VERSION ""

NS_ :

BS_:

BU_: DMC

BO_ 3221225472 VECTOR__INDEPENDENT_SIG_MSG: 0 Vector__XXX
 SG_ ICM_Cyc100_Fuel_State : 0|2@0+ (1,0) [0|3] "" Vector__XXX

BO_ 1944 Diag_DMC_RES: 8 DMC
 SG_ Diag_DMC_RES : 7|64@0+ (1,0) [0|0] "" Vector__XXX

BO_ 1928 Diag_DMC_REQ: 8 Vector__XXX
 SG_ Diag_DMC_REQ : 7|64@0+ (1,0) [0|0] ""  DMC

BO_ 2015 DIAG_OBD_REQ_Broadcast: 8 Vector__XXX
 SG_ DIAG_OBD_REQ_Broadcast : 7|64@0+ (1,0) [0|0] ""  DMC

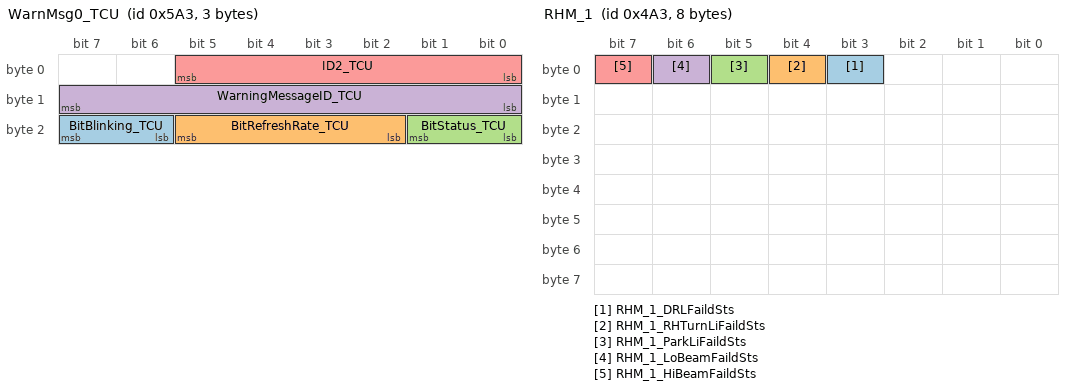
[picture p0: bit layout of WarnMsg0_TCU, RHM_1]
BO_ 1443 WarnMsg0_TCU: 3 Vector__XXX
 SG_ BitBlinking_TCU : 23|2@0+ (1,0) [0|3] ""  DMC
 SG_ BitRefreshRate_TCU : 21|4@0+ (1,0) [0|14] "second"  DMC
 SG_ BitStatus_TCU : 17|2@0+ (1,0) [0|3] ""  DMC
 SG_ WarningMessageID_TCU : 15|8@0+ (1,0) [0|255] ""  DMC
 SG_ ID2_TCU : 5|6@0+ (1,0) [0|63] ""  DMC

BO_ 798 TMR_2: 8 Vector__XXX
 SG_ TMR_TMRSysFault : 8|1@0+ (1,0) [0|1] ""  DMC

BO_ 1230 TMF_9: 8 Vector__XXX
 SG_ TMF_MILSts : 19|2@0+ (1,0) [0|3] ""  DMC

BO_ 789 TMF_2: 8 Vector__XXX
 SG_ TMF_SpdAct : 39|16@0+ (1,-32767) [-32767|32767] "rpm"  DMC
 SG_ TMF_TMFSysFault : 8|1@0+ (1,0) [0|1] ""  DMC

BO_ 1187 RHM_1: 8 Vector__XXX
 SG_ RHM_1_DRLFaildSts : 3|1@0+ (1,0) [0|1] ""  DMC
 SG_ RHM_1_RHTurnLiFaildSts : 4|1@0+ (1,0) [0|1] ""  DMC
 SG_ RHM_1_ParkLiFaildSts : 5|1@0+ (1,0) [0|1] ""  DMC
 SG_ RHM_1_LoBeamFaildSts : 6|1@0+ (1,0) [0|1] ""  DMC
 SG_ RHM_1_HiBeamFaildSts : 7|1@0+ (1,0) [0|1] ""  DMC

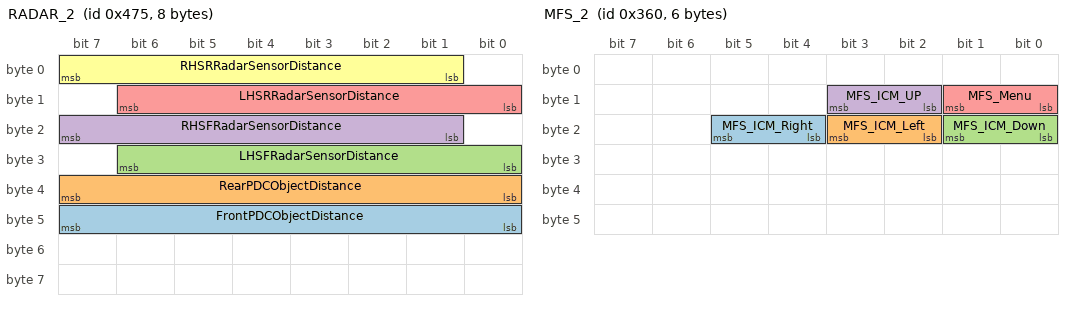
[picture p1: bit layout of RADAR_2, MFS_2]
BO_ 1141 RADAR_2: 8 Vector__XXX
 SG_ FrontPDCObjectDistance : 47|8@0+ (1,0) [0|120] "cm"  DMC
 SG_ RearPDCObjectDistance : 39|8@0+ (1,0) [0|150] "cm"  DMC
 SG_ LHSFRadarSensorDistance : 30|7@0+ (5,30) [30|500] "cm"  DMC
 SG_ RHSFRadarSensorDistance : 23|7@0+ (5,30) [30|500] "cm"  DMC
 SG_ LHSRRadarSensorDistance : 14|7@0+ (5,30) [30|500] "cm"  DMC
 SG_ RHSRRadarSensorDistance : 7|7@0+ (5,30) [30|500] "cm"  DMC

BO_ 864 MFS_2: 6 Vector__XXX
 SG_ MFS_ICM_Right : 21|2@0+ (1,0) [0|3] ""  DMC
 SG_ MFS_ICM_Left : 19|2@0+ (1,0) [0|3] ""  DMC
 SG_ MFS_ICM_Down : 17|2@0+ (1,0) [0|3] ""  DMC
 SG_ MFS_ICM_UP : 11|2@0+ (1,0) [0|3] ""  DMC
 SG_ MFS_Menu : 9|2@0+ (1,0) [0|3] ""  DMC

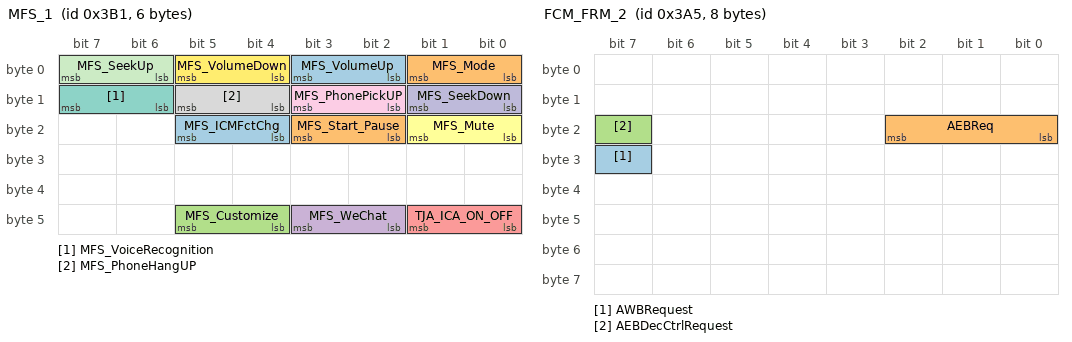
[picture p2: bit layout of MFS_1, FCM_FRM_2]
BO_ 945 MFS_1: 6 Vector__XXX
 SG_ MFS_ICMFctChg : 21|2@0+ (1,0) [0|3] ""  DMC
 SG_ MFS_Start_Pause : 19|2@0+ (1,0) [0|3] ""  DMC
 SG_ MFS_Customize : 45|2@0+ (1,0) [0|3] ""  DMC
 SG_ MFS_WeChat : 43|2@0+ (1,0) [0|3] ""  DMC
 SG_ TJA_ICA_ON_OFF : 41|2@0+ (1,0) [0|3] ""  DMC
 SG_ MFS_Mute : 17|2@0+ (1,0) [0|3] ""  DMC
 SG_ MFS_VoiceRecognition : 15|2@0+ (1,0) [0|3] ""  DMC
 SG_ MFS_PhoneHangUP : 13|2@0+ (1,0) [0|3] ""  DMC
 SG_ MFS_PhonePickUP : 11|2@0+ (1,0) [0|3] ""  DMC
 SG_ MFS_SeekDown : 9|2@0+ (1,0) [0|3] ""  DMC
 SG_ MFS_SeekUp : 7|2@0+ (1,0) [0|3] ""  DMC
 SG_ MFS_VolumeDown : 5|2@0+ (1,0) [0|3] ""  DMC
 SG_ MFS_VolumeUp : 3|2@0+ (1,0) [0|3] ""  DMC
 SG_ MFS_Mode : 1|2@0+ (1,0) [0|3] ""  DMC

BO_ 777 ISGF_2: 8 Vector__XXX
 SG_ ISGF_ISGFSysFault : 8|1@0+ (1,0) [0|1] ""  DMC

BO_ 933 FCM_FRM_2: 8 Vector__XXX
 SG_ AWBRequest : 31|1@0+ (1,0) [0|1] ""  DMC
 SG_ AEBReq : 18|3@0+ (1,0) [0|7] ""  DMC
 SG_ AEBDecCtrlRequest : 23|1@0+ (1,0) [0|1] ""  DMC

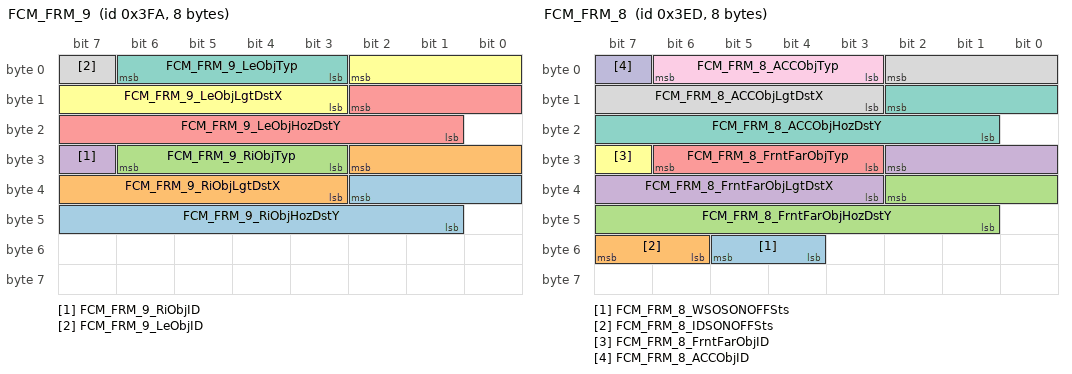
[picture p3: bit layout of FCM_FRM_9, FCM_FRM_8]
BO_ 1018 FCM_FRM_9: 8 Vector__XXX
 SG_ FCM_FRM_9_RiObjHozDstY : 34|10@0+ (0.1,-50) [-50|50] "m"  DMC
 SG_ FCM_FRM_9_RiObjLgtDstX : 26|8@0+ (0.5,0) [0|127] "m"  DMC
 SG_ FCM_FRM_9_RiObjTyp : 30|4@0+ (1,0) [0|15] ""  DMC
 SG_ FCM_FRM_9_RiObjID : 31|1@0+ (1,0) [0|1] ""  DMC
 SG_ FCM_FRM_9_LeObjHozDstY : 10|10@0+ (0.1,-50) [-50|50] "m"  DMC
 SG_ FCM_FRM_9_LeObjLgtDstX : 2|8@0+ (0.5,0) [0|127] "m"  DMC
 SG_ FCM_FRM_9_LeObjTyp : 6|4@0+ (1,0) [0|15] ""  DMC
 SG_ FCM_FRM_9_LeObjID : 7|1@0+ (1,0) [0|1] ""  DMC

BO_ 1005 FCM_FRM_8: 8 Vector__XXX
 SG_ FCM_FRM_8_WSOSONOFFSts : 53|2@0+ (1,0) [0|2] ""  DMC
 SG_ FCM_FRM_8_IDSONOFFSts : 55|2@0+ (1,0) [0|3] ""  DMC
 SG_ FCM_FRM_8_FrntFarObjHozDstY : 34|10@0+ (0.1,-50) [-50|50] "m"  DMC
 SG_ FCM_FRM_8_FrntFarObjLgtDstX : 26|8@0+ (0.5,0) [0|127] "m"  DMC
 SG_ FCM_FRM_8_FrntFarObjTyp : 30|4@0+ (1,0) [0|15] ""  DMC
 SG_ FCM_FRM_8_FrntFarObjID : 31|1@0+ (1,0) [0|1] ""  DMC
 SG_ FCM_FRM_8_ACCObjHozDstY : 10|10@0+ (0.1,-50) [-50|50] "m"  DMC
 SG_ FCM_FRM_8_ACCObjLgtDstX : 2|8@0+ (0.5,0) [0|127] "m"  DMC
 SG_ FCM_FRM_8_ACCObjTyp : 6|4@0+ (1,0) [0|15] ""  DMC
 SG_ FCM_FRM_8_ACCObjID : 7|1@0+ (1,0) [0|1] ""  DMC

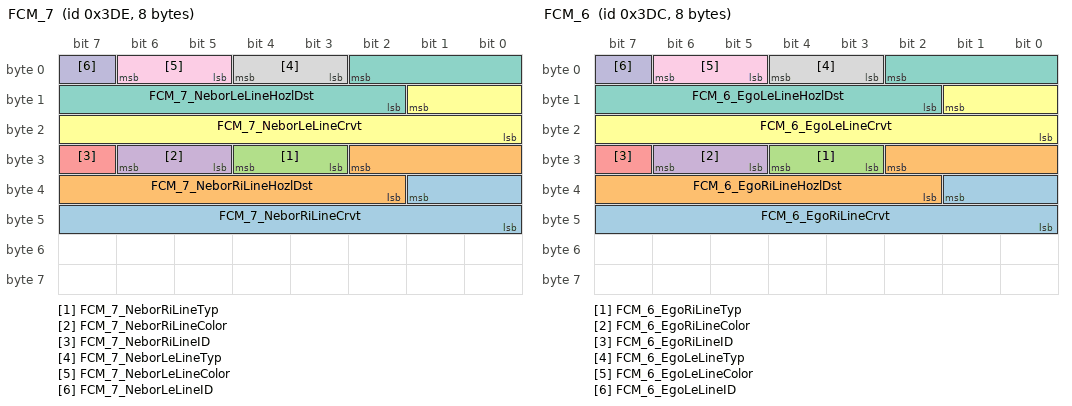
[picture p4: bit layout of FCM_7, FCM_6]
BO_ 990 FCM_7: 8 Vector__XXX
 SG_ FCM_7_NeborRiLineCrvt : 33|10@0+ (6E-005,-0.0156) [-0.0156|0.0156] "1/m"  DMC
 SG_ FCM_7_NeborRiLineHozlDst : 26|9@0+ (0.1,-25) [-25|25] "m"  DMC
 SG_ FCM_7_NeborRiLineTyp : 28|2@0+ (1,0) [0|3] ""  DMC
 SG_ FCM_7_NeborRiLineColor : 30|2@0+ (1,0) [0|3] ""  DMC
 SG_ FCM_7_NeborRiLineID : 31|1@0+ (1,0) [0|1] ""  DMC
 SG_ FCM_7_NeborLeLineCrvt : 9|10@0+ (6E-005,-0.0156) [-0.0156|0.0156] "1/m"  DMC
 SG_ FCM_7_NeborLeLineHozlDst : 2|9@0+ (0.1,-25) [-25|25] "m"  DMC
 SG_ FCM_7_NeborLeLineTyp : 4|2@0+ (1,0) [0|3] ""  DMC
 SG_ FCM_7_NeborLeLineColor : 6|2@0+ (1,0) [0|3] ""  DMC
 SG_ FCM_7_NeborLeLineID : 7|1@0+ (1,0) [0|1] ""  DMC

BO_ 988 FCM_6: 8 Vector__XXX
 SG_ FCM_6_EgoRiLineCrvt : 33|10@0+ (6E-005,-0.0156) [-0.0156|0.0156] "1/m"  DMC
 SG_ FCM_6_EgoRiLineHozlDst : 26|9@0+ (0.1,-25) [-25|25] "m"  DMC
 SG_ FCM_6_EgoRiLineTyp : 28|2@0+ (1,0) [0|3] ""  DMC
 SG_ FCM_6_EgoRiLineColor : 30|2@0+ (1,0) [0|3] ""  DMC
 SG_ FCM_6_EgoRiLineID : 31|1@0+ (1,0) [0|1] ""  DMC
 SG_ FCM_6_EgoLeLineCrvt : 9|10@0+ (6E-005,-0.0156) [-0.0156|0.0156] "1/m"  DMC
 SG_ FCM_6_EgoLeLineHozlDst : 2|9@0+ (0.1,-25) [-25|25] "m"  DMC
 SG_ FCM_6_EgoLeLineTyp : 4|2@0+ (1,0) [0|3] ""  DMC
 SG_ FCM_6_EgoLeLineColor : 6|2@0+ (1,0) [0|3] ""  DMC
 SG_ FCM_6_EgoLeLineID : 7|1@0+ (1,0) [0|1] ""  DMC

BO_ 1241 EMS_4_G: 8 Vector__XXX
 SG_ FuelTankLidSystemFailureSts : 18|1@0+ (1,0) [0|1] ""  DMC
 SG_ FuelTankPressureConditionReached : 20|2@0+ (1,0) [0|3] ""  DMC

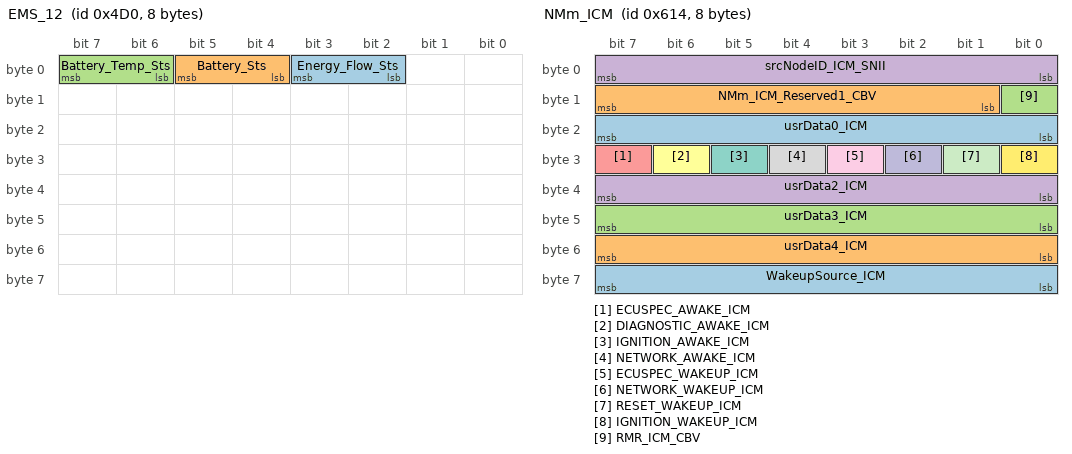
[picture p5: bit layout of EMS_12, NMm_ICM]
BO_ 1232 EMS_12: 8 Vector__XXX
 SG_ Energy_Flow_Sts : 3|2@0+ (1,0) [0|3] ""  DMC
 SG_ Battery_Sts : 5|2@0+ (1,0) [0|3] ""  DMC
 SG_ Battery_Temp_Sts : 7|2@0+ (1,0) [0|3] ""  DMC

BO_ 1146 EGS_2: 4 Vector__XXX
 SG_ AllWarningInfo : 5|3@0+ (1,0) [0|7] ""  DMC

BO_ 1054 DCDC_2: 8 Vector__XXX
 SG_ DCDC_DCDCSysFault : 52|1@0+ (1,0) [0|1] ""  DMC

BO_ 1048 DCDC_1: 8 Vector__XXX
 SG_ DCDC_EnableSts : 38|1@0+ (1,0) [0|1] ""  DMC
 SG_ DCDC_1_ActDisOutPower : 22|7@0+ (0.1,0) [0|10] "kW"  DMC

BO_ 1258 BMS_30: 8 Vector__XXX
 SG_ BMSH_BattFaultLampSts : 27|1@0+ (1,0) [0|1] ""  DMC
 SG_ BMSH_PackThermalRunawayLight : 26|1@0+ (1,0) [0|1] ""  DMC

BO_ 1450 BMS_12: 8 Vector__XXX
 SG_ BMSH_BatteryTempLightSts : 57|2@0+ (1,0) [0|3] ""  DMC
 SG_ BMSH_LowSOC : 47|2@0+ (1,0) [0|3] ""  DMC

BO_ 1158 AWD_2: 8 Vector__XXX
 SG_ AWDoutserviceDispRq : 7|2@0+ (1,0) [0|3] ""  DMC

BO_ 1095 AFS_1: 8 Vector__XXX
 SG_ AFS_FaultSts : 6|1@0+ (1,0) [0|1] ""  DMC

BO_ 745 ABS_ESP_1: 8 Vector__XXX
 SG_ AEBdecAvailable : 50|1@0+ (1,0) [0|1] ""  DMC
 SG_ AEBdecActive : 31|1@0+ (1,0) [0|1] ""  DMC

BO_ 1556 NMm_ICM: 8 DMC
 SG_ WakeupSource_ICM : 63|8@0+ (1,0) [0|255] "" Vector__XXX
 SG_ usrData4_ICM : 55|8@0+ (1,0) [0|255] "" Vector__XXX
 SG_ usrData3_ICM : 47|8@0+ (1,0) [0|255] "" Vector__XXX
 SG_ usrData2_ICM : 39|8@0+ (1,0) [0|255] "" Vector__XXX
 SG_ ECUSPEC_AWAKE_ICM : 31|1@0+ (1,0) [0|1] "" Vector__XXX
 SG_ DIAGNOSTIC_AWAKE_ICM : 30|1@0+ (1,0) [0|1] "" Vector__XXX
 SG_ IGNITION_AWAKE_ICM : 29|1@0+ (1,0) [0|1] "" Vector__XXX
 SG_ NETWORK_AWAKE_ICM : 28|1@0+ (1,0) [0|1] "" Vector__XXX
 SG_ ECUSPEC_WAKEUP_ICM : 27|1@0+ (1,0) [0|1] "" Vector__XXX
 SG_ NETWORK_WAKEUP_ICM : 26|1@0+ (1,0) [0|1] "" Vector__XXX
 SG_ RESET_WAKEUP_ICM : 25|1@0+ (1,0) [0|1] "" Vector__XXX
 SG_ IGNITION_WAKEUP_ICM : 24|1@0+ (1,0) [0|1] "" Vector__XXX
 SG_ usrData0_ICM : 23|8@0+ (1,0) [0|255] "" Vector__XXX
 SG_ NMm_ICM_Reserved1_CBV : 15|7@0+ (1,0) [0|127] "" Vector__XXX
 SG_ RMR_ICM_CBV : 8|1@0+ (1,0) [0|1] "" Vector__XXX
 SG_ srcNodeID_ICM_SNII : 7|8@0+ (1,0) [0|255] "" Vector__XXX

BO_ 1090 SCU_1: 8 Vector__XXX
 SG_ SCU_1_LuggageModFlagSts : 47|2@0+ (1,0) [0|3] ""  DMC
 SG_ SCU_1_JourneyModFlagSts : 33|2@0+ (1,0) [0|3] ""  DMC
 SG_ SCU_1_SmartSpaceWarn : 34|1@0+ (1,0) [0|1] ""  DMC
 SG_ SCU_1_ModCheckFb : 37|2@0+ (1,0) [0|3] ""  DMC
 SG_ SCU_1_BedModFlagSts : 39|2@0+ (1,0) [0|3] ""  DMC
 SG_ SCU_1_FRSeatVentilationFbSts : 29|2@0+ (1,0) [0|3] ""  DMC
 SG_ SCU_1_FLSeatVentilationFbSts : 31|2@0+ (1,0) [0|3] ""  DMC
 SG_ Seat_ExtMirror_PositionInfo : 23|5@0+ (1,0) [0|31] ""  DMC
 SG_ SCURelateKeyOrFaceIDFeedbackSts : 8|1@0+ (1,0) [0|1] ""  DMC
 SG_ Seat_ExtMirror_MemorySts : 10|2@0+ (1,0) [0|3] ""  DMC
 SG_ SCU_1_FRSeatHeatFbSts : 13|2@0+ (1,0) [0|3] ""  DMC
 SG_ SCU_1_FLSeatHeatFbSts : 15|2@0+ (1,0) [0|3] ""  DMC
 SG_ ReverseExtMirrorFeedbackSts : 2|2@0+ (1,0) [0|3] ""  DMC
 SG_ EasyEntryFeedbackSts : 3|1@0+ (1,0) [0|1] ""  DMC
 SG_ Seat_ExtMirror_MemoryReq : 4|1@0+ (1,0) [0|1] ""  DMC
 SG_ Seat_ExtMirror_MemoryEnable : 5|1@0+ (1,0) [0|1] ""  DMC
 SG_ MemoryKeySts : 0|1@0+ (1,0) [0|1] ""  DMC

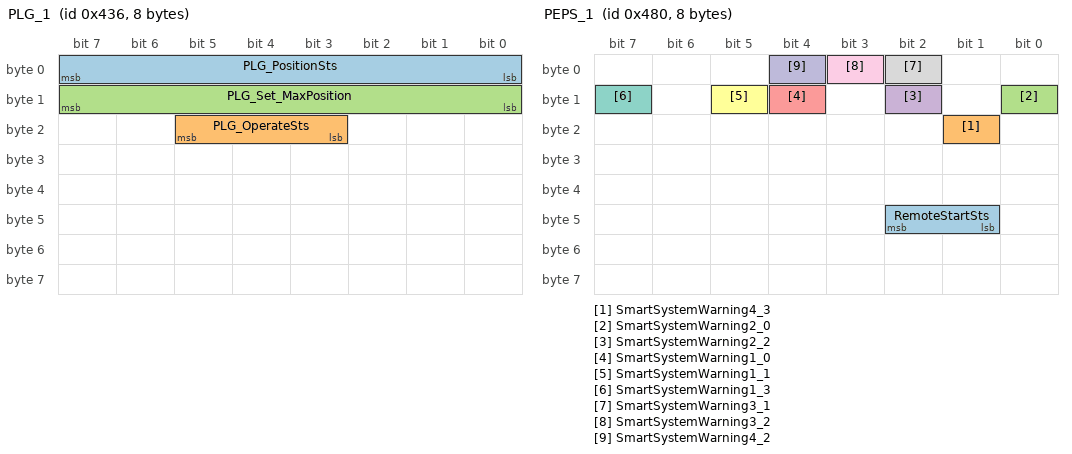
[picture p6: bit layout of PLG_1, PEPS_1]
BO_ 1078 PLG_1: 8 Vector__XXX
 SG_ PLG_PositionSts : 7|8@0+ (1,0) [0|100] "%"  DMC
 SG_ PLG_OperateSts : 21|3@0+ (1,0) [0|7] ""  DMC
 SG_ PLG_Set_MaxPosition : 15|8@0+ (1,0) [0|100] "%"  DMC

BO_ 1152 PEPS_1: 8 Vector__XXX
 SG_ RemoteStartSts : 42|2@0+ (1,0) [0|3] ""  DMC
 SG_ SmartSystemWarning4_3 : 17|1@0+ (1,0) [0|1] ""  DMC
 SG_ SmartSystemWarning2_0 : 8|1@0+ (1,0) [0|1] ""  DMC
 SG_ SmartSystemWarning2_2 : 10|1@0+ (1,0) [0|1] ""  DMC
 SG_ SmartSystemWarning1_0 : 12|1@0+ (1,0) [0|1] ""  DMC
 SG_ SmartSystemWarning1_1 : 13|1@0+ (1,0) [0|1] ""  DMC
 SG_ SmartSystemWarning1_3 : 15|1@0+ (1,0) [0|1] ""  DMC
 SG_ SmartSystemWarning3_1 : 2|1@0+ (1,0) [0|1] ""  DMC
 SG_ SmartSystemWarning3_2 : 3|1@0+ (1,0) [0|1] ""  DMC
 SG_ SmartSystemWarning4_2 : 4|1@0+ (1,0) [0|1] ""  DMC

BO_ 1219 PAS_1: 8 Vector__XXX
 SG_ PAS_1_DriverDoorSIllSts : 0|1@0+ (1,0) [0|1] ""  DMC

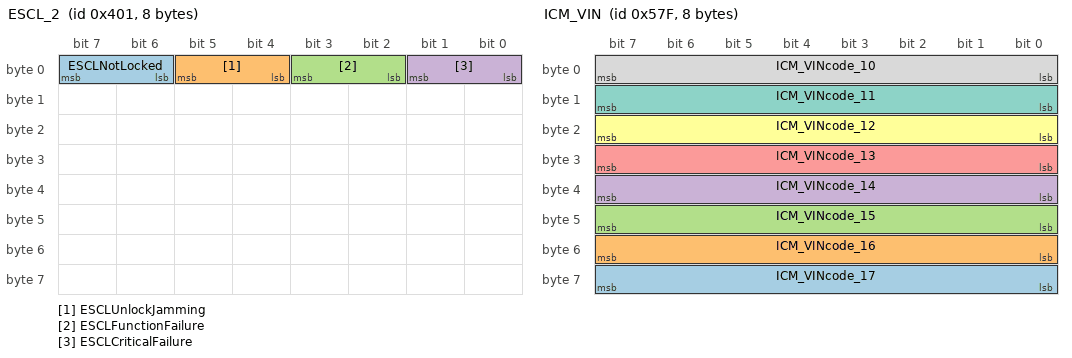
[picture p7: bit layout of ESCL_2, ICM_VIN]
BO_ 1025 ESCL_2: 8 Vector__XXX
 SG_ ESCLNotLocked : 7|2@0+ (1,0) [0|1] ""  DMC
 SG_ ESCLUnlockJamming : 5|2@0+ (1,0) [0|1] ""  DMC
 SG_ ESCLFunctionFailure : 3|2@0+ (1,0) [0|1] ""  DMC
 SG_ ESCLCriticalFailure : 1|2@0+ (1,0) [0|1] ""  DMC

BO_ 1407 ICM_VIN: 8 DMC
 SG_ ICM_VINcode_17 : 63|8@0+ (1,0) [0|127] "" Vector__XXX
 SG_ ICM_VINcode_16 : 55|8@0+ (1,0) [0|127] "" Vector__XXX
 SG_ ICM_VINcode_15 : 47|8@0+ (1,0) [0|127] "" Vector__XXX
 SG_ ICM_VINcode_14 : 39|8@0+ (1,0) [0|127] "" Vector__XXX
 SG_ ICM_VINcode_13 : 31|8@0+ (1,0) [0|127] "" Vector__XXX
 SG_ ICM_VINcode_12 : 23|8@0+ (1,0) [0|127] "" Vector__XXX
 SG_ ICM_VINcode_11 : 15|8@0+ (1,0) [0|127] "" Vector__XXX
 SG_ ICM_VINcode_10 : 7|8@0+ (1,0) [0|127] "" Vector__XXX

BO_ 1322 ICM_10: 8 DMC
 SG_ Sigcycfucns : 23|8@0+ (0.1,0) [0|25.4] "L/100km" Vector__XXX
 SG_ ResidualOdometer_PHEV : 7|12@0+ (1,0) [0|4000] "km" Vector__XXX

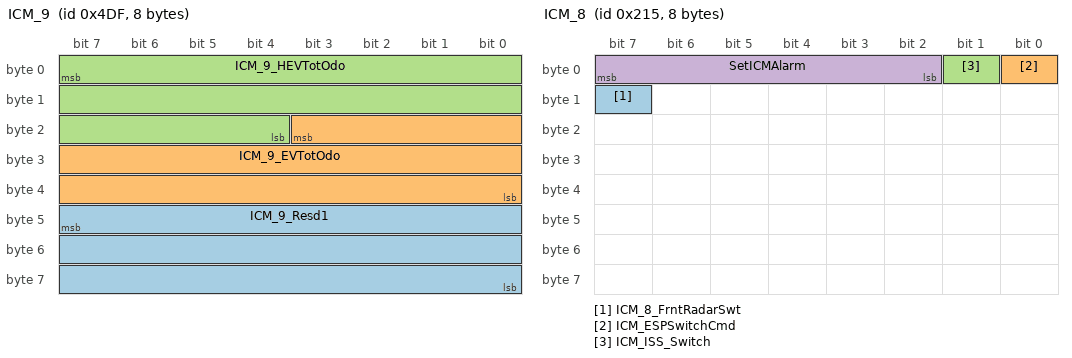
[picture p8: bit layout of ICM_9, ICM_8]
BO_ 1247 ICM_9: 8 DMC
 SG_ ICM_9_Resd1 : 47|24@0+ (1,0) [0|0] "" Vector__XXX
 SG_ ICM_9_EVTotOdo : 19|20@0+ (1,0) [0|999999] "km" Vector__XXX
 SG_ ICM_9_HEVTotOdo : 7|20@0+ (1,0) [0|999999] "km" Vector__XXX

BO_ 533 ICM_8: 8 DMC
 SG_ ICM_8_FrntRadarSwt : 15|1@0+ (1,0) [0|1] "" Vector__XXX
 SG_ ICM_ESPSwitchCmd : 0|1@0+ (1,0) [0|1] "" Vector__XXX
 SG_ ICM_ISS_Switch : 1|1@0+ (1,0) [0|1] "" Vector__XXX
 SG_ SetICMAlarm : 7|6@0+ (1,0) [0|63] "" Vector__XXX

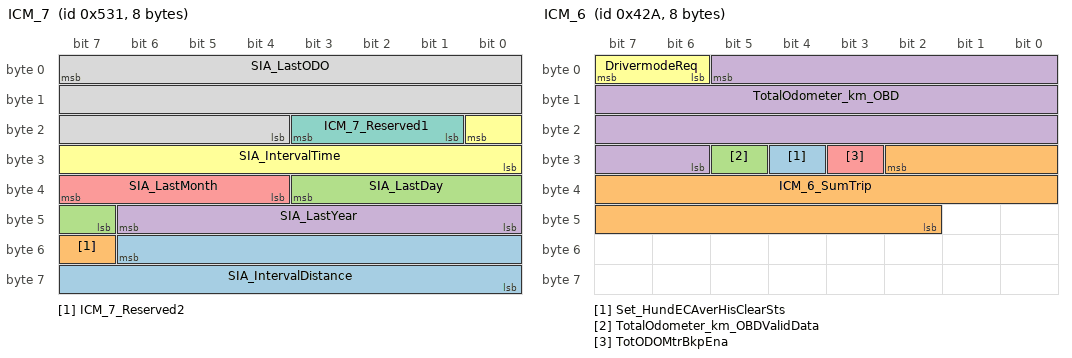
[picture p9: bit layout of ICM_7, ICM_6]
BO_ 1329 ICM_7: 8 DMC
 SG_ SIA_IntervalDistance : 54|15@0+ (1,0) [0|16383] "km" Vector__XXX
 SG_ ICM_7_Reserved2 : 55|1@0+ (1,0) [0|0] "" Vector__XXX
 SG_ SIA_LastDay : 35|5@0+ (1,0) [0|31] "day" Vector__XXX
 SG_ SIA_LastYear : 46|7@0+ (1,2000) [2000|2101] "year" Vector__XXX
 SG_ SIA_LastMonth : 39|4@0+ (1,0) [0|12] "month" Vector__XXX
 SG_ SIA_IntervalTime : 16|9@0+ (1,0) [0|365] "day" Vector__XXX
 SG_ ICM_7_Reserved1 : 19|3@0+ (1,0) [0|0] "" Vector__XXX
 SG_ SIA_LastODO : 7|20@0+ (1,0) [0|999999] "km" Vector__XXX

BO_ 1066 ICM_6: 8 DMC
 SG_ Set_HundECAverHisClearSts : 28|1@0+ (1,0) [0|1] "" Vector__XXX
 SG_ ICM_6_SumTrip : 26|17@0+ (0.1,0) [0|9999.9] "" Vector__XXX
 SG_ TotalOdometer_km_OBDValidData : 29|1@0+ (1,0) [0|1] "" Vector__XXX
 SG_ TotalOdometer_km_OBD : 5|24@0+ (0.1,0) [0|999999.9] "km" Vector__XXX
 SG_ TotODOMtrBkpEna : 27|1@0+ (1,0) [0|1] "" Vector__XXX
 SG_ DrivermodeReq : 7|2@0+ (1,0) [0|3] "" Vector__XXX

BO_ 647 ICM_5: 8 DMC
 SG_ ICM_5_Checksum : 63|8@0+ (1,0) [0|255] "" Vector__XXX
 SG_ ICM_5_MessageCounter : 51|4@0+ (1,0) [0|15] "" Vector__XXX
 SG_ ICM_DVDAudibleAlarmStyle : 34|2@0+ (1,0) [0|3] "" Vector__XXX
 SG_ ICM_DVDAudibleAlarm : 38|4@0+ (1,0) [0|15] "" Vector__XXX
 SG_ BrakeFluidWarning : 32|1@0+ (1,0) [0|1] "" Vector__XXX
 SG_ ICM_5_Reserved_2 : 47|10@0+ (1,0) [0|0] "" Vector__XXX
 SG_ ACC_Kilometre_Mile : 39|1@0+ (1,0) [0|1] "" Vector__XXX
 SG_ DriverSeatBeltSwitchQbit : 24|1@0+ (1,0) [0|1] "" Vector__XXX
 SG_ ICM_5_DriverSeatBeltSwitch : 25|1@0+ (1,0) [0|1] "" Vector__XXX
 SG_ CTP_DriveModeSet : 30|1@0+ (1,0) [0|1] "" Vector__XXX
 SG_ ICM_5_AlrmVolCtrl : 29|2@0+ (1,0) [0|3] "" Vector__XXX
 SG_ ICM_5_BackLiBriAdjmt : 27|2@0+ (1,0) [0|3] "" Vector__XXX
 SG_ AverageFuelConsumption50 : 23|9@0+ (0.1,0) [0|50] "L/100km" Vector__XXX
 SG_ ICM_5_FuelLevel : 15|8@0+ (1,0) [0|100] "%" Vector__XXX
 SG_ FuelValidData : 0|1@0+ (1,0) [0|1] "" Vector__XXX
 SG_ FuelOutOfRange : 1|1@0+ (1,0) [0|1] "" Vector__XXX
 SG_ FuelShortPower : 2|1@0+ (1,0) [0|1] "" Vector__XXX
 SG_ FuelShortGround : 3|1@0+ (1,0) [0|1] "" Vector__XXX
 SG_ HandBrakeSystemStsValidData : 4|1@0+ (1,0) [0|1] "" Vector__XXX
 SG_ HandBrakeSystemSts : 7|3@0+ (1,0) [0|7] "" Vector__XXX

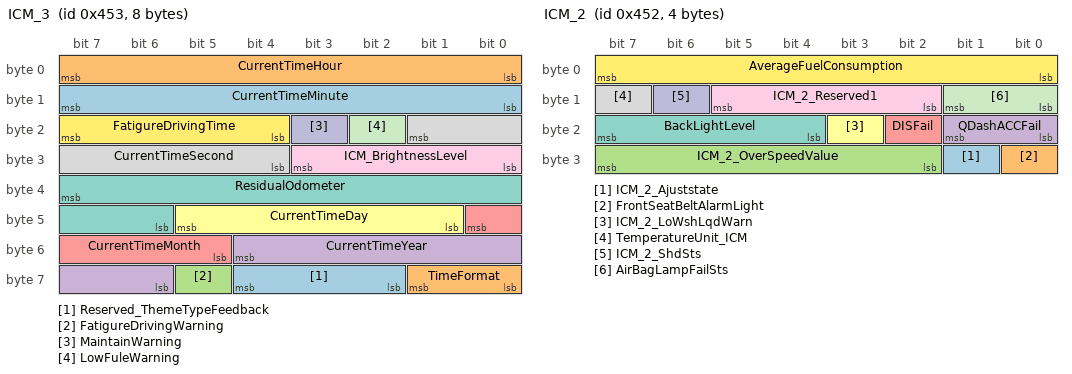
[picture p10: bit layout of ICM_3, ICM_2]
BO_ 1107 ICM_3: 8 DMC
 SG_ Reserved_ThemeTypeFeedback : 60|3@0+ (1,0) [0|0] "" Vector__XXX
 SG_ TimeFormat : 57|2@0+ (1,0) [0|3] "" Vector__XXX
 SG_ FatigureDrivingWarning : 61|1@0+ (1,0) [0|1] "" Vector__XXX
 SG_ CurrentTimeYear : 52|7@0+ (1,2000) [2000|2127] "" Vector__XXX
 SG_ CurrentTimeMonth : 40|4@0+ (1,0) [1|12] "" Vector__XXX
 SG_ CurrentTimeDay : 45|5@0+ (1,0) [1|31] "" Vector__XXX
 SG_ ResidualOdometer : 39|10@0+ (1,0) [0|999] "km" Vector__XXX
 SG_ CurrentTimeSecond : 17|6@0+ (1,0) [0|59] "" Vector__XXX
 SG_ ICM_BrightnessLevel : 27|4@0+ (1,0) [0|15] "" Vector__XXX
 SG_ MaintainWarning : 19|1@0+ (1,0) [0|1] "" Vector__XXX
 SG_ LowFuleWarning : 18|1@0+ (1,0) [0|1] "" Vector__XXX
 SG_ FatigureDrivingTime : 23|4@0+ (1,0) [0|15] "" Vector__XXX
 SG_ CurrentTimeMinute : 15|8@0+ (1,0) [0|59] "" Vector__XXX
 SG_ CurrentTimeHour : 7|8@0+ (1,0) [0|23] "" Vector__XXX

BO_ 1106 ICM_2: 4 DMC
 SG_ ICM_2_Ajuststate : 25|1@0+ (1,0) [0|1] "" Vector__XXX
 SG_ FrontSeatBeltAlarmLight : 24|1@0+ (1,0) [0|1] "" Vector__XXX
 SG_ ICM_2_OverSpeedValue : 31|6@0+ (1,0) [0|63] "" Vector__XXX
 SG_ QDashACCFail : 17|2@0+ (1,0) [0|3] "" Vector__XXX
 SG_ DISFail : 18|1@0+ (1,0) [0|1] "" Vector__XXX
 SG_ ICM_2_LoWshLqdWarn : 19|1@0+ (1,0) [0|1] "" Vector__XXX
 SG_ BackLightLevel : 23|4@0+ (1,0) [0|15] "" Vector__XXX
 SG_ TemperatureUnit_ICM : 15|1@0+ (1,0) [0|1] "" Vector__XXX
 SG_ ICM_2_Reserved1 : 13|4@0+ (1,0) [0|0] "" Vector__XXX
 SG_ ICM_2_ShdSts : 14|1@0+ (1,0) [0|1] "" Vector__XXX
 SG_ AirBagLampFailSts : 9|2@0+ (1,0) [0|3] "" Vector__XXX
 SG_ AverageFuelConsumption : 7|8@0+ (0.1,0) [0|25.4] "L/100km" Vector__XXX

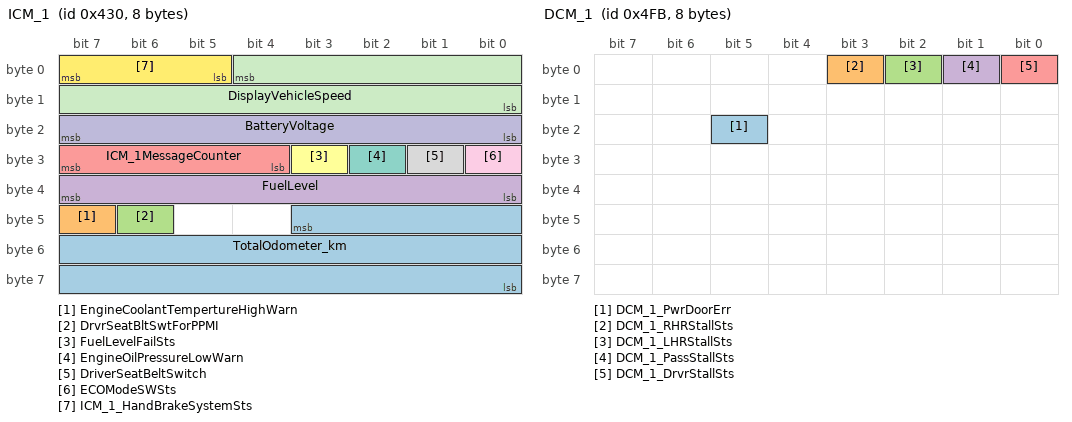
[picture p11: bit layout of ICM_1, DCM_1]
BO_ 1072 ICM_1: 8 DMC
 SG_ TotalOdometer_km : 43|20@0+ (1,0) [0|999999] "km" Vector__XXX
 SG_ EngineCoolantTempertureHighWarn : 47|1@0+ (1,0) [0|1] "" Vector__XXX
 SG_ DrvrSeatBltSwtForPPMI : 46|1@0+ (1,0) [0|1] "" Vector__XXX
 SG_ FuelLevel : 39|8@0+ (1,0) [0|100] "%" Vector__XXX
 SG_ ICM_1MessageCounter : 31|4@0+ (1,0) [0|15] "" Vector__XXX
 SG_ FuelLevelFailSts : 27|1@0+ (1,0) [0|1] "" Vector__XXX
 SG_ EngineOilPressureLowWarn : 26|1@0+ (1,0) [0|1] "" Vector__XXX
 SG_ DriverSeatBeltSwitch : 25|1@0+ (1,0) [0|1] "" Vector__XXX
 SG_ ECOModeSWSts : 24|1@0+ (1,0) [0|1] "" Vector__XXX
 SG_ BatteryVoltage : 23|8@0+ (0.1,0) [0|25.4] "V" Vector__XXX
 SG_ DisplayVehicleSpeed : 4|13@0+ (0.0625,0) [0|511.875] "km/h" Vector__XXX
 SG_ ICM_1_HandBrakeSystemSts : 7|3@0+ (1,0) [0|7] "" Vector__XXX

BO_ 1275 DCM_1: 8 Vector__XXX
 SG_ DCM_1_PwrDoorErr : 21|1@0+ (1,0) [0|1] ""  DMC
 SG_ DCM_1_RHRStallSts : 3|1@0+ (1,0) [0|1] ""  DMC
 SG_ DCM_1_LHRStallSts : 2|1@0+ (1,0) [0|1] ""  DMC
 SG_ DCM_1_PassStallSts : 1|1@0+ (1,0) [0|1] ""  DMC
 SG_ DCM_1_DrvrStallSts : 0|1@0+ (1,0) [0|1] ""  DMC

BO_ 1306 CLM_1: 8 Vector__XXX
 SG_ SetTemperature_R_F : 61|5@0+ (2,58) [58|90] "℉"  DMC
 SG_ SetTemperature_L_F : 50|5@0+ (2,58) [58|90] "℉"  DMC
 SG_ SelfTestResult : 55|5@0+ (1,0) [0|31] ""  DMC
 SG_ ZoneSelectionDisplaySts : 41|1@0+ (1,0) [0|1] ""  DMC
 SG_ CirculationModeDisplaySts : 42|1@0+ (1,0) [0|1] ""  DMC
 SG_ SetTemperature_R_C : 47|5@0+ (1,15) [15|31] "℃"  DMC
 SG_ SetTemperature_L_C : 39|5@0+ (1,15) [15|31] "℃"  DMC
 SG_ BlowDelayOffSts : 34|1@0+ (1,0) [0|1] ""  DMC
 SG_ BlowAdvanceOnSts : 33|1@0+ (1,0) [0|1] ""  DMC
 SG_ DisplayActive : 32|1@0+ (1,0) [0|1] ""  DMC
 SG_ SelfTestActive : 27|1@0+ (1,0) [0|1] ""  DMC
 SG_ PM2_5Sts : 26|1@0+ (1,0) [0|1] ""  DMC
 SG_ WorkingSts : 25|1@0+ (1,0) [0|1] ""  DMC
 SG_ ModeAdjustDisplaySts : 30|3@0+ (1,0) [0|7] ""  DMC
 SG_ FrontDeforest_MaxDisplaySts : 31|1@0+ (1,0) [0|1] ""  DMC
 SG_ ACRequestDisplaySts : 19|1@0+ (1,0) [0|1] ""  DMC
 SG_ AutoDisplaySts : 20|1@0+ (1,0) [0|1] ""  DMC
 SG_ AC_MaxSts : 22|1@0+ (1,0) [0|1] ""  DMC
 SG_ TemperatureUnit : 40|1@0+ (1,0) [0|1] ""  DMC
 SG_ ExternalTemperatureFailSts : 23|1@0+ (1,0) [0|1] ""  DMC
 SG_ ExternalTemperature_C : 15|8@0+ (0.5,-55) [-55|70] "°C"  DMC
 SG_ ExternalTemperature_F : 7|8@0+ (1,-67) [-67|158] "°F"  DMC

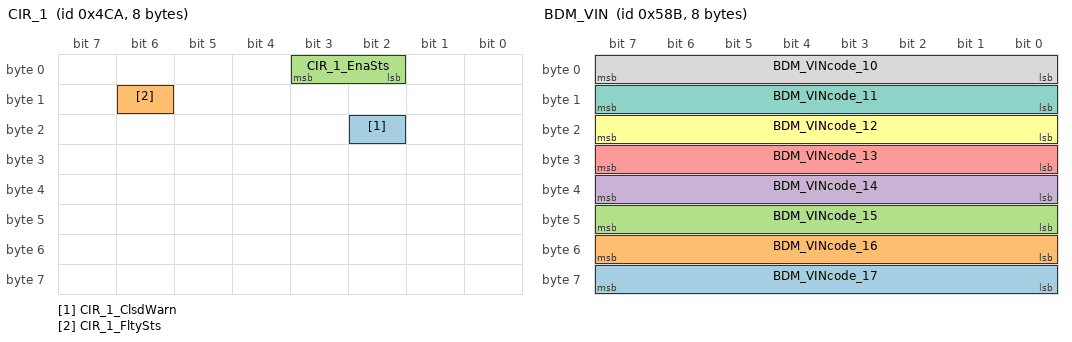
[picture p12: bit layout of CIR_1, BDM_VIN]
BO_ 1226 CIR_1: 8 Vector__XXX
 SG_ CIR_1_ClsdWarn : 18|1@0+ (1,0) [0|1] ""  DMC
 SG_ CIR_1_FltySts : 14|1@0+ (1,0) [0|1] ""  DMC
 SG_ CIR_1_EnaSts : 3|2@0+ (1,0) [0|3] ""  DMC

BO_ 1419 BDM_VIN: 8 Vector__XXX
 SG_ BDM_VINcode_17 : 63|8@0+ (1,0) [0|127] ""  DMC
 SG_ BDM_VINcode_16 : 55|8@0+ (1,0) [0|127] ""  DMC
 SG_ BDM_VINcode_15 : 47|8@0+ (1,0) [0|127] ""  DMC
 SG_ BDM_VINcode_14 : 39|8@0+ (1,0) [0|127] ""  DMC
 SG_ BDM_VINcode_13 : 31|8@0+ (1,0) [0|127] ""  DMC
 SG_ BDM_VINcode_12 : 23|8@0+ (1,0) [0|127] ""  DMC
 SG_ BDM_VINcode_11 : 15|8@0+ (1,0) [0|127] ""  DMC
 SG_ BDM_VINcode_10 : 7|8@0+ (1,0) [0|127] ""  DMC

BO_ 1481 BDM_28: 8 Vector__XXX
 SG_ BDM_28_EVTotOdoBkp : 43|20@0+ (1,0) [0|999999] "km"  DMC

BO_ 1224 BDM_21: 8 Vector__XXX
 SG_ BDM_21_CRC : 63|8@0+ (1,0) [0|255] ""  DMC
 SG_ BDM_21_MessageCounter : 51|4@0+ (1,0) [0|15] ""  DMC
 SG_ BDM_21_TotLampFailSts : 21|1@0+ (1,0) [0|1] ""  DMC
 SG_ BCM_RRPLMfailsts : 8|1@0+ (1,0) [0|1] ""  DMC
 SG_ BCM_RRFLMfailsts : 9|1@0+ (1,0) [0|1] ""  DMC
 SG_ BCM_RLPLMfailsts : 10|1@0+ (1,0) [0|1] ""  DMC
 SG_ BCM_RLFLMfailsts : 11|1@0+ (1,0) [0|1] ""  DMC
 SG_ BCM_RHMfailsts : 12|1@0+ (1,0) [0|1] ""  DMC
 SG_ BCM_LHMfailsts : 13|1@0+ (1,0) [0|1] ""  DMC
 SG_ ReFogLiFaildSts : 14|1@0+ (1,0) [0|1] ""  DMC
 SG_ ReversinglampFaultSts : 15|1@0+ (1,0) [0|1] ""  DMC
 SG_ BrakelampFaultSts : 0|1@0+ (1,0) [0|1] ""  DMC
 SG_ FrntFogFaildSts : 1|1@0+ (1,0) [0|1] ""  DMC
 SG_ DRLFaildSts : 2|1@0+ (1,0) [0|1] ""  DMC
 SG_ BDM_21_RHTurnlightSts : 3|1@0+ (1,0) [0|1] ""  DMC
 SG_ BDM_21_LHTurnlightSts : 4|1@0+ (1,0) [0|1] ""  DMC
 SG_ ParkLiFaildSts : 5|1@0+ (1,0) [0|1] ""  DMC
 SG_ LoBeamFaildSts : 6|1@0+ (1,0) [0|1] ""  DMC
 SG_ HiBeamFaildSts : 7|1@0+ (1,0) [0|1] ""  DMC

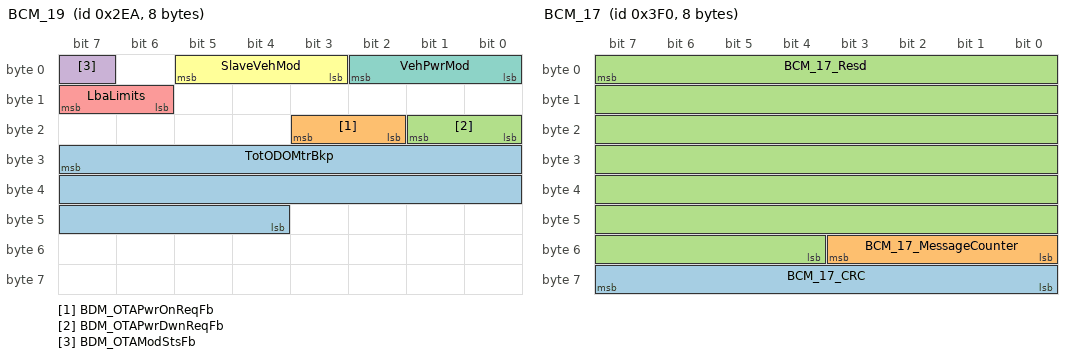
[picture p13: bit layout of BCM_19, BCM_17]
BO_ 746 BCM_19: 8 Vector__XXX
 SG_ TotODOMtrBkp : 31|20@0+ (1,0) [0|999999] "km"  DMC
 SG_ BDM_OTAPwrOnReqFb : 19|2@0+ (1,0) [0|3] ""  DMC
 SG_ BDM_OTAPwrDwnReqFb : 17|2@0+ (1,0) [0|3] ""  DMC
 SG_ BDM_OTAModStsFb : 7|1@0+ (1,0) [0|1] ""  DMC
 SG_ LbaLimits : 15|2@0+ (1,0) [0|3] ""  DMC
 SG_ SlaveVehMod : 5|3@0+ (1,0) [0|7] ""  DMC
 SG_ VehPwrMod : 2|3@0+ (1,0) [0|7] ""  DMC

BO_ 1008 BCM_17: 8 Vector__XXX
 SG_ BCM_17_CRC : 63|8@0+ (1,0) [0|255] ""  DMC
 SG_ BCM_17_MessageCounter : 51|4@0+ (1,0) [0|15] ""  DMC
 SG_ BCM_17_Resd : 7|52@0+ (1,0) [0|0] ""  DMC

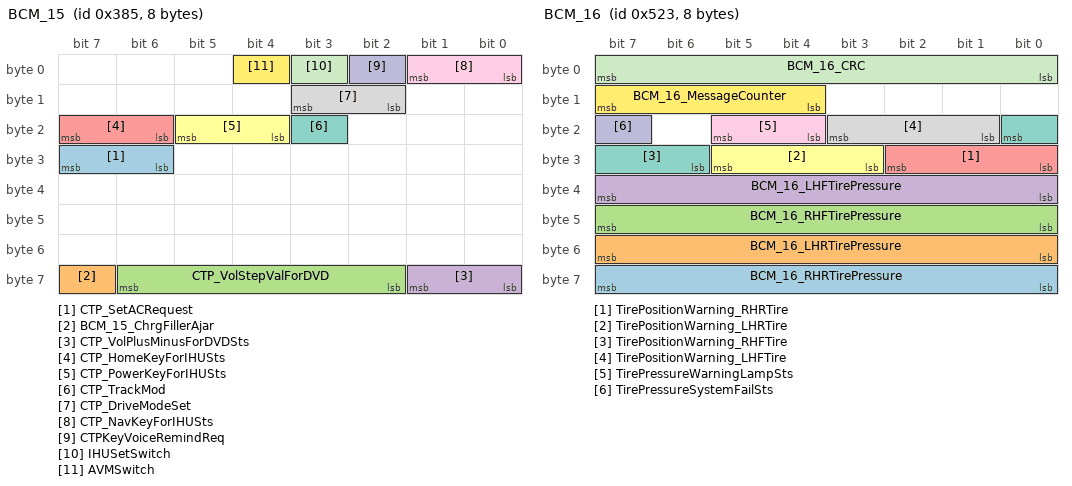
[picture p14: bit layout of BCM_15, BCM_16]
BO_ 901 BCM_15: 8 Vector__XXX
 SG_ CTP_SetACRequest : 31|2@0+ (1,0) [0|3] ""  DMC
 SG_ BCM_15_ChrgFillerAjar : 63|1@0+ (1,0) [0|1] ""  DMC
 SG_ CTP_VolStepValForDVD : 62|5@0+ (1,0) [0|31] "Grid"  DMC
 SG_ CTP_VolPlusMinusForDVDSts : 57|2@0+ (1,0) [0|3] ""  DMC
 SG_ CTP_HomeKeyForIHUSts : 23|2@0+ (1,0) [0|3] ""  DMC
 SG_ CTP_PowerKeyForIHUSts : 21|2@0+ (1,0) [0|3] ""  DMC
 SG_ CTP_TrackMod : 19|1@0+ (1,0) [0|1] ""  DMC
 SG_ CTP_DriveModeSet : 11|2@0+ (1,0) [0|3] ""  DMC
 SG_ CTP_NavKeyForIHUSts : 1|2@0+ (1,0) [0|3] ""  DMC
 SG_ CTPKeyVoiceRemindReq : 2|1@0+ (1,0) [0|1] ""  DMC
 SG_ IHUSetSwitch : 3|1@0+ (1,0) [0|1] ""  DMC
 SG_ AVMSwitch : 4|1@0+ (1,0) [0|1] ""  DMC

BO_ 1315 BCM_16: 8 Vector__XXX
 SG_ BCM_16_RHRTirePressure : 63|8@0+ (1.373,0) [0|350] "kPa"  DMC
 SG_ BCM_16_LHRTirePressure : 55|8@0+ (1.373,0) [0|350] "kPa"  DMC
 SG_ BCM_16_RHFTirePressure : 47|8@0+ (1.373,0) [0|350] "kPa"  DMC
 SG_ BCM_16_LHFTirePressure : 39|8@0+ (1.373,0) [0|350] "kPa"  DMC
 SG_ TirePositionWarning_RHRTire : 26|3@0+ (1,0) [0|7] ""  DMC
 SG_ TirePositionWarning_LHRTire : 29|3@0+ (1,0) [0|7] ""  DMC
 SG_ TirePositionWarning_RHFTire : 16|3@0+ (1,0) [0|7] ""  DMC
 SG_ TirePositionWarning_LHFTire : 19|3@0+ (1,0) [0|7] ""  DMC
 SG_ TirePressureWarningLampSts : 21|2@0+ (1,0) [0|3] ""  DMC
 SG_ TirePressureSystemFailSts : 23|1@0+ (1,0) [0|1] ""  DMC
 SG_ BCM_16_CRC : 7|8@0+ (1,0) [0|255] ""  DMC
 SG_ BCM_16_MessageCounter : 15|4@0+ (1,0) [0|15] ""  DMC

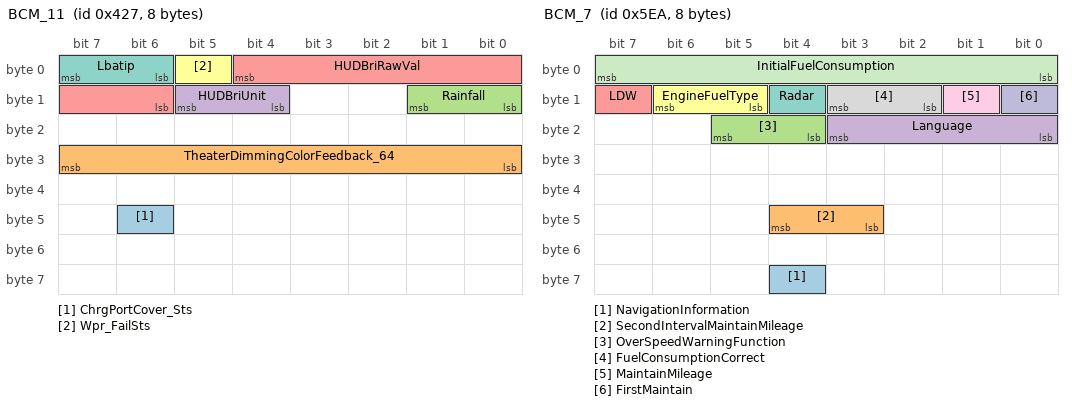
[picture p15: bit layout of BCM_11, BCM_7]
BO_ 1063 BCM_11: 8 Vector__XXX
 SG_ ChrgPortCover_Sts : 46|1@0+ (1,0) [0|1] ""  DMC
 SG_ TheaterDimmingColorFeedback_64 : 31|8@0+ (1,0) [0|255] ""  DMC
 SG_ Rainfall : 9|2@0+ (1,0) [0|3] ""  DMC
 SG_ HUDBriUnit : 13|2@0+ (1,0) [0|3] ""  DMC
 SG_ HUDBriRawVal : 4|7@0+ (1,0) [0|126] ""  DMC
 SG_ Wpr_FailSts : 5|1@0+ (1,0) [0|1] ""  DMC
 SG_ Lbatip : 7|2@0+ (1,0) [0|3] ""  DMC

BO_ 1520 BCM_10: 8 Vector__XXX
 SG_ BCM_10_MessageCounter_10 m10 : 59|4@0+ (1,0) [0|15] ""  DMC
 SG_ BCM_10_MessageCounter_9 m9 : 59|4@0+ (1,0) [0|15] ""  DMC
 SG_ BCM_10_MessageCounter_8 m8 : 59|4@0+ (1,0) [0|15] ""  DMC
 SG_ BCM_10_MessageCounter_7 m7 : 59|4@0+ (1,0) [0|15] ""  DMC
 SG_ BCM_10_MessageCounter_6 m6 : 59|4@0+ (1,0) [0|15] ""  DMC
 SG_ BCM_10_MessageCounter_5 m5 : 59|4@0+ (1,0) [0|15] ""  DMC
 SG_ BCM_10_MessageCounter_4 m4 : 59|4@0+ (1,0) [0|15] ""  DMC
 SG_ BCM_10_MessageCounter_3 m3 : 59|4@0+ (1,0) [0|15] ""  DMC
 SG_ BCM_10_MessageCounter_2 m2 : 59|4@0+ (1,0) [0|15] ""  DMC
 SG_ BCM_10_MessageCounter_1 m1 : 59|4@0+ (1,0) [0|15] ""  DMC
 SG_ ICMVehicleType m4 : 15|4@0+ (1,0) [0|15] ""  DMC
 SG_ Third_Row_SBR_Buckle_switch m3 : 43|1@0+ (1,0) [0|1] ""  DMC
 SG_ Second_Row_SBR_Buckle_switch m3 : 41|1@0+ (1,0) [0|1] ""  DMC
 SG_ LKA m2 : 47|1@0+ (1,0) [0|1] ""  DMC
 SG_ EGS m1 : 8|1@0+ (1,0) [0|1] ""  DMC
 SG_ BCM_10_Signal1 M : 3|4@0+ (1,0) [1|10] ""  DMC

BO_ 1077 BCM_9: 8 Vector__XXX
 SG_ RvsExtMirrFbSts : 57|2@0+ (1,0) [0|3] ""  DMC
 SG_ SRF_Hall2SensorError : 47|1@0+ (1,0) [0|1] ""  DMC
 SG_ SRF_Hall1SensorError : 46|1@0+ (1,0) [0|1] ""  DMC
 SG_ SRF_SunroofOverVolt : 45|1@0+ (1,0) [0|1] ""  DMC
 SG_ SRF_SunroofUnderVolt : 44|1@0+ (1,0) [0|1] ""  DMC
 SG_ SRF_LINCommunicationERROR : 43|1@0+ (1,0) [0|1] ""  DMC
 SG_ SRF_SwitchError : 42|1@0+ (1,0) [0|1] ""  DMC
 SG_ SRF_OverHeatProtect : 41|1@0+ (1,0) [0|1] ""  DMC
 SG_ SRF_MotorRelayError : 40|1@0+ (1,0) [0|1] ""  DMC
 SG_ AssociatedWithDriverModeFeedback : 32|1@0+ (1,0) [0|1] ""  DMC
 SG_ TheaterDimmingBrightnessFeedback : 35|3@0+ (1,0) [0|7] ""  DMC
 SG_ TheaterDimmingColorFeedback : 38|3@0+ (1,0) [0|7] ""  DMC
 SG_ SRF_Sunshade_OperateSts : 25|3@0+ (1,0) [0|7] ""  DMC
 SG_ RRWindowSts : 28|3@0+ (1,0) [0|7] ""  DMC
 SG_ RLWindowSts : 31|3@0+ (1,0) [0|7] ""  DMC
 SG_ WindowInhibitSts : 17|1@0+ (1,0) [0|1] ""  DMC
 SG_ FRWindow_Sts : 20|3@0+ (1,0) [0|7] ""  DMC
 SG_ FLWindow_Sts : 23|3@0+ (1,0) [0|7] ""  DMC
 SG_ Window_OperateSts : 11|2@0+ (1,0) [0|3] ""  DMC
 SG_ Reserved_SRF_Error : 15|4@0+ (1,0) [0|15] ""  DMC
 SG_ SRF_InitStatus : 7|1@0+ (1,0) [0|1] ""  DMC
 SG_ AssociatedWithMusicModeFeedback : 9|1@0+ (1,0) [0|1] ""  DMC
 SG_ TheaterDimmingStatusFeedback : 8|1@0+ (1,0) [0|1] ""  DMC
 SG_ SRF_PositionSts : 6|4@0+ (1,0) [0|15] ""  DMC
 SG_ SRF_OperateSts : 2|3@0+ (1,0) [0|7] ""  DMC
 SG_ TrailerConnectSts : 48|1@0+ (1,0) [0|1] ""  DMC

BO_ 1514 BCM_7: 8 Vector__XXX
 SG_ NavigationInformation : 60|1@0+ (1,0) [0|1] ""  DMC
 SG_ SecondIntervalMaintainMileage : 44|2@0+ (1,0) [0|3] ""  DMC
 SG_ OverSpeedWarningFunction : 21|2@0+ (1,0) [0|3] ""  DMC
 SG_ Language : 19|4@0+ (1,0) [0|15] ""  DMC
 SG_ LDW : 15|1@0+ (1,0) [0|1] ""  DMC
 SG_ EngineFuelType : 14|2@0+ (1,0) [0|3] ""  DMC
 SG_ Radar : 12|1@0+ (1,0) [0|1] ""  DMC
 SG_ FuelConsumptionCorrect : 11|2@0+ (1,0) [0|3] ""  DMC
 SG_ MaintainMileage : 9|1@0+ (1,0) [0|1] ""  DMC
 SG_ FirstMaintain : 8|1@0+ (1,0) [0|1] ""  DMC
 SG_ InitialFuelConsumption : 7|8@0+ (0.1,0) [0|25.5] ""  DMC

BO_ 1505 BCM_6: 8 Vector__XXX
 SG_ PEPSType : 61|2@0+ (1,0) [0|3] ""  DMC
 SG_ CGW : 38|1@0+ (1,0) [0|1] ""  DMC
 SG_ TCU4_7DCT_DHT : 31|1@0+ (1,0) [0|1] ""  DMC
 SG_ EIPM_ONCAN : 30|1@0+ (1,0) [0|1] ""  DMC
 SG_ RADAR : 24|1@0+ (1,0) [0|1] ""  DMC
 SG_ SAS : 17|1@0+ (1,0) [0|1] ""  DMC
 SG_ APM : 15|1@0+ (1,0) [0|1] ""  DMC
 SG_ IMMO : 7|2@0+ (1,0) [0|3] ""  DMC
 SG_ ICM : 2|1@0+ (1,0) [0|1] ""  DMC
 SG_ BCM : 1|1@0+ (1,0) [0|1] ""  DMC
 SG_ EMS : 0|1@0+ (1,0) [0|1] ""  DMC
 SG_ EmissionType : 52|1@0+ (1,0) [0|1] ""  DMC
 SG_ TCU3_CVT25_CVT18 : 39|1@0+ (1,0) [0|1] ""  DMC
 SG_ MFS_LIN : 36|1@0+ (1,0) [0|1] ""  DMC
 SG_ ESCL_CAN : 35|1@0+ (1,0) [0|1] ""  DMC
 SG_ PLG : 34|1@0+ (1,0) [0|1] ""  DMC
 SG_ FRM : 33|1@0+ (1,0) [0|1] ""  DMC
 SG_ FCM : 32|1@0+ (1,0) [0|1] ""  DMC
 SG_ BSD : 29|1@0+ (1,0) [0|1] ""  DMC
 SG_ EPB : 28|1@0+ (1,0) [0|1] ""  DMC
 SG_ AVM : 25|1@0+ (1,0) [0|1] ""  DMC
 SG_ BMS : 23|1@0+ (1,0) [0|1] ""  DMC
 SG_ TPMS : 16|1@0+ (1,0) [0|1] ""  DMC
 SG_ RRM : 13|1@0+ (1,0) [0|1] ""  DMC
 SG_ PEPS : 12|1@0+ (1,0) [0|1] ""  DMC
 SG_ EPS : 11|1@0+ (1,0) [0|1] ""  DMC
 SG_ CLM : 10|1@0+ (1,0) [0|1] ""  DMC
 SG_ TCU2_6DCT : 9|1@0+ (1,0) [0|1] ""  DMC
 SG_ TCU1_CVT19 : 8|1@0+ (1,0) [0|1] ""  DMC
 SG_ ESP : 5|1@0+ (1,0) [0|1] ""  DMC
 SG_ ABS : 4|1@0+ (1,0) [0|1] ""  DMC
 SG_ ABM : 3|1@0+ (1,0) [0|1] ""  DMC

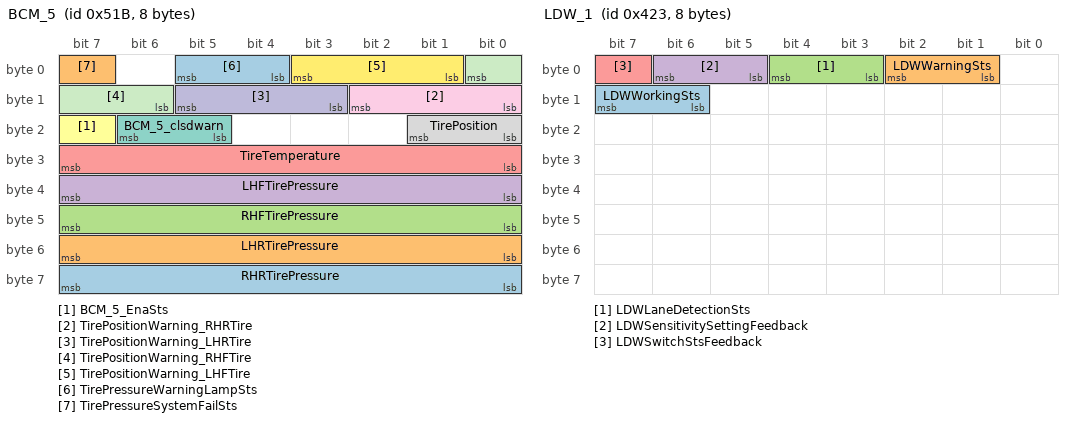
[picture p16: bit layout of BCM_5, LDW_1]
BO_ 1307 BCM_5: 8 Vector__XXX
 SG_ RHRTirePressure : 63|8@0+ (0.0177,0) [0|4.5] "bar"  DMC
 SG_ LHRTirePressure : 55|8@0+ (0.0177,0) [0|4.5] "bar"  DMC
 SG_ RHFTirePressure : 47|8@0+ (0.0177,0) [0|4.5] "bar"  DMC
 SG_ LHFTirePressure : 39|8@0+ (0.0177,0) [0|4.5] "bar"  DMC
 SG_ TireTemperature : 31|8@0+ (0.65,-40) [-40|125] "℃"  DMC
 SG_ BCM_5_EnaSts : 23|1@0+ (1,0) [0|1] ""  DMC
 SG_ BCM_5_clsdwarn : 22|2@0+ (1,0) [0|3] ""  DMC
 SG_ TirePosition : 17|2@0+ (1,0) [0|3] ""  DMC
 SG_ TirePositionWarning_RHRTire : 10|3@0+ (1,0) [0|7] ""  DMC
 SG_ TirePositionWarning_LHRTire : 13|3@0+ (1,0) [0|7] ""  DMC
 SG_ TirePositionWarning_RHFTire : 0|3@0+ (1,0) [0|7] ""  DMC
 SG_ TirePositionWarning_LHFTire : 3|3@0+ (1,0) [0|7] ""  DMC
 SG_ TirePressureWarningLampSts : 5|2@0+ (1,0) [0|3] ""  DMC
 SG_ TirePressureSystemFailSts : 7|1@0+ (1,0) [0|1] ""  DMC

BO_ 914 BCM_4: 8 Vector__XXX
 SG_ DRLModeSts : 58|1@0+ (1,0) [0|1] ""  DMC
 SG_ HeadlampDelayLightSts : 57|1@0+ (1,0) [0|1] ""  DMC
 SG_ AutolockSts : 56|1@0+ (1,0) [0|1] ""  DMC
 SG_ AutoFoldSts : 63|1@0+ (1,0) [0|1] ""  DMC
 SG_ HeadlampHeightFeedbackSts : 52|3@0+ (1,0) [0|7] ""  DMC
 SG_ RemoteLockFeedbackSts : 54|2@0+ (1,0) [0|3] ""  DMC
 SG_ BCM_4_DriverDoorLockSts : 31|1@0+ (1,0) [0|1] ""  DMC
 SG_ DrvrDoorUnlckOnlySts : 10|1@0+ (1,0) [0|1] ""  DMC
 SG_ FGHeat_Req_CmdFeedback : 7|1@0+ (1,0) [0|1] ""  DMC
 SG_ RearFoglightFaultSts : 61|1@0+ (1,0) [0|1] ""  DMC
 SG_ BCM_4_ChildSafetySts : 60|2@0+ (1,0) [0|3] ""  DMC
 SG_ WiperSensitivitySWSts : 44|3@0+ (1,0) [0|7] ""  DMC
 SG_ RainSensorFailSts : 41|1@0+ (1,0) [0|1] ""  DMC
 SG_ ReversinglampFaultSts : 40|1@0+ (1,0) [0|1] ""  DMC
 SG_ BCM_4_FrontFogLightSts : 37|1@0+ (1,0) [0|1] ""  DMC
 SG_ BrakelampFaultSts : 36|1@0+ (1,0) [0|1] ""  DMC
 SG_ BCM_4_ReverseGearSts : 35|1@0+ (1,0) [0|1] ""  DMC
 SG_ BCM_4_RearFogLightSts : 34|1@0+ (1,0) [0|1] ""  DMC
 SG_ BCM_4_TrunkSts : 30|1@0+ (1,0) [0|1] ""  DMC
 SG_ BCM_4_LHRdoorSts : 29|1@0+ (1,0) [0|1] ""  DMC
 SG_ BCM_4_RHRDoorSts : 28|1@0+ (1,0) [0|1] ""  DMC
 SG_ BCM_4_HoodSts : 26|1@0+ (1,0) [0|1] ""  DMC
 SG_ BCM_4_PsngrDoorSts : 25|1@0+ (1,0) [0|1] ""  DMC
 SG_ BCM_4_DriverDoorSts : 24|1@0+ (1,0) [0|1] ""  DMC
 SG_ FollowMeTimeSts : 23|4@0+ (1,0) [0|15] ""  DMC
 SG_ RVSMode : 19|1@0+ (1,0) [0|1] ""  DMC
 SG_ BCM_4_DirectionIndLeft : 17|1@0+ (1,0) [0|1] ""  DMC
 SG_ BCM_4_DirectionIndRight : 16|1@0+ (1,0) [0|1] ""  DMC
 SG_ BCM_4_DRLSts : 15|1@0+ (1,0) [0|1] ""  DMC
 SG_ BCM_4_HighBeamSts : 12|1@0+ (1,0) [0|1] ""  DMC
 SG_ BCM_4_ParkLightSts : 11|1@0+ (1,0) [0|1] ""  DMC
 SG_ BCM_4_LHTurnlightSts : 9|1@0+ (1,0) [0|1] ""  DMC
 SG_ BCM_4_RHTurnlightSts : 8|1@0+ (1,0) [0|1] ""  DMC
 SG_ BCM_4_KeySts : 6|2@0+ (1,0) [0|3] ""  DMC
 SG_ LightDetected : 4|1@0+ (1,0) [0|1] ""  DMC
 SG_ KeyRemindWarning : 3|1@0+ (1,0) [0|1] ""  DMC
 SG_ ParkLightOnWarning : 2|1@0+ (1,0) [0|1] ""  DMC
 SG_ BCM_4_ArmingSts : 1|2@0+ (1,0) [0|3] ""  DMC

BO_ 1059 LDW_1: 8 Vector__XXX
 SG_ LDWWorkingSts : 15|2@0+ (1,0) [0|3] ""  DMC
 SG_ LDWWarningSts : 2|2@0+ (1,0) [0|3] ""  DMC
 SG_ LDWLaneDetectionSts : 4|2@0+ (1,0) [0|3] ""  DMC
 SG_ LDWSensitivitySettingFeedback : 6|2@0+ (1,0) [0|3] ""  DMC
 SG_ LDWSwitchStsFeedback : 7|1@0+ (1,0) [0|1] ""  DMC

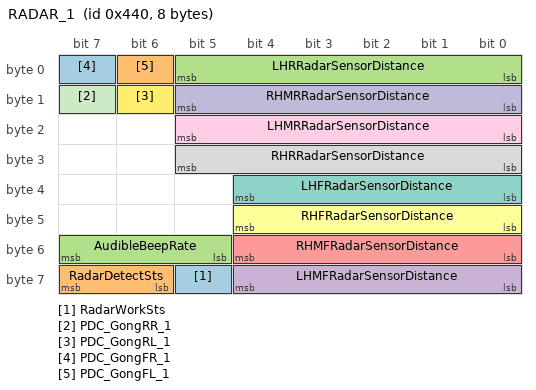
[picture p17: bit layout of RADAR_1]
BO_ 1088 RADAR_1: 8 Vector__XXX
 SG_ RadarWorkSts : 61|1@0+ (1,0) [0|1] ""  DMC
 SG_ RadarDetectSts : 63|2@0+ (1,0) [0|3] ""  DMC
 SG_ AudibleBeepRate : 55|3@0+ (1,0) [0|7] ""  DMC
 SG_ LHMFRadarSensorDistance : 60|5@0+ (5,25) [25|160] "cm"  DMC
 SG_ RHMFRadarSensorDistance : 52|5@0+ (5,25) [25|160] "cm"  DMC
 SG_ RHFRadarSensorDistance : 44|5@0+ (5,25) [25|160] "cm"  DMC
 SG_ LHFRadarSensorDistance : 36|5@0+ (5,25) [25|160] "cm"  DMC
 SG_ RHRRadarSensorDistance : 29|6@0+ (5,25) [25|180] "cm"  DMC
 SG_ LHMRRadarSensorDistance : 21|6@0+ (5,25) [25|180] "cm"  DMC
 SG_ RHMRRadarSensorDistance : 13|6@0+ (5,25) [25|180] "cm"  DMC
 SG_ PDC_GongRR_1 : 15|1@0+ (1,0) [0|1] ""  DMC
 SG_ PDC_GongRL_1 : 14|1@0+ (1,0) [0|1] ""  DMC
 SG_ PDC_GongFR_1 : 7|1@0+ (1,0) [0|1] ""  DMC
 SG_ PDC_GongFL_1 : 6|1@0+ (1,0) [0|1] ""  DMC
 SG_ LHRRadarSensorDistance : 5|6@0+ (5,25) [25|180] "cm"  DMC

CM_ BO_ 3221225472 "This is a message for not used signals, created by Vector CANdb++ DBC OLE DB Provider.";
CM_ BO_ 1928 "Source network message is \"NoMsgSendType, /\".
If no messages are received on source network, no messages are sent on the destination network.";
CM_ BO_ 2015 "Source network message is \"NoMsgSendType,/\".
If no messages are received on source network, no messages are sent on the destination network.";
CM_ BO_ 1443 "Source network message is \"NoMsgSendType, /\".
If no messages are received on source network, no messages are sent on the destination network.";
CM_ SG_ 1443 BitBlinking_TCU "This parameter defines the blinking frequency of a telltale";
CM_ SG_ 1443 BitRefreshRate_TCU "The value refresh rate defines the cycle time (1-14s) of the specific warning message (defined in value warning message ID)";
CM_ SG_ 1443 BitStatus_TCU "The status defines if a message is set or reset";
CM_ SG_ 1443 WarningMessageID_TCU "The value (0-254) defines the warning message ID (see warning message catalog) with this value the global ID for the warning which should be outputted is
defined";
CM_ SG_ 1443 ID2_TCU "Defines that the message is a warning message only if 32h is received a warning message should be generated";
CM_ BO_ 798 "Source network message is \"Cyclic, 50ms\".
If no messages are received on source network, no messages are sent on the destination network.";
CM_ SG_ 798 TMR_TMRSysFault "TMR System Fault";
CM_ BO_ 789 "Source network message is \"Cyclic, 50ms\".
If no messages are received on source network, no messages are sent on the destination network.";
CM_ SG_ 789 TMF_SpdAct "TMF motor actual speed";
CM_ SG_ 789 TMF_TMFSysFault "TMF System Fault";
CM_ BO_ 1187 "Source network message is \"Cyclic, 100ms\".
If no messages are received on source network, no messages are sent on the destination network.";
CM_ SG_ 1187 RHM_1_DRLFaildSts "RHM DRL Faild Status";
CM_ SG_ 1187 RHM_1_RHTurnLiFaildSts "RHM Right Hand Turn Light Faild Status";
CM_ SG_ 1187 RHM_1_ParkLiFaildSts "RHM Park Light Faild Status";
CM_ SG_ 1187 RHM_1_LoBeamFaildSts "RHM low Beam Faild Status";
CM_ SG_ 1187 RHM_1_HiBeamFaildSts "RHM High Beam Faild Status";
CM_ BO_ 1141 "Source network message is \"Cyclic, 100ms\".
If no messages are received on source network, no messages are sent on the destination network.";
CM_ SG_ 1141 FrontPDCObjectDistance "The nearest object distance of front park assistance. 0xFF:no obstacle detected/invalid";
CM_ SG_ 1141 RearPDCObjectDistance "The nearest object distance of rear park assistance. 0xFF:no obstacle detected/invalid";
CM_ SG_ 1141 LHSFRadarSensorDistance "??????????
??????Sensor err!mao!????0x7F
???????????????!mao!????0x7E

???????!mao!????=(D)*5+30
???????!mao!????0x7E
0x5F~0x7D!mao!??Ч????";
CM_ SG_ 1141 RHSFRadarSensorDistance "??????????
??????Sensor err!mao!????0x7F
???????????????!mao!????0x7E

???????!mao!????=(D)*5+30
???????!mao!????0x7E
0x5F~0x7D!mao!??Ч????";
CM_ SG_ 1141 LHSRRadarSensorDistance "?????????
??????Sensor err!mao!????0x7F
???????????????!mao!????0x7E

???????!mao!????=(D)*5+30
???????!mao!????0x7E
0x5F~0x7D!mao!??Ч????";
CM_ SG_ 1141 RHSRRadarSensorDistance "?????????
??????Sensor err!mao!????0x7F
???????????????!mao!????0x7E

???????!mao!????=(D)*5+30
???????!mao!????0x7E
0x5F~0x7D!mao!??Ч????";
CM_ BO_ 864 "Source network message is \"Cyclic, 50ms\".
If no messages are received on source network, no messages are sent on the destination network.";
CM_ BO_ 945 "Source network message is \"Cyclic, 50ms\".
If no messages are received on source network, no messages are sent on the destination network.";
CM_ SG_ 945 MFS_ICMFctChg "ICM Function Change";
CM_ SG_ 945 MFS_Customize "???：??e??????????д????e????，MFS??????0x0";
CM_ SG_ 945 TJA_ICA_ON_OFF "TJA/ICA ON/OFF button";
CM_ SG_ 945 MFS_VoiceRecognition "???：??e??????????д????e????，MFS??????0x0";
CM_ SG_ 945 MFS_SeekDown "???：??e??????????д????e????，MFS??????0x0";
CM_ SG_ 945 MFS_SeekUp "???：??e??????????д????e????，MFS??????0x0";
CM_ SG_ 945 MFS_VolumeDown "???：??e??????????д????e????，MFS??????0x0";
CM_ SG_ 945 MFS_VolumeUp "???：??e??????????д????e????，MFS??????0x0";
CM_ BO_ 777 "Source network message is \"Cyclic, 50ms\".
If no messages are received on source network, no messages are sent on the destination network.";
CM_ SG_ 777 ISGF_ISGFSysFault "ISG System Fault";
CM_ SG_ 933 AWBRequest "AWB Request";
CM_ SG_ 933 AEBReq "AEB Request";
CM_ SG_ 933 AEBDecCtrlRequest "AEB deceleration Control Request";
CM_ BO_ 1018 "Source network message is \"Cyclic, 50ms\".
If no messages are received on source network, no messages are sent on the destination network.";
CM_ SG_ 1018 FCM_FRM_9_RiObjHozDstY "Right Object horizontal distance Y";
CM_ SG_ 1018 FCM_FRM_9_RiObjLgtDstX "Right Object longitudinal distance X";
CM_ SG_ 1018 FCM_FRM_9_RiObjTyp "Right Object Type";
CM_ SG_ 1018 FCM_FRM_9_RiObjID "Right Object ID";
CM_ SG_ 1018 FCM_FRM_9_LeObjHozDstY "Left  Object horizontal distance Y";
CM_ SG_ 1018 FCM_FRM_9_LeObjLgtDstX "Left Object longitudinal distance X";
CM_ SG_ 1018 FCM_FRM_9_LeObjTyp "Left  Object Type";
CM_ SG_ 1018 FCM_FRM_9_LeObjID "Left  Object ID";
CM_ BO_ 1005 "Source network message is \"Cyclic, 50ms\".
If no messages are received on source network, no messages are sent on the destination network.";
CM_ SG_ 1005 FCM_FRM_8_FrntFarObjHozDstY "Front Far Object horizontal distance Y";
CM_ SG_ 1005 FCM_FRM_8_FrntFarObjLgtDstX "Front Far Object longitudinal distance X";
CM_ SG_ 1005 FCM_FRM_8_FrntFarObjTyp "Front Far Object Type";
CM_ SG_ 1005 FCM_FRM_8_FrntFarObjID "Front Far Object ID";
CM_ SG_ 1005 FCM_FRM_8_ACCObjHozDstY "ACC Object horizontal distance Y";
CM_ SG_ 1005 FCM_FRM_8_ACCObjLgtDstX "ACC Object longitudinal distance X";
CM_ SG_ 1005 FCM_FRM_8_ACCObjTyp "ACC Object Type";
CM_ SG_ 1005 FCM_FRM_8_ACCObjID "ACC Object ID";
CM_ BO_ 990 "Source network message is \"Cyclic, 50ms\".
If no messages are received on source network, no messages are sent on the destination network.";
CM_ SG_ 990 FCM_7_NeborRiLineCrvt "Curvature of the Neighbor Right  Line";
CM_ SG_ 990 FCM_7_NeborRiLineHozlDst "Horizontal distance of Neighbor Right Line";
CM_ SG_ 990 FCM_7_NeborRiLineTyp "The type of Neighbor Right Line";
CM_ SG_ 990 FCM_7_NeborRiLineColor "Neighbor Right Line Color";
CM_ SG_ 990 FCM_7_NeborRiLineID "Neighbor Right Line ID";
CM_ SG_ 990 FCM_7_NeborLeLineCrvt "Curvature of the Neighbor Left Line";
CM_ SG_ 990 FCM_7_NeborLeLineHozlDst "Horizontal distance of Neighbor Left Line";
CM_ SG_ 990 FCM_7_NeborLeLineTyp "The type of Neighbor Left Line";
CM_ SG_ 990 FCM_7_NeborLeLineColor "Neighbor Left Line Color";
CM_ SG_ 990 FCM_7_NeborLeLineID "Neighbor Left Line ID";
CM_ BO_ 988 "Source network message is \"Cyclic, 50ms\".
If no messages are received on source network, no messages are sent on the destination network.";
CM_ SG_ 988 FCM_6_EgoRiLineCrvt "Curvature of the Ego Car Right lane line";
CM_ SG_ 988 FCM_6_EgoRiLineHozlDst "Horizontal distance between the Ego car and the Right lane line";
CM_ SG_ 988 FCM_6_EgoRiLineTyp "The type of Ego car Right lane line";
CM_ SG_ 988 FCM_6_EgoRiLineColor "Ego Car Right lane line color";
CM_ SG_ 988 FCM_6_EgoRiLineID "Ego Car Right Line ID";
CM_ SG_ 988 FCM_6_EgoLeLineCrvt "Curvature of the Ego Car left lane line";
CM_ SG_ 988 FCM_6_EgoLeLineHozlDst "Horizontal distance between the Ego car and the left lane line";
CM_ SG_ 988 FCM_6_EgoLeLineTyp "The type of Ego car left lane line";
CM_ SG_ 988 FCM_6_EgoLeLineColor "Ego Car left lane line color";
CM_ SG_ 988 FCM_6_EgoLeLineID "Ego Car Left Line ID";
CM_ BO_ 1241 "Source network message is \"Cyclic, 100ms\".
If no messages are received on source network, no messages are sent on the destination network.";
CM_ SG_ 1241 FuelTankLidSystemFailureSts "????С???????????";
CM_ SG_ 1241 FuelTankPressureConditionReached "????????????";
CM_ BO_ 1232 "Source network message is \"Cyclic, 100ms\".
If no messages are received on source network, no messages are sent on the destination network.";
CM_ SG_ 1232 Energy_Flow_Sts "00:????????????;
01:????????????磻
10:??????????????磻
11!mao!?????????";
CM_ SG_ 1232 Battery_Sts "00:????????????????
01:???????
10:?????";
CM_ SG_ 1232 Battery_Temp_Sts "00:48V???????????
01:48V???????????????????????65!du!)
10:???μ??μ?48V???????δ???";
CM_ SG_ 1146 AllWarningInfo "EGS??????????
T1C???!dou!EGS??????0x0!dun!0x1!dun!0x4!dou!??????";
CM_ BO_ 1054 "Source network message is \"Cyclic, 100ms\".
If no messages are received on source network, no messages are sent on the destination network.";
CM_ SG_ 1054 DCDC_DCDCSysFault "DCDC System Fault";
CM_ SG_ 1048 DCDC_EnableSts "DCDC enable states feedback";
CM_ SG_ 1048 DCDC_1_ActDisOutPower "????繦??                                                                                                     Real-time discharge power";
CM_ SG_ 1258 BMSH_BattFaultLampSts "Battery system Fault Lamp Status";
CM_ SG_ 1258 BMSH_PackThermalRunawayLight "Pack Thermal Runaway Light";
CM_ BO_ 1450 "Source network message is \"Cyclic, 1000ms\".
If no messages are received on source network, no messages are sent on the destination network.";
CM_ SG_ 1450 BMSH_BatteryTempLightSts "Battery Temperature Light Status";
CM_ SG_ 1450 BMSH_LowSOC "SOC low warning";
CM_ BO_ 1158 "Source network message is \"Cyclic, 100ms\".
If no messages are received on source network, no messages are sent on the destination network.";
CM_ SG_ 1158 AWDoutserviceDispRq "0x0: ???????????
0x1: ?????????????!dou!???????
0x2: ?????????ù???!dou!?????????
0x3: ???λ";
CM_ BO_ 1095 "Source network message is \"Cyclic, 100ms\".
If no messages are received on source network, no messages are sent on the destination network.";
CM_ SG_ 1095 AFS_FaultSts "AFS ??????";
CM_ BO_ 745 "Source network message is \"Cyclic, 10ms\".
If no messages are received on source network, no messages are sent on the destination network.";
CM_ SG_ 745 AEBdecActive "AEB  braking function";
CM_ SG_ 1556 WakeupSource_ICM "Wakeup Source
Note: Details Please refer to specification??BD CAN ICM Network Management Specification ??section10.2 and ??BD CAN DMC Network Management Specification ??section10.2";
CM_ SG_ 1556 ECUSPEC_AWAKE_ICM "ECU keeps the network awake for ECU-define reasons for which communication is needed";
CM_ SG_ 1556 DIAGNOSTIC_AWAKE_ICM "ECU needs communication for diagnostic purpose and keeps network awake.";
CM_ SG_ 1556 IGNITION_AWAKE_ICM "ECU can?t release communication because ignition (KL15) is turn on, or KLR is turned on";
CM_ SG_ 1556 NETWORK_AWAKE_ICM "ECU keeps the network awake due to the CAN message received from the network";
CM_ SG_ 1556 ECUSPEC_WAKEUP_ICM "ECU was in ??power off??, ??Bus Sleep??, ??Pre-pare Bus Sleep?? or ??Ready Sleep?? mode or ??awake?? and re-started by ECU specific reason (e.g. pressed Button, timer, etc.)";
CM_ SG_ 1556 NETWORK_WAKEUP_ICM "ECU was in ??Power off??, ??Bus Sleep??, ??Pre-pare Bus Sleep?? or ??Ready Sleep?? Mode and then re-started by a network communication.";
CM_ SG_ 1556 RESET_WAKEUP_ICM "If ECU was already awake, in ??Prepare Bus Sleep?? or ??Ready Sleep?? mode and re-started by an internal or an external reset.";
CM_ SG_ 1556 IGNITION_WAKEUP_ICM "ECU was ??power off?? or ??Bus sleep?? mode and started by ignition switch";
CM_ SG_ 1556 RMR_ICM_CBV "If set to 1 to force the network management of all other nodes on the bus into the re-peat message state.";
CM_ SG_ 1556 srcNodeID_ICM_SNII "The srcNodeID of ICM is 0x20";
CM_ SG_ 1090 SCU_1_LuggageModFlagSts "????????λ";
CM_ SG_ 1090 SCU_1_JourneyModFlagSts "?????????λ";
CM_ SG_ 1090 SCU_1_SmartSpaceWarn "???????ж????????";
CM_ SG_ 1090 SCU_1_ModCheckFb "???????????鷴?????";
CM_ SG_ 1090 SCU_1_BedModFlagSts "???????λ";
CM_ SG_ 1090 SCU_1_FRSeatVentilationFbSts "0x3: Seat Ventilation Level3 is only for EEA4.0 project
????????????";
CM_ SG_ 1090 SCU_1_FLSeatVentilationFbSts "0x3: Seat Ventilation Level3 is only for EEA4.0 project
????????????";
CM_ SG_ 1090 Seat_ExtMirror_PositionInfo "???η?????DVD??????λ????????";
CM_ SG_ 1090 SCURelateKeyOrFaceIDFeedbackSts "???μ??书???????????ID?????????????
??????????????!mao!?????????μ??书????????????????????
????????????????!mao!?????????μ??书???????????ID????????";
CM_ SG_ 1090 Seat_ExtMirror_MemorySts "????/????????????
0x0!mao!??д???????/??????λ?ü??书???!dou!??????0x0
0x1!mao!??????
0x2!mao!???????
???????!dou!???????????0x1!mao!success!dou!???0x0!mao!Not active";
CM_ SG_ 1090 SCU_1_FRSeatHeatFbSts "0x3: Seat heating Level3 is only for EEA4.0 project
??????μ?????";
CM_ SG_ 1090 SCU_1_FLSeatHeatFbSts "0x3: Seat heating Level3 is only for EEA4.0 project
??????μ?????";
CM_ SG_ 1090 ReverseExtMirrorFeedbackSts "???????????·???????";
CM_ SG_ 1090 EasyEntryFeedbackSts "EasyEntry??????";
CM_ SG_ 1090 Seat_ExtMirror_MemoryReq "???μ???/??????????????
Note:???????????????????λ???????!dou!???????????3s????в??????????,???????????????????????!dou!????????????0x1!mao!Reuqest!dou!???0x0!mao!Not Request";
CM_ SG_ 1090 Seat_ExtMirror_MemoryEnable "???μ???/????????????????????
Note!mao!??????????????!dou!????????0x1??";
CM_ SG_ 1090 MemoryKeySts "???μ?????尴??，M?????????
0x0!mao!M??δ????
0x1!mao!M??????
M???????!dou!???????????0x1!mao!Active!dou!???0x0!mao!Not active";
CM_ SG_ 1078 PLG_PositionSts "β??λ?y??";
CM_ SG_ 1078 PLG_OperateSts "β????????";
CM_ SG_ 1078 PLG_Set_MaxPosition "β????????????λ??";
CM_ SG_ 1152 RemoteStartSts "????????";
CM_ SG_ 1152 SmartSystemWarning1_1 "BCM itself also should receive this message besides gateway function for dealing";
CM_ SG_ 1152 SmartSystemWarning1_3 "BCM itself also should receive this message besides gateway function for dealing.";
CM_ SG_ 1152 SmartSystemWarning3_2 "Detect whether shift is in P/N when starting";
CM_ SG_ 1152 SmartSystemWarning4_2 "Detect whether pressing brake or clutch to start engine";
CM_ SG_ 1219 PAS_1_DriverDoorSIllSts "Robe the clip";
CM_ SG_ 1025 ESCLNotLocked "The status defines if a message is set or reset";
CM_ SG_ 1025 ESCLUnlockJamming "The value (0-254) defines the warning message ID (see warning message cataloge) with this value the global ID for the warning which should be outputted is
defined";
CM_ SG_ 1025 ESCLCriticalFailure "Defines that the message is a warning message only if 32h is received a warning message should be generated
??????0x32?????????Ч?????????";
CM_ SG_ 1322 Sigcycfucns "signal cycle fuel consumption ???????";
CM_ SG_ 1322 ResidualOdometer_PHEV "???????(PHEV)";
CM_ SG_ 1247 ICM_9_EVTotOdo "EV total Odometer
EV?????";
CM_ SG_ 1247 ICM_9_HEVTotOdo "HEV total Odometer
HEV?????";
CM_ BO_ 533 "??????Σ???3?ε????? ???????Not Active.";
CM_ SG_ 533 SetICMAlarm "ICM Alarm??ADAS????????";
CM_ SG_ 1329 SIA_IntervalDistance "current interval distance
?????????????";
CM_ SG_ 1329 SIA_LastDay "Represents the last SIA day. Invalid =0
??α??????????";
CM_ SG_ 1329 SIA_LastYear "Represents the  last SIA year. Invalid = 2101 to 2127
??α??????????";
CM_ SG_ 1329 SIA_LastMonth "Represents the  last SIA month. 0, 13 to 15 = Invalid
??α??????????";
CM_ SG_ 1329 SIA_IntervalTime "current interval time
?????????????";
CM_ SG_ 1329 SIA_LastODO "last SIA ODO value
??α???????????";
CM_ SG_ 1066 Set_HundECAverHisClearSts "??????????????：
??????????!dou!????????????????????0x1!mao!Clear???!dou!??????????????????0x0 Not Clear;";
CM_ SG_ 1066 ICM_6_SumTrip "???????С????? Km";
CM_ SG_ 1066 TotalOdometer_km_OBD "GB18285-2018????OBD????????????????????????";
CM_ SG_ 1066 TotODOMtrBkpEna "??????????";
CM_ SG_ 1066 DrivermodeReq "?????????";
CM_ SG_ 647 ICM_5_Checksum "((Byte0+Byte1+Byte2+Byte3+Byte4+Byte5+Byte6) AND 0xFF) XOR 0xFF
Note: Details Please refer to specification??Standard Specification for CAN Data Link Layer_v1.1??section 2.3.3";
CM_ SG_ 647 ICM_5_MessageCounter "Rolling message counter(the maximum value of Alive counter is 15)
Note: Details Please refer to specification??Standard Specification for CAN Data Link Layer_v1.1??section 2.3.1";
CM_ SG_ 647 ICM_DVDAudibleAlarmStyle "???????????：
0x0:?????
0x1:???β???
0x2!mao!???????
12.3????????????!dou!??????????DVD???????";
CM_ SG_ 647 ICM_DVDAudibleAlarm "12.3????????????，??????????DVD???????
0x0:?????";
CM_ SG_ 647 BrakeFluidWarning "??????????????";
CM_ SG_ 647 ICM_5_AlrmVolCtrl "Alarm volume control????????????
??????????????????????!dou!???????Up????Down?!dou!???????????????????????!dou!??????????????????0x0 Not active??
0x0 ??????
0x1 ???????????
0x2 ???????????";
CM_ SG_ 647 ICM_5_BackLiBriAdjmt "Backlight brightness adjustment ???????????
?????????????????????!dou!???????Up????Down?!dou!???????????????????????!dou!??????????????????0x0 Not active??
0x0 ??????
0x1 ???????????
0x2 ???????????";
CM_ SG_ 647 AverageFuelConsumption50 "??????";
CM_ SG_ 647 ICM_5_FuelLevel "???：???????EMS??";
CM_ SG_ 647 FuelValidData "???：???????EMS??";
CM_ SG_ 647 FuelOutOfRange "???：???????EMS??";
CM_ SG_ 647 FuelShortPower "???：???????EMS??";
CM_ SG_ 647 FuelShortGround "???：???????EMS??";
CM_ SG_ 647 HandBrakeSystemSts "???????
????????????
???????н???
?????????????????
?????????н??????
δ???!mao!??????????δ???
ErrorApplied!mao!
??EPBError????????????н???,????????EPB(apply)???????101?????????????
??EPBError????????н???,??101?????????????
??е??????000??001????????EPB?????????С?";
CM_ SG_ 1107 TimeFormat "?????";
CM_ SG_ 1107 FatigureDrivingWarning "?????????";
CM_ SG_ 1107 CurrentTimeYear "??";
CM_ SG_ 1107 CurrentTimeMonth "??";
CM_ SG_ 1107 CurrentTimeDay "??";
CM_ SG_ 1107 ResidualOdometer "???????";
CM_ SG_ 1107 CurrentTimeSecond "ICM??????????????
DVD??
????????!dou!??0 (Not active)??
????????0 (Startup)?????15????????!dou!???????????(????????????????????)??";
CM_ SG_ 1107 ICM_BrightnessLevel "ICMBrightnessLevel????ICMBackLightLevel??????????????????????，??????";
CM_ SG_ 1107 MaintainWarning "??????????";
CM_ SG_ 1107 LowFuleWarning "????????????????????DVD?????，DVD??????????????λ????????，????????????????е?????
??????λ???????Ч!dou!??????0??";
CM_ SG_ 1107 FatigureDrivingTime "????????，???????????????á?
???????????????!dou!????1 hours??????????Ч???????!dou!????????????????Ч?
??δ???????!dou!?????????Ч???
????????!dou!??1 hours??
???RRM???ù????!dou!???????????????????????????ICM????????";
CM_ SG_ 1107 CurrentTimeMinute "ICM??????????????
DVD??????????y??
????????!dou!??0 (Not active)??????????0 (Startup)?????15????????!dou!???????????(????????????????????)??";
CM_ SG_ 1107 CurrentTimeHour "ICM???????????????
DVD??????????y??
????????!dou!??0 (Not active)??????????0 (Startup)?????15????????!dou!???????????(????????????????????)??";
CM_ SG_ 1106 FrontSeatBeltAlarmLight "Front Seat Belt Alarm Light
???????????????
0x0!mao!??????????????????
0x1!mao!?????????????????";
CM_ SG_ 1106 QDashACCFail "Error in the ACC message detected by the HMI, like timeout or alivecounter error.
The error should distinguish reversible and irreversible errors.
???????????????????????????????????????????????????ж???????????????????????????????????????????????????????????!dou!????????????????;";
CM_ SG_ 1106 DISFail "Error in the display or display control unit.
TFT?????и????PIN??!dou!?????????????PIN???????????????????????????!dou!??????????????????????????????PIN???????ж????;";
CM_ SG_ 1106 ICM_2_LoWshLqdWarn "Washing liquid level alarm signal，If the washing liquid level sensor fails, the signal is 0
????λ???????!dou!??????λ???????Ч!dou!??????0";
CM_ SG_ 1106 TemperatureUnit_ICM "????λ?л?
???????????Startup????????!deg!";
CM_ SG_ 1106 AirBagLampFailSts "When the value set
to??00b??,it means that the
ICM airbaglamp has no fail
whether ICM lamp is ON
or OFF.
When the value is 01, means the LED lamp is fail because it??s always off.
When the value is 10, means the LED lamp is fail because it??s always on.";
CM_ SG_ 1106 AverageFuelConsumption "??????";
CM_ SG_ 1072 EngineCoolantTempertureHighWarn "Trans+AE164:AK164mit this Signal for PPMI";
CM_ SG_ 1072 DrvrSeatBltSwtForPPMI "Transmit this DriverSeatBeltSwitch for PPMI";
CM_ SG_ 1072 FuelLevel "Unfilter signal";
CM_ SG_ 1072 ICM_1MessageCounter "Rolling message counter(the maximum value of Alive counter is 15)
Note: Details Please refer to specification??Standard Specification for CAN Data Link Layer_v1.1??section 2.3.1";
CM_ SG_ 1072 FuelLevelFailSts "????·??·，??·，????20S??????????Fail Present";
CM_ SG_ 1072 ECOModeSWSts "?????1????\"ECO\"，0????\"Sport\"
MT????ECO????";
CM_ SG_ 1072 BatteryVoltage "????????????????";
CM_ SG_ 1072 DisplayVehicleSpeed "???????????，???????????";
CM_ SG_ 1072 ICM_1_HandBrakeSystemSts "???????
????????????
???????н???
?????????????????
?????????н??????
δ???!mao!??????????δ???
ErrorApplied!mao!
??EPBError????????????н???,????????EPB(apply)???????101?????????????
??EPBError????????н???,??101?????????????
??е??????000??001????????EPB?????????С?";
CM_ SG_ 1275 DCM_1_PwrDoorErr "Power Door Error";
CM_ SG_ 1275 DCM_1_RHRStallSts "?????????????";
CM_ SG_ 1275 DCM_1_LHRStallSts "?????????????";
CM_ SG_ 1275 DCM_1_PassStallSts "??????????????";
CM_ SG_ 1275 DCM_1_DrvrStallSts "???????????????";
CM_ SG_ 1306 SelfTestResult "????????????????DVD????????，DVD?????????????????SelfTestActive?????";
CM_ SG_ 1306 SetTemperature_L_C "?????????，????????????????趨?????????????趨???????????，??????趨???????，??????趨????????
DVDδ????趨????!dou!???????趨????startup ?????1F?!dou!DVD???????????????????????";
CM_ SG_ 1306 BlowDelayOffSts "DelayOff：??????????
Not DelayOff!mao!??????????????";
CM_ SG_ 1306 BlowAdvanceOnSts "AdvanceOn：???????????
Not AdvanceOn!mao!???????????????";
CM_ SG_ 1306 DisplayActive "???????????
CLM?????????????DVD????????!dou!????active-1!dou!DVD??????????????????10????м????????????!dou!????? not active-0!dou!DVD?????????????";
CM_ SG_ 1306 SelfTestActive "???????????????????5S????，?????????????Ч???， ????????????????DVD????????5s??，??????????????Ч";
CM_ SG_ 1306 PM2_5Sts "PM2.5??????";
CM_ SG_ 1306 WorkingSts "Not active-?????
Active--?????";
CM_ SG_ 1306 FrontDeforest_MaxDisplaySts "?????????????";
CM_ SG_ 1306 ACRequestDisplaySts "AC??????
?????????????,?????EMS??AC??????????????";
CM_ SG_ 1306 AC_MaxSts "MAX AC??????";
CM_ SG_ 1306 TemperatureUnit "???????????Startup??
??????!deg!";
CM_ SG_ 1226 CIR_1_ClsdWarn "CIR_1_closed warning
CIR?????????";
CM_ SG_ 1226 CIR_1_FltySts "CIR_1_Faulty Status
CIR?????
rader reports fault and CDP&SOD could not work";
CM_ SG_ 1226 CIR_1_EnaSts "CIR_1_Enable Status
CIR???????";
CM_ SG_ 1481 BDM_28_EVTotOdoBkp "EV???????";
CM_ SG_ 1224 BDM_21_CRC "CRC (SAE J1850 CRC-8)
Note: Details Please refer to specification??EE Standard Specification for CAN  Network Implementation??section 2.3.2";
CM_ SG_ 1224 BDM_21_MessageCounter "Rolling message counter(the maximum value of Alive counter is 15)
Note: Details Please refer to specification??EE Standard Specification for CAN  Network Implementation??section 2.3.1";
CM_ SG_ 1224 BDM_21_TotLampFailSts "?????????";
CM_ SG_ 1224 BCM_RRPLMfailsts "RRPLM Faild Status";
CM_ SG_ 1224 BCM_RRFLMfailsts "RRFLM Faild Status";
CM_ SG_ 1224 BCM_RLPLMfailsts "RLPLM Faild Status";
CM_ SG_ 1224 BCM_RLFLMfailsts "RLFLM Faild Status";
CM_ SG_ 1224 BCM_RHMfailsts "RHM Faild Status";
CM_ SG_ 1224 BCM_LHMfailsts "LHM Faild Status";
CM_ SG_ 1224 ReFogLiFaildSts "Rear frog  light  Faild Status";
CM_ SG_ 1224 ReversinglampFaultSts "Reversing lamp Faild Status";
CM_ SG_ 1224 BrakelampFaultSts "Brake lamp Faild Status";
CM_ SG_ 1224 FrntFogFaildSts "Front frog  light  Faild Status";
CM_ SG_ 1224 DRLFaildSts "Daytime running light Faild Status";
CM_ SG_ 1224 BDM_21_RHTurnlightSts "Right Hand Turn light Status";
CM_ SG_ 1224 BDM_21_LHTurnlightSts "Left Hand Turn light Status";
CM_ SG_ 1224 ParkLiFaildSts "Park Light Faild Status";
CM_ SG_ 1224 LoBeamFaildSts "Low Beam Faild Status";
CM_ SG_ 1224 HiBeamFaildSts "High Beam Faild Status";
CM_ SG_ 746 TotODOMtrBkp "BDM????????????????";
CM_ SG_ 746 BDM_OTAPwrOnReqFb "OTA Power On Request FeedBack";
CM_ SG_ 746 BDM_OTAPwrDwnReqFb "OTA Power Down Request FeedBack";
CM_ SG_ 746 BDM_OTAModStsFb "Mode Status FeedBack";
CM_ SG_ 746 LbaLimits "low battery limits
????????????";
CM_ SG_ 746 SlaveVehMod "?????????????";
CM_ SG_ 746 VehPwrMod "?????????";
CM_ BO_ 1008 "Source network message is \"NoMsgSendType, /\".???????????????
If no messages are received on source network, no messages are sent on the destination network.";
CM_ SG_ 1008 BCM_17_CRC "CRC (SAE J1850 CRC-8)
Note: Details Please refer to specification??EE Standard Specification for CAN  Network Implementation??section 2.3.2";
CM_ SG_ 1008 BCM_17_MessageCounter "Rolling message counter(the maximum value of Alive counter is 15)
Note: Details Please refer to specification??EE Standard Specification for CAN  Network Implementation??section 2.3.1";
CM_ SG_ 1008 BCM_17_Resd "????????????淶";
CM_ SG_ 901 CTP_SetACRequest "CTP???????????????????AC????";
CM_ SG_ 901 BCM_15_ChrgFillerAjar "???????????????";
CM_ SG_ 901 CTP_VolStepValForDVD "Volume Step Value For DVD of Roller";
CM_ SG_ 901 CTP_VolPlusMinusForDVDSts "Volume Plus Minus For DVD Status of Roller";
CM_ SG_ 901 CTP_HomeKeyForIHUSts "DVD???????";
CM_ SG_ 901 CTP_PowerKeyForIHUSts "DVD???????
??e??????????д????e????!dou!??????0x0";
CM_ SG_ 901 CTP_TrackMod "track mode
???????!dou!??3?? Active!dou!????? Not Active";
CM_ SG_ 901 CTP_NavKeyForIHUSts "CTP_NavigationKeyForIHUSts
???????!dou!??3?? Active!dou!????? Not Active
????????!dou!???????????";
CM_ SG_ 1315 TirePositionWarning_RHRTire "???λ?????????，????????、???、???、?????";
CM_ SG_ 1315 TirePositionWarning_LHRTire "???λ?????????，????????、???、???、?????";
CM_ SG_ 1315 TirePositionWarning_RHFTire "?????λ?????????，????????、???、???、?????";
CM_ SG_ 1315 TirePositionWarning_LHFTire "?????λ?????????，????????、???、???、?????";
CM_ SG_ 1315 TirePressureWarningLampSts "??????????，?????、?????????????、?????????????????";
CM_ SG_ 1315 BCM_16_CRC "CRC (SAE J1850 CRC-8)
Note: Details Please refer to specification??EE Standard Specification for CAN  Network Implementation??section 2.3.2";
CM_ SG_ 1315 BCM_16_MessageCounter "Rolling message counter(the maximum value of Alive counter is 15)
Note: Details Please refer to specification??EE Standard Specification for CAN  Network Implementation??section 2.3.1";
CM_ SG_ 1063 TheaterDimmingColorFeedback_64 "64???Χ???????????";
CM_ SG_ 1063 HUDBriUnit "HUD brightness unit.
In case brightness <= 120lux, the HUDBrightnessUnit=0x0 ; in case the brightness > 120lux andbrightness<= 1200lux, the HUDBrightnessUnit=0x1; 
in case thbrightness > 1200lux and brightness<= 12000lux, theHUDBrightnessUnit=0x2;
otherwise the HUDBrightnessUnit=0x3.";
CM_ SG_ 1063 HUDBriRawVal "HUDBrightnessRawValue
HUD brightness automatic adjustment raw value for HUD.
0x7F:Invalid. HUDbrightness=HUDBrightnessRawValue*HUDBrightnessUnit";
CM_ SG_ 1063 Wpr_FailSts "??ε??????????LIN????，BDM?????????????";
CM_ SG_ 1063 Lbatip "low battery tip";
CM_ SG_ 1520 BCM_10_MessageCounter_10 "Rolling message counter(the maximum value of Alive counter is 15)
Note: Details Please refer to specification??Standard Specification for CAN Data Link Layer_v1.1??section 2.3.1";
CM_ SG_ 1520 BCM_10_MessageCounter_9 "Rolling message counter(the maximum value of Alive counter is 15)
Note: Details Please refer to specification??Standard Specification for CAN Data Link Layer_v1.1??section 2.3.1";
CM_ SG_ 1520 BCM_10_MessageCounter_8 "Rolling message counter(the maximum value of Alive counter is 15)
Note: Details Please refer to specification??Standard Specification for CAN Data Link Layer_v1.1??section 2.3.1";
CM_ SG_ 1520 BCM_10_MessageCounter_7 "Rolling message counter(the maximum value of Alive counter is 15)
Note: Details Please refer to specification??Standard Specification for CAN Data Link Layer_v1.1??section 2.3.1";
CM_ SG_ 1520 BCM_10_MessageCounter_6 "Rolling message counter(the maximum value of Alive counter is 15)
Note: Details Please refer to specification??Standard Specification for CAN Data Link Layer_v1.1??section 2.3.1";
CM_ SG_ 1520 BCM_10_MessageCounter_5 "Rolling message counter(the maximum value of Alive counter is 15)
Note: Details Please refer to specification??Standard Specification for CAN Data Link Layer_v1.1??section 2.3.1";
CM_ SG_ 1520 BCM_10_MessageCounter_4 "Rolling message counter(the maximum value of Alive counter is 15)
Note: Details Please refer to specification??Standard Specification for CAN Data Link Layer_v1.1??section 2.3.1";
CM_ SG_ 1520 BCM_10_MessageCounter_3 "Rolling message counter(the maximum value of Alive counter is 15)
Note: Details Please refer to specification??Standard Specification for CAN Data Link Layer_v1.1??section 2.3.1";
CM_ SG_ 1520 BCM_10_MessageCounter_2 "Rolling message counter(the maximum value of Alive counter is 15)
Note: Details Please refer to specification??Standard Specification for CAN Data Link Layer_v1.1??section 2.3.1";
CM_ SG_ 1520 BCM_10_MessageCounter_1 "Rolling message counter(the maximum value of Alive counter is 15)
Note: Details Please refer to specification??Standard Specification for CAN Data Link Layer_v1.1??section 2.3.1";
CM_ SG_ 1520 BCM_10_Signal1 "1、Message ID????.??BCM?????д??????????，BCM??100ms?????????????BCM_10，Message ID??????1??10??????????Message ID?????2?，CLM/ECLM????????е?CLM/ECLM?????????
Note!mao!?????????ο????????CLM??????ù淶??Chery XX Project CLM Diagnostic Parameter Configuration Specification??
2!dun!BCM_10 will be scrolling sent and the sequence number is used to identify the message used by ECU. Sequence number ranges from 1DEC to 10DEC, AIPM only receives BCM_10 (0x5F0) with sequence number equal from 1DEC to 3DEC.
3.Message ID????.??BCM?????д??????????!dou!BCM??100ms?????????????BCM_10!dou!Message ID??????1??10??????????SN??????????????!dou!ICM????????е??????????
Note!mao!?????????ο????????ICM??????ù淶??Chery XX Project CLM Diagnostic Parameter Configuration Specification??";
CM_ BO_ 1077 "Source network message is \"Cyclic, 100ms\".
If no messages are received on source network, no messages are sent on the destination network.";
CM_ SG_ 1077 RvsExtMirrFbSts "?????????????·???????";
CM_ SG_ 1077 SRF_Hall2SensorError "HALL2??????????";
CM_ SG_ 1077 SRF_Hall1SensorError "HALL1??????????";
CM_ SG_ 1077 SRF_SunroofOverVolt "?????????";
CM_ SG_ 1077 SRF_SunroofUnderVolt "???????????";
CM_ SG_ 1077 SRF_LINCommunicationERROR "LIN??????";
CM_ SG_ 1077 SRF_SwitchError "??????";
CM_ SG_ 1077 SRF_OverHeatProtect "?????????????";
CM_ SG_ 1077 SRF_MotorRelayError "????????????";
CM_ SG_ 1077 AssociatedWithDriverModeFeedback "Associated With Driver Mode Feedback";
CM_ SG_ 1077 TheaterDimmingBrightnessFeedback "Theater Dimming Brightness Feedback";
CM_ SG_ 1077 TheaterDimmingColorFeedback "Theater Dimming Color Feedback";
CM_ SG_ 1077 SRF_Sunshade_OperateSts "???????????";
CM_ SG_ 1077 RRWindowSts "??????：
???????????????????6????!mao!comfort!dou!close ,open ,stop , closing , opening!dou!????????!dun!???!dun!???!dun!???!dun!???????к????????С?
???APP???startup???????????????????";
CM_ SG_ 1077 RLWindowSts "??????：
???????????????????6????!mao!comfort!dou!close ,open ,stop , closing , opening!dou!????????!dun!???!dun!???!dun!???!dun!???????к????????С?
???APP???startup???????????????????";
CM_ SG_ 1077 WindowInhibitSts "?????????";
CM_ SG_ 1077 FRWindow_Sts "??????：
???????????????????6????!mao!comfort!dou!close ,open ,stop , closing , opening!dou!????????!dun!???!dun!???!dun!???!dun!???????к????????С?
???APP???startup???????????????????";
CM_ SG_ 1077 FLWindow_Sts "??????：
???????????????????6????!mao!comfort!dou!close ,open ,stop , closing , opening!dou!????????!dun!???!dun!???!dun!???!dun!???????к????????С?
???APP???startup???????????????????";
CM_ SG_ 1077 Window_OperateSts "??????：
Window_OperateSts????2????!mao!active ,not active !dou!???????ж????????ж???";
CM_ SG_ 1077 Reserved_SRF_Error "?????????????????????，??0x0?????????????????????";
CM_ SG_ 1077 SRF_InitStatus "?????????λ";
CM_ SG_ 1077 AssociatedWithMusicModeFeedback "Associated With Music Mode Feedback";
CM_ SG_ 1077 TheaterDimmingStatusFeedback "Theater Dimming Status Feedback";
CM_ SG_ 1077 SRF_PositionSts "??????λ??
SRF_PostionSts???????????λ??!dou!0??????!dou!100%??????!dou!tilt?????!dou!?????????12????!mao!0!dun!10%!dun!20%......100%!dun!tilt!dou!???????????!dou!???統?????λ???????????!dou!????0-10%???!dou!??????10%!dou!???????.";
CM_ SG_ 1077 SRF_OperateSts "????
SRF_OperateSts??????7????!mao!tilt,close,opening,stop,closing,open, comfort open!mao!?????????!dun!???!dun!????!dun!???!dun!?????!dun!???!dun!???????????.";
CM_ SG_ 1077 TrailerConnectSts "?????????";
CM_ SG_ 1307 TireTemperature "?????????，??TyrePosition?????á?";
CM_ SG_ 1307 BCM_5_EnaSts "EnableStatus
IHU(DMC)?????????????????????ON/OFF????????BCM????????????????(????????????)";
CM_ SG_ 1307 BCM_5_clsdwarn "closed?warning
??й?????????????(????????????)";
CM_ SG_ 1307 TirePosition "???????λ???，??TyreTemperature?????????";
CM_ SG_ 1307 TirePositionWarning_RHRTire "???λ?????????，????????、???、???、?????";
CM_ SG_ 1307 TirePositionWarning_LHRTire "???λ?????????，????????、???、???、?????";
CM_ SG_ 1307 TirePositionWarning_RHFTire "?????λ?????????，????????、???、???、?????";
CM_ SG_ 1307 TirePositionWarning_LHFTire "?????λ?????????，????????、???、???、?????";
CM_ SG_ 1307 TirePressureWarningLampSts "??????????，?????、?????????????、?????????????????";
CM_ SG_ 914 DRLModeSts "????г????????";
CM_ SG_ 914 HeadlampDelayLightSts "?????????????????????????????????，???????";
CM_ SG_ 914 AutolockSts "?????????????";
CM_ SG_ 914 AutoFoldSts "?????????????";
CM_ SG_ 914 HeadlampHeightFeedbackSts "???????";
CM_ SG_ 914 RemoteLockFeedbackSts "????????";
CM_ SG_ 914 DrvrDoorUnlckOnlySts "???????????????????";
CM_ SG_ 914 FGHeat_Req_CmdFeedback "??絲??????????";
CM_ SG_ 914 RearFoglightFaultSts "0x0 shows RearFoglight  is in normal working status ,
0x1 shows RearFoglight is in fault state";
CM_ SG_ 914 WiperSensitivitySWSts "????RSM，BCM??000
δ?????????????????000??";
CM_ SG_ 914 RainSensorFailSts "ICM???????
????RSM!dou!BCM??0";
CM_ SG_ 914 ReversinglampFaultSts "0x0 shows Reversinglamp  is in normal working status ,
0x1 shows Reversinglamp is in  fault state";
CM_ SG_ 914 BrakelampFaultSts "0x0 shows Brakelamp  is in normal working status ,
0x1 shows Brakelamp is in a fault state,";
CM_ SG_ 914 FollowMeTimeSts "Not active=0000，??????δ????????，????????????????????";
CM_ SG_ 914 BCM_4_DirectionIndLeft "????????????????1，????????????0.";
CM_ SG_ 914 BCM_4_DirectionIndRight "????????????????1，????????????0.";
CM_ SG_ 914 LightDetected "0X0: ??
0x1: ??
?????LIN??????!mao!
????LIN???S_AUTO_LAMP??????????????????CAN??????????
?????LIN??????
BCM?????????????????????CAN??????????
?????????????ж????????????????0";
CM_ SG_ 914 BCM_4_ArmingSts "???????/?????????????
??????0x1,??????0x2
??????/??????? 0x1??0x2??????????0x0";
CM_ SG_ 1059 LDWWorkingSts "????????LDW?????????
00:LDW??????,?????????
01:LDW???????,??????
10:LDW???????,??????";
CM_ SG_ 1059 LDWWarningSts "LDW??????
01:?????????
10:?????????";
CM_ SG_ 1059 LDWLaneDetectionSts "LDW?????????";
CM_ SG_ 1059 LDWSensitivitySettingFeedback "LDW???????????
?????????????????????,Low????????????,High?????????????????????.";
CM_ SG_ 1059 LDWSwitchStsFeedback "LDW?????????????";
CM_ SG_ 1088 RadarWorkSts "???????????
1!dun!Active!mao!????PAS???????????!dou!???????????!dou!?????1??
2!dun!Not Active!mao!???????????PAS??????!dou!??0(Not Active)??";
CM_ SG_ 1088 RadarDetectSts "????????
????01!dou!RRM????????????????????
????10!dou!RRM??????????????????";
CM_ SG_ 1088 AudibleBeepRate "???????
1!dun!??????????????????Startup
2!dun!??????????!mao!??????????
3!dun!?????????RadarWorkSts??????";
CM_ SG_ 1088 LHMFRadarSensorDistance "??????????
??????!mao!????Sensor err
???????????????!mao!????0x1E

???????!mao!????=(D)*5+25
???????!mao!????0x1E
???????(??4 ??)!mao!????0x1E
0x1C~0x1D!mao!??Ч????";
CM_ SG_ 1088 RHMFRadarSensorDistance "??????????
??????!mao!????Sensor err
???????????????!mao!????0x1E

???????!mao!????=(D)*5+25
???????!mao!????0x1E
???????(??4 ??)!mao!????0x1E
0x1C~0x1D!mao!??Ч????";
CM_ SG_ 1088 RHFRadarSensorDistance "????????
??????!mao!????Sensor err
???????????????!mao!????0x1E

???????!mao!????=(D)*5+25
???????!mao!????0x1E
???????(??4 ??)!mao!????0x1E
0x1C~0x1D!mao!??Ч????";
CM_ SG_ 1088 LHFRadarSensorDistance "????????
??????!mao!????Sensor err
???????????????!mao!????0x1E

???????!mao!????=(D)*5+25
???????!mao!????0x1E
???????(??4 ??)!mao!????0x1E
0x1C~0x1D!mao!??Ч????";
CM_ SG_ 1088 RHRRadarSensorDistance "????????
??????!mao!????Sensor err
???????????????!mao!????0x3E

???????!mao!????=(D)*5+25
???????!mao!????0x3E
0x20~0x3D!mao!??Ч????\"";
CM_ SG_ 1088 LHMRRadarSensorDistance "???к??????
??????!mao!????Sensor err
???????????????!mao!????0x3E

???????!mao!????=(D)*5+25
???????!mao!????0x3E 
0x20~0x3D!mao!??Ч????";
CM_ SG_ 1088 RHMRRadarSensorDistance "???к??????
??????!mao!????Sensor err
???????????????!mao!????0x3E

???????!mao!????=(D)*5+25
???????!mao!????0x3E 
0x20~0x3D!mao!??Ч????";
CM_ SG_ 1088 PDC_GongRR_1 "Sound of rear speaker for rear right obstacle";
CM_ SG_ 1088 PDC_GongRL_1 "Sound of rear speaker for rear left obstacle";
CM_ SG_ 1088 PDC_GongFR_1 "Sound of front speaker for front right obstacle";
CM_ SG_ 1088 PDC_GongFL_1 "Sound of front speaker for front left obstacle";
CM_ SG_ 1088 LHRRadarSensorDistance "????????
??????!mao!????Sensor err
???????????????!mao!????0x3E

???????!mao!????=(D)*5+25
???????!mao!????0x3E
0x20~0x3D!mao!??Ч????";
BA_DEF_  "NmAsrCanMsgCycleTime" INT 1000 1000;
BA_DEF_  "NmAsrRepeatMessageTime" INT 3000 3000;
BA_DEF_  "NmAsrWaitBusSleepTime" INT 1500 1500;
BA_DEF_  "NmAsrTimeoutTime" INT 2500 2500;
BA_DEF_  "NmAsrBaseAddress" HEX 0 2047;
BA_DEF_  "NmAsrMessageCount" INT 128 128;
BA_DEF_  "NmType" STRING ;
BA_DEF_  "ILTxTimeout" INT 0 65535;
BA_DEF_  "Manufacturer" STRING ;
BA_DEF_ SG_  "GenSigTimeoutValue" INT 0 2147483647;
BA_DEF_ SG_  "GenSigStartValue" INT 0 2147483647;
BA_DEF_ SG_  "GenSigInactiveValue" INT 0 2147483647;
BA_DEF_ BO_  "TpTxIndex" INT 0 255;
BA_DEF_ BO_  "DiagUudtResponse" ENUM  "False","True";
BA_DEF_ BO_  "DiagResponse" ENUM  "No","Yes";
BA_DEF_ BO_  "DiagRequest" ENUM  "No","Yes";
BA_DEF_ BO_  "DiagState" ENUM  "No","Yes";
BA_DEF_ BO_  "NmAsrMessage" ENUM  "No","Yes";
BA_DEF_ BO_  "GenMsgFastOnStart" INT 0 65535;
BA_DEF_ BO_  "GenMsgCycleTimeFast" INT 0 65535;
BA_DEF_ BO_  "GenMsgNrOfRepetition" INT 0 65535;
BA_DEF_ BO_  "GenMsgStartDelayTime" INT 0 65535;
BA_DEF_ BO_  "GenMsgCycleTime" INT 0 65535;
BA_DEF_ BO_  "GenMsgDelayTime" INT 0 65535;
BA_DEF_ SG_  "GenSigSendType" ENUM  "Cyclic","OnWrite","OnWriteWithRepetition","OnChange","OnChangeWithRepetition","IfActive","IfActiveWithRepetition","NoSigSendType","OnChangeAndIfActive","OnChangeAndIfActiveWithRepetition";
BA_DEF_ BO_  "GenMsgSendType" ENUM  "Cyclic","NotUsed","NotUsed","NotUsed","NotUsed","NotUsed","NotUsed","IfActive","NoMsgSendType";
BA_DEF_ BO_  "GenMsgILSupport" ENUM  "No","Yes";
BA_DEF_ BU_  "NmStationAddress" HEX 0 255;
BA_DEF_ BU_  "NmAsrCanMsgReducedTime" INT 500 818;
BA_DEF_ BU_  "NmAsrCanMsgCycleOffset" INT 0 635;
BA_DEF_ BU_  "NmAsrNodeIdentifier" HEX 0 255;
BA_DEF_ BU_  "NmAsrNode" ENUM  "No","Yes";
BA_DEF_ BU_  "ILUsed" ENUM  "No","Yes";
BA_DEF_REL_ BU_SG_REL_  "GenSigTimeoutTime" INT 0 65535;
BA_DEF_DEF_  "NmAsrCanMsgCycleTime" 1000;
BA_DEF_DEF_  "NmAsrRepeatMessageTime" 3000;
BA_DEF_DEF_  "NmAsrWaitBusSleepTime" 1500;
BA_DEF_DEF_  "NmAsrTimeoutTime" 2500;
BA_DEF_DEF_  "NmAsrBaseAddress" 1536;
BA_DEF_DEF_  "NmAsrMessageCount" 128;
BA_DEF_DEF_  "NmType" "NmAsr";
BA_DEF_DEF_  "ILTxTimeout" 0;
BA_DEF_DEF_  "Manufacturer" "Vector";
BA_DEF_DEF_  "GenSigTimeoutValue" 0;
BA_DEF_DEF_  "GenSigStartValue" 0;
BA_DEF_DEF_  "GenSigInactiveValue" 0;
BA_DEF_DEF_  "TpTxIndex" 0;
BA_DEF_DEF_  "DiagUudtResponse" "False";
BA_DEF_DEF_  "DiagResponse" "No";
BA_DEF_DEF_  "DiagRequest" "No";
BA_DEF_DEF_  "DiagState" "No";
BA_DEF_DEF_  "NmAsrMessage" "No";
BA_DEF_DEF_  "GenMsgFastOnStart" 0;
BA_DEF_DEF_  "GenMsgCycleTimeFast" 0;
BA_DEF_DEF_  "GenMsgNrOfRepetition" 3;
BA_DEF_DEF_  "GenMsgStartDelayTime" 0;
BA_DEF_DEF_  "GenMsgCycleTime" 0;
BA_DEF_DEF_  "GenMsgDelayTime" 0;
BA_DEF_DEF_  "GenSigSendType" "NoSigSendType";
BA_DEF_DEF_  "GenMsgSendType" "NoMsgSendType";
BA_DEF_DEF_  "GenMsgILSupport" "No";
BA_DEF_DEF_  "NmStationAddress" 255;
BA_DEF_DEF_  "NmAsrCanMsgReducedTime" 575;
BA_DEF_DEF_  "NmAsrCanMsgCycleOffset" 0;
BA_DEF_DEF_  "NmAsrNodeIdentifier" 255;
BA_DEF_DEF_  "NmAsrNode" "No";
BA_DEF_DEF_  "ILUsed" "No";
BA_DEF_DEF_REL_ "GenSigTimeoutTime" 0;
BA_ "NmStationAddress" BU_ DMC 20;
BA_ "NmAsrNodeIdentifier" BU_ DMC 20;
BA_ "NmAsrNode" BU_ DMC 1;
BA_ "ILUsed" BU_ DMC 1;
BA_ "DiagResponse" BO_ 1944 1;
BA_ "GenMsgNrOfRepetition" BO_ 1944 0;
BA_ "DiagRequest" BO_ 1928 1;
BA_ "GenMsgNrOfRepetition" BO_ 1928 0;
BA_ "DiagState" BO_ 2015 1;
BA_ "GenMsgNrOfRepetition" BO_ 2015 0;
BA_ "GenMsgILSupport" BO_ 1443 1;
BA_ "GenMsgDelayTime" BO_ 1443 5;
BA_ "GenMsgCycleTimeFast" BO_ 1443 100;
BA_ "GenMsgILSupport" BO_ 798 1;
BA_ "GenMsgSendType" BO_ 798 0;
BA_ "GenMsgNrOfRepetition" BO_ 798 0;
BA_ "GenMsgCycleTime" BO_ 798 50;
BA_ "GenMsgILSupport" BO_ 1230 1;
BA_ "GenMsgSendType" BO_ 1230 0;
BA_ "GenMsgNrOfRepetition" BO_ 1230 0;
BA_ "GenMsgCycleTime" BO_ 1230 100;
BA_ "GenMsgILSupport" BO_ 789 1;
BA_ "GenMsgSendType" BO_ 789 0;
BA_ "GenMsgNrOfRepetition" BO_ 789 0;
BA_ "GenMsgCycleTime" BO_ 789 50;
BA_ "GenMsgILSupport" BO_ 1187 1;
BA_ "GenMsgSendType" BO_ 1187 0;
BA_ "GenMsgNrOfRepetition" BO_ 1187 0;
BA_ "GenMsgCycleTime" BO_ 1187 100;
BA_ "GenMsgILSupport" BO_ 1141 1;
BA_ "GenMsgSendType" BO_ 1141 0;
BA_ "GenMsgNrOfRepetition" BO_ 1141 0;
BA_ "GenMsgCycleTime" BO_ 1141 100;
BA_ "GenMsgILSupport" BO_ 864 1;
BA_ "GenMsgDelayTime" BO_ 864 5;
BA_ "GenMsgCycleTimeFast" BO_ 864 100;
BA_ "GenMsgILSupport" BO_ 945 1;
BA_ "GenMsgDelayTime" BO_ 945 5;
BA_ "GenMsgCycleTimeFast" BO_ 945 100;
BA_ "GenMsgILSupport" BO_ 777 1;
BA_ "GenMsgSendType" BO_ 777 0;
BA_ "GenMsgNrOfRepetition" BO_ 777 0;
BA_ "GenMsgCycleTime" BO_ 777 50;
BA_ "GenMsgILSupport" BO_ 933 1;
BA_ "GenMsgSendType" BO_ 933 0;
BA_ "GenMsgNrOfRepetition" BO_ 933 0;
BA_ "GenMsgCycleTime" BO_ 933 20;
BA_ "GenMsgILSupport" BO_ 1018 1;
BA_ "GenMsgSendType" BO_ 1018 0;
BA_ "GenMsgNrOfRepetition" BO_ 1018 0;
BA_ "GenMsgCycleTime" BO_ 1018 50;
BA_ "GenMsgILSupport" BO_ 1005 1;
BA_ "GenMsgSendType" BO_ 1005 0;
BA_ "GenMsgNrOfRepetition" BO_ 1005 0;
BA_ "GenMsgCycleTime" BO_ 1005 50;
BA_ "GenMsgILSupport" BO_ 990 1;
BA_ "GenMsgSendType" BO_ 990 0;
BA_ "GenMsgNrOfRepetition" BO_ 990 0;
BA_ "GenMsgCycleTime" BO_ 990 50;
BA_ "GenMsgILSupport" BO_ 988 1;
BA_ "GenMsgSendType" BO_ 988 0;
BA_ "GenMsgNrOfRepetition" BO_ 988 0;
BA_ "GenMsgCycleTime" BO_ 988 50;
BA_ "GenMsgILSupport" BO_ 1241 1;
BA_ "GenMsgSendType" BO_ 1241 0;
BA_ "GenMsgNrOfRepetition" BO_ 1241 0;
BA_ "GenMsgCycleTime" BO_ 1241 100;
BA_ "GenMsgILSupport" BO_ 1232 1;
BA_ "GenMsgSendType" BO_ 1232 0;
BA_ "GenMsgNrOfRepetition" BO_ 1232 0;
BA_ "GenMsgCycleTime" BO_ 1232 100;
BA_ "GenMsgILSupport" BO_ 1146 1;
BA_ "GenMsgSendType" BO_ 1146 0;
BA_ "GenMsgNrOfRepetition" BO_ 1146 0;
BA_ "GenMsgCycleTime" BO_ 1146 100;
BA_ "GenMsgILSupport" BO_ 1054 1;
BA_ "GenMsgSendType" BO_ 1054 0;
BA_ "GenMsgNrOfRepetition" BO_ 1054 0;
BA_ "GenMsgCycleTime" BO_ 1054 100;
BA_ "GenMsgILSupport" BO_ 1048 1;
BA_ "GenMsgSendType" BO_ 1048 0;
BA_ "GenMsgNrOfRepetition" BO_ 1048 0;
BA_ "GenMsgCycleTime" BO_ 1048 100;
BA_ "GenMsgILSupport" BO_ 1258 1;
BA_ "GenMsgSendType" BO_ 1258 0;
BA_ "GenMsgNrOfRepetition" BO_ 1258 0;
BA_ "GenMsgCycleTime" BO_ 1258 100;
BA_ "GenMsgILSupport" BO_ 1450 1;
BA_ "GenMsgSendType" BO_ 1450 0;
BA_ "GenMsgNrOfRepetition" BO_ 1450 0;
BA_ "GenMsgCycleTime" BO_ 1450 1000;
BA_ "GenMsgILSupport" BO_ 1158 1;
BA_ "GenMsgSendType" BO_ 1158 0;
BA_ "GenMsgNrOfRepetition" BO_ 1158 0;
BA_ "GenMsgCycleTime" BO_ 1158 100;
BA_ "GenMsgILSupport" BO_ 1095 1;
BA_ "GenMsgSendType" BO_ 1095 0;
BA_ "GenMsgNrOfRepetition" BO_ 1095 0;
BA_ "GenMsgCycleTime" BO_ 1095 100;
BA_ "GenMsgILSupport" BO_ 745 1;
BA_ "GenMsgSendType" BO_ 745 0;
BA_ "GenMsgNrOfRepetition" BO_ 745 0;
BA_ "GenMsgCycleTime" BO_ 745 10;
BA_ "NmAsrMessage" BO_ 1556 1;
BA_ "GenMsgSendType" BO_ 1556 0;
BA_ "GenMsgNrOfRepetition" BO_ 1556 0;
BA_ "GenMsgCycleTime" BO_ 1556 1000;
BA_ "GenMsgILSupport" BO_ 1090 1;
BA_ "GenMsgSendType" BO_ 1090 0;
BA_ "GenMsgNrOfRepetition" BO_ 1090 0;
BA_ "GenMsgCycleTime" BO_ 1090 100;
BA_ "GenMsgILSupport" BO_ 1078 1;
BA_ "GenMsgSendType" BO_ 1078 0;
BA_ "GenMsgNrOfRepetition" BO_ 1078 0;
BA_ "GenMsgCycleTime" BO_ 1078 100;
BA_ "GenMsgILSupport" BO_ 1152 1;
BA_ "GenMsgSendType" BO_ 1152 0;
BA_ "GenMsgNrOfRepetition" BO_ 1152 0;
BA_ "GenMsgCycleTime" BO_ 1152 50;
BA_ "GenMsgILSupport" BO_ 1219 1;
BA_ "GenMsgSendType" BO_ 1219 0;
BA_ "GenMsgNrOfRepetition" BO_ 1219 0;
BA_ "GenMsgCycleTime" BO_ 1219 100;
BA_ "GenMsgILSupport" BO_ 1025 1;
BA_ "GenMsgSendType" BO_ 1025 0;
BA_ "GenMsgNrOfRepetition" BO_ 1025 0;
BA_ "GenMsgCycleTime" BO_ 1025 100;
BA_ "GenMsgILSupport" BO_ 1407 1;
BA_ "GenMsgSendType" BO_ 1407 0;
BA_ "GenMsgNrOfRepetition" BO_ 1407 0;
BA_ "GenMsgCycleTime" BO_ 1407 1000;
BA_ "GenMsgILSupport" BO_ 1322 1;
BA_ "GenMsgSendType" BO_ 1322 0;
BA_ "GenMsgNrOfRepetition" BO_ 1322 0;
BA_ "GenMsgCycleTime" BO_ 1322 500;
BA_ "GenMsgILSupport" BO_ 1247 1;
BA_ "GenMsgSendType" BO_ 1247 0;
BA_ "GenMsgNrOfRepetition" BO_ 1247 0;
BA_ "GenMsgCycleTime" BO_ 1247 500;
BA_ "GenMsgILSupport" BO_ 533 1;
BA_ "GenMsgNrOfRepetition" BO_ 533 2;
BA_ "GenMsgDelayTime" BO_ 533 5;
BA_ "GenMsgCycleTimeFast" BO_ 533 100;
BA_ "GenMsgILSupport" BO_ 1329 1;
BA_ "GenMsgSendType" BO_ 1329 0;
BA_ "GenMsgNrOfRepetition" BO_ 1329 0;
BA_ "GenMsgCycleTime" BO_ 1329 500;
BA_ "GenMsgILSupport" BO_ 1066 1;
BA_ "GenMsgSendType" BO_ 1066 0;
BA_ "GenMsgNrOfRepetition" BO_ 1066 0;
BA_ "GenMsgCycleTime" BO_ 1066 100;
BA_ "GenMsgILSupport" BO_ 647 1;
BA_ "GenMsgSendType" BO_ 647 0;
BA_ "GenMsgNrOfRepetition" BO_ 647 0;
BA_ "GenMsgCycleTime" BO_ 647 20;
BA_ "GenMsgILSupport" BO_ 1107 1;
BA_ "GenMsgSendType" BO_ 1107 0;
BA_ "GenMsgNrOfRepetition" BO_ 1107 0;
BA_ "GenMsgCycleTime" BO_ 1107 500;
BA_ "GenMsgILSupport" BO_ 1106 1;
BA_ "GenMsgSendType" BO_ 1106 0;
BA_ "GenMsgNrOfRepetition" BO_ 1106 0;
BA_ "GenMsgCycleTime" BO_ 1106 100;
BA_ "GenMsgILSupport" BO_ 1072 1;
BA_ "GenMsgSendType" BO_ 1072 0;
BA_ "GenMsgNrOfRepetition" BO_ 1072 0;
BA_ "GenMsgCycleTime" BO_ 1072 20;
BA_ "GenMsgILSupport" BO_ 1275 1;
BA_ "GenMsgSendType" BO_ 1275 0;
BA_ "GenMsgNrOfRepetition" BO_ 1275 0;
BA_ "GenMsgCycleTime" BO_ 1275 100;
BA_ "GenMsgILSupport" BO_ 1306 1;
BA_ "GenMsgSendType" BO_ 1306 0;
BA_ "GenMsgNrOfRepetition" BO_ 1306 0;
BA_ "GenMsgDelayTime" BO_ 1306 5;
BA_ "GenMsgCycleTime" BO_ 1306 100;
BA_ "GenMsgILSupport" BO_ 1226 1;
BA_ "GenMsgSendType" BO_ 1226 0;
BA_ "GenMsgNrOfRepetition" BO_ 1226 0;
BA_ "GenMsgCycleTime" BO_ 1226 100;
BA_ "GenMsgILSupport" BO_ 1419 1;
BA_ "GenMsgSendType" BO_ 1419 0;
BA_ "GenMsgNrOfRepetition" BO_ 1419 0;
BA_ "GenMsgCycleTime" BO_ 1419 1000;
BA_ "GenMsgILSupport" BO_ 1481 1;
BA_ "GenMsgSendType" BO_ 1481 0;
BA_ "GenMsgNrOfRepetition" BO_ 1481 0;
BA_ "GenMsgCycleTime" BO_ 1481 2000;
BA_ "GenMsgILSupport" BO_ 1224 1;
BA_ "GenMsgSendType" BO_ 1224 0;
BA_ "GenMsgNrOfRepetition" BO_ 1224 0;
BA_ "GenMsgCycleTime" BO_ 1224 100;
BA_ "GenMsgILSupport" BO_ 746 1;
BA_ "GenMsgSendType" BO_ 746 0;
BA_ "GenMsgNrOfRepetition" BO_ 746 0;
BA_ "GenMsgCycleTime" BO_ 746 20;
BA_ "GenMsgILSupport" BO_ 1008 1;
BA_ "GenMsgNrOfRepetition" BO_ 1008 0;
BA_ "GenMsgCycleTimeFast" BO_ 1008 20;
BA_ "GenMsgILSupport" BO_ 901 1;
BA_ "GenMsgSendType" BO_ 901 0;
BA_ "GenMsgNrOfRepetition" BO_ 901 0;
BA_ "GenMsgCycleTime" BO_ 901 50;
BA_ "GenMsgILSupport" BO_ 1315 1;
BA_ "GenMsgSendType" BO_ 1315 0;
BA_ "GenMsgNrOfRepetition" BO_ 1315 0;
BA_ "GenMsgCycleTime" BO_ 1315 500;
BA_ "GenMsgILSupport" BO_ 1063 1;
BA_ "GenMsgSendType" BO_ 1063 0;
BA_ "GenMsgNrOfRepetition" BO_ 1063 0;
BA_ "GenMsgCycleTime" BO_ 1063 100;
BA_ "GenMsgILSupport" BO_ 1520 1;
BA_ "GenMsgNrOfRepetition" BO_ 1520 0;
BA_ "GenMsgCycleTimeFast" BO_ 1520 100;
BA_ "GenMsgILSupport" BO_ 1077 1;
BA_ "GenMsgSendType" BO_ 1077 0;
BA_ "GenMsgNrOfRepetition" BO_ 1077 0;
BA_ "GenMsgCycleTime" BO_ 1077 100;
BA_ "GenMsgILSupport" BO_ 1514 1;
BA_ "GenMsgNrOfRepetition" BO_ 1514 0;
BA_ "GenMsgCycleTimeFast" BO_ 1514 1000;
BA_ "GenMsgILSupport" BO_ 1505 1;
BA_ "GenMsgNrOfRepetition" BO_ 1505 0;
BA_ "GenMsgCycleTimeFast" BO_ 1505 1000;
BA_ "GenMsgILSupport" BO_ 1307 1;
BA_ "GenMsgSendType" BO_ 1307 0;
BA_ "GenMsgNrOfRepetition" BO_ 1307 0;
BA_ "GenMsgCycleTime" BO_ 1307 500;
BA_ "GenMsgILSupport" BO_ 914 1;
BA_ "GenMsgSendType" BO_ 914 0;
BA_ "GenMsgNrOfRepetition" BO_ 914 0;
BA_ "GenMsgCycleTime" BO_ 914 20;
BA_ "GenMsgILSupport" BO_ 1059 1;
BA_ "GenMsgSendType" BO_ 1059 0;
BA_ "GenMsgNrOfRepetition" BO_ 1059 0;
BA_ "GenMsgCycleTime" BO_ 1059 100;
BA_ "GenMsgILSupport" BO_ 1088 1;
BA_ "GenMsgSendType" BO_ 1088 0;
BA_ "GenMsgNrOfRepetition" BO_ 1088 0;
BA_ "GenMsgCycleTime" BO_ 1088 100;
BA_ "GenSigSendType" SG_ 3221225472 ICM_Cyc100_Fuel_State 0;
BA_ "GenSigSendType" SG_ 1944 Diag_DMC_RES 1;
BA_ "GenSigSendType" SG_ 1928 Diag_DMC_REQ 1;
BA_ "GenSigSendType" SG_ 2015 DIAG_OBD_REQ_Broadcast 1;
BA_ "GenSigSendType" SG_ 1443 BitStatus_TCU 1;
BA_ "GenSigSendType" SG_ 798 TMR_TMRSysFault 0;
BA_ "GenSigSendType" SG_ 1230 TMF_MILSts 0;
BA_ "GenSigStartValue" SG_ 1230 TMF_MILSts 2;
BA_ "GenSigSendType" SG_ 789 TMF_SpdAct 0;
BA_ "GenSigStartValue" SG_ 789 TMF_SpdAct 32767;
BA_ "GenSigSendType" SG_ 789 TMF_TMFSysFault 0;
BA_ "GenSigSendType" SG_ 1187 RHM_1_DRLFaildSts 0;
BA_ "GenSigSendType" SG_ 1187 RHM_1_RHTurnLiFaildSts 0;
BA_ "GenSigSendType" SG_ 1187 RHM_1_ParkLiFaildSts 0;
BA_ "GenSigSendType" SG_ 1187 RHM_1_LoBeamFaildSts 0;
BA_ "GenSigSendType" SG_ 1187 RHM_1_HiBeamFaildSts 0;
BA_ "GenSigSendType" SG_ 1141 FrontPDCObjectDistance 0;
BA_ "GenSigSendType" SG_ 1141 RearPDCObjectDistance 0;
BA_ "GenSigSendType" SG_ 1141 LHSFRadarSensorDistance 0;
BA_ "GenSigStartValue" SG_ 1141 LHSFRadarSensorDistance 126;
BA_ "GenSigSendType" SG_ 1141 RHSFRadarSensorDistance 0;
BA_ "GenSigStartValue" SG_ 1141 RHSFRadarSensorDistance 126;
BA_ "GenSigSendType" SG_ 1141 LHSRRadarSensorDistance 0;
BA_ "GenSigStartValue" SG_ 1141 LHSRRadarSensorDistance 126;
BA_ "GenSigSendType" SG_ 1141 RHSRRadarSensorDistance 0;
BA_ "GenSigStartValue" SG_ 1141 RHSRRadarSensorDistance 126;
BA_ "GenSigSendType" SG_ 864 MFS_ICM_Right 1;
BA_ "GenSigSendType" SG_ 864 MFS_ICM_Left 1;
BA_ "GenSigSendType" SG_ 864 MFS_ICM_Down 1;
BA_ "GenSigSendType" SG_ 864 MFS_ICM_UP 1;
BA_ "GenSigSendType" SG_ 864 MFS_Menu 1;
BA_ "GenSigSendType" SG_ 945 MFS_ICMFctChg 1;
BA_ "GenSigSendType" SG_ 945 MFS_Start_Pause 1;
BA_ "GenSigSendType" SG_ 945 MFS_Customize 0;
BA_ "GenSigSendType" SG_ 945 MFS_WeChat 1;
BA_ "GenSigSendType" SG_ 945 TJA_ICA_ON_OFF 0;
BA_ "GenSigSendType" SG_ 945 MFS_Mute 1;
BA_ "GenSigSendType" SG_ 945 MFS_VoiceRecognition 0;
BA_ "GenSigSendType" SG_ 945 MFS_PhoneHangUP 1;
BA_ "GenSigSendType" SG_ 945 MFS_PhonePickUP 1;
BA_ "GenSigSendType" SG_ 945 MFS_SeekDown 0;
BA_ "GenSigSendType" SG_ 945 MFS_SeekUp 0;
BA_ "GenSigSendType" SG_ 945 MFS_VolumeDown 0;
BA_ "GenSigSendType" SG_ 945 MFS_VolumeUp 0;
BA_ "GenSigSendType" SG_ 945 MFS_Mode 1;
BA_ "GenSigSendType" SG_ 777 ISGF_ISGFSysFault 0;
BA_ "GenSigSendType" SG_ 933 AWBRequest 0;
BA_ "GenSigSendType" SG_ 933 AEBReq 0;
BA_ "GenSigSendType" SG_ 933 AEBDecCtrlRequest 0;
BA_ "GenSigSendType" SG_ 1018 FCM_FRM_9_RiObjHozDstY 0;
BA_ "GenSigStartValue" SG_ 1018 FCM_FRM_9_RiObjHozDstY 500;
BA_ "GenSigSendType" SG_ 1018 FCM_FRM_9_RiObjLgtDstX 0;
BA_ "GenSigSendType" SG_ 1018 FCM_FRM_9_RiObjTyp 0;
BA_ "GenSigSendType" SG_ 1018 FCM_FRM_9_RiObjID 0;
BA_ "GenSigSendType" SG_ 1018 FCM_FRM_9_LeObjHozDstY 0;
BA_ "GenSigStartValue" SG_ 1018 FCM_FRM_9_LeObjHozDstY 500;
BA_ "GenSigSendType" SG_ 1018 FCM_FRM_9_LeObjLgtDstX 0;
BA_ "GenSigSendType" SG_ 1018 FCM_FRM_9_LeObjTyp 0;
BA_ "GenSigSendType" SG_ 1018 FCM_FRM_9_LeObjID 0;
BA_ "GenSigSendType" SG_ 1005 FCM_FRM_8_WSOSONOFFSts 0;
BA_ "GenSigSendType" SG_ 1005 FCM_FRM_8_IDSONOFFSts 0;
BA_ "GenSigSendType" SG_ 1005 FCM_FRM_8_FrntFarObjHozDstY 0;
BA_ "GenSigStartValue" SG_ 1005 FCM_FRM_8_FrntFarObjHozDstY 500;
BA_ "GenSigSendType" SG_ 1005 FCM_FRM_8_FrntFarObjLgtDstX 0;
BA_ "GenSigSendType" SG_ 1005 FCM_FRM_8_FrntFarObjTyp 0;
BA_ "GenSigSendType" SG_ 1005 FCM_FRM_8_FrntFarObjID 0;
BA_ "GenSigSendType" SG_ 1005 FCM_FRM_8_ACCObjHozDstY 0;
BA_ "GenSigStartValue" SG_ 1005 FCM_FRM_8_ACCObjHozDstY 500;
BA_ "GenSigSendType" SG_ 1005 FCM_FRM_8_ACCObjLgtDstX 0;
BA_ "GenSigSendType" SG_ 1005 FCM_FRM_8_ACCObjTyp 0;
BA_ "GenSigSendType" SG_ 1005 FCM_FRM_8_ACCObjID 0;
BA_ "GenSigSendType" SG_ 990 FCM_7_NeborRiLineCrvt 0;
BA_ "GenSigStartValue" SG_ 990 FCM_7_NeborRiLineCrvt 260;
BA_ "GenSigSendType" SG_ 990 FCM_7_NeborRiLineHozlDst 0;
BA_ "GenSigStartValue" SG_ 990 FCM_7_NeborRiLineHozlDst 250;
BA_ "GenSigSendType" SG_ 990 FCM_7_NeborRiLineTyp 0;
BA_ "GenSigSendType" SG_ 990 FCM_7_NeborRiLineColor 0;
BA_ "GenSigSendType" SG_ 990 FCM_7_NeborRiLineID 0;
BA_ "GenSigSendType" SG_ 990 FCM_7_NeborLeLineCrvt 0;
BA_ "GenSigStartValue" SG_ 990 FCM_7_NeborLeLineCrvt 260;
BA_ "GenSigSendType" SG_ 990 FCM_7_NeborLeLineHozlDst 0;
BA_ "GenSigStartValue" SG_ 990 FCM_7_NeborLeLineHozlDst 250;
BA_ "GenSigSendType" SG_ 990 FCM_7_NeborLeLineTyp 0;
BA_ "GenSigSendType" SG_ 990 FCM_7_NeborLeLineColor 0;
BA_ "GenSigSendType" SG_ 990 FCM_7_NeborLeLineID 0;
BA_ "GenSigSendType" SG_ 988 FCM_6_EgoRiLineCrvt 0;
BA_ "GenSigStartValue" SG_ 988 FCM_6_EgoRiLineCrvt 260;
BA_ "GenSigSendType" SG_ 988 FCM_6_EgoRiLineHozlDst 0;
BA_ "GenSigStartValue" SG_ 988 FCM_6_EgoRiLineHozlDst 250;
BA_ "GenSigSendType" SG_ 988 FCM_6_EgoRiLineTyp 0;
BA_ "GenSigSendType" SG_ 988 FCM_6_EgoRiLineColor 0;
BA_ "GenSigSendType" SG_ 988 FCM_6_EgoRiLineID 0;
BA_ "GenSigSendType" SG_ 988 FCM_6_EgoLeLineCrvt 0;
BA_ "GenSigStartValue" SG_ 988 FCM_6_EgoLeLineCrvt 260;
BA_ "GenSigSendType" SG_ 988 FCM_6_EgoLeLineHozlDst 0;
BA_ "GenSigStartValue" SG_ 988 FCM_6_EgoLeLineHozlDst 250;
BA_ "GenSigSendType" SG_ 988 FCM_6_EgoLeLineTyp 0;
BA_ "GenSigSendType" SG_ 988 FCM_6_EgoLeLineColor 0;
BA_ "GenSigSendType" SG_ 988 FCM_6_EgoLeLineID 0;
BA_ "GenSigSendType" SG_ 1241 FuelTankLidSystemFailureSts 0;
BA_ "GenSigSendType" SG_ 1241 FuelTankPressureConditionReached 0;
BA_ "GenSigSendType" SG_ 1232 Energy_Flow_Sts 0;
BA_ "GenSigSendType" SG_ 1232 Battery_Sts 0;
BA_ "GenSigSendType" SG_ 1232 Battery_Temp_Sts 0;
BA_ "GenSigSendType" SG_ 1146 AllWarningInfo 0;
BA_ "GenSigSendType" SG_ 1054 DCDC_DCDCSysFault 0;
BA_ "GenSigSendType" SG_ 1048 DCDC_EnableSts 0;
BA_ "GenSigSendType" SG_ 1048 DCDC_1_ActDisOutPower 0;
BA_ "GenSigSendType" SG_ 1258 BMSH_BattFaultLampSts 0;
BA_ "GenSigSendType" SG_ 1258 BMSH_PackThermalRunawayLight 0;
BA_ "GenSigSendType" SG_ 1450 BMSH_BatteryTempLightSts 0;
BA_ "GenSigSendType" SG_ 1450 BMSH_LowSOC 0;
BA_ "GenSigSendType" SG_ 1158 AWDoutserviceDispRq 0;
BA_ "GenSigSendType" SG_ 1095 AFS_FaultSts 0;
BA_ "GenSigSendType" SG_ 745 AEBdecAvailable 0;
BA_ "GenSigSendType" SG_ 745 AEBdecActive 0;
BA_ "GenSigSendType" SG_ 1556 WakeupSource_ICM 0;
BA_ "GenSigSendType" SG_ 1556 usrData4_ICM 0;
BA_ "GenSigSendType" SG_ 1556 usrData3_ICM 0;
BA_ "GenSigSendType" SG_ 1556 usrData2_ICM 0;
BA_ "GenSigSendType" SG_ 1556 ECUSPEC_AWAKE_ICM 0;
BA_ "GenSigSendType" SG_ 1556 DIAGNOSTIC_AWAKE_ICM 0;
BA_ "GenSigSendType" SG_ 1556 IGNITION_AWAKE_ICM 0;
BA_ "GenSigSendType" SG_ 1556 NETWORK_AWAKE_ICM 0;
BA_ "GenSigSendType" SG_ 1556 ECUSPEC_WAKEUP_ICM 0;
BA_ "GenSigSendType" SG_ 1556 NETWORK_WAKEUP_ICM 0;
BA_ "GenSigSendType" SG_ 1556 RESET_WAKEUP_ICM 0;
BA_ "GenSigSendType" SG_ 1556 IGNITION_WAKEUP_ICM 0;
BA_ "GenSigSendType" SG_ 1556 usrData0_ICM 0;
BA_ "GenSigSendType" SG_ 1556 NMm_ICM_Reserved1_CBV 0;
BA_ "GenSigSendType" SG_ 1556 RMR_ICM_CBV 0;
BA_ "GenSigSendType" SG_ 1556 srcNodeID_ICM_SNII 0;
BA_ "GenSigStartValue" SG_ 1556 srcNodeID_ICM_SNII 20;
BA_ "GenSigSendType" SG_ 1090 SCU_1_LuggageModFlagSts 0;
BA_ "GenSigSendType" SG_ 1090 SCU_1_JourneyModFlagSts 0;
BA_ "GenSigSendType" SG_ 1090 SCU_1_SmartSpaceWarn 2;
BA_ "GenSigSendType" SG_ 1090 SCU_1_ModCheckFb 2;
BA_ "GenSigSendType" SG_ 1090 SCU_1_BedModFlagSts 0;
BA_ "GenSigSendType" SG_ 1090 SCU_1_FRSeatVentilationFbSts 0;
BA_ "GenSigSendType" SG_ 1090 SCU_1_FLSeatVentilationFbSts 0;
BA_ "GenSigSendType" SG_ 1090 Seat_ExtMirror_PositionInfo 0;
BA_ "GenSigSendType" SG_ 1090 SCURelateKeyOrFaceIDFeedbackSts 0;
BA_ "GenSigSendType" SG_ 1090 Seat_ExtMirror_MemorySts 0;
BA_ "GenSigSendType" SG_ 1090 SCU_1_FRSeatHeatFbSts 0;
BA_ "GenSigSendType" SG_ 1090 SCU_1_FLSeatHeatFbSts 0;
BA_ "GenSigSendType" SG_ 1090 ReverseExtMirrorFeedbackSts 0;
BA_ "GenSigSendType" SG_ 1090 EasyEntryFeedbackSts 0;
BA_ "GenSigSendType" SG_ 1090 Seat_ExtMirror_MemoryReq 0;
BA_ "GenSigSendType" SG_ 1090 Seat_ExtMirror_MemoryEnable 0;
BA_ "GenSigSendType" SG_ 1090 MemoryKeySts 0;
BA_ "GenSigSendType" SG_ 1078 PLG_PositionSts 0;
BA_ "GenSigStartValue" SG_ 1078 PLG_PositionSts 100;
BA_ "GenSigSendType" SG_ 1078 PLG_OperateSts 0;
BA_ "GenSigSendType" SG_ 1078 PLG_Set_MaxPosition 0;
BA_ "GenSigStartValue" SG_ 1078 PLG_Set_MaxPosition 100;
BA_ "GenSigSendType" SG_ 1152 RemoteStartSts 0;
BA_ "GenSigSendType" SG_ 1152 SmartSystemWarning4_3 0;
BA_ "GenSigSendType" SG_ 1152 SmartSystemWarning2_0 0;
BA_ "GenSigSendType" SG_ 1152 SmartSystemWarning2_2 0;
BA_ "GenSigSendType" SG_ 1152 SmartSystemWarning1_0 0;
BA_ "GenSigSendType" SG_ 1152 SmartSystemWarning1_1 0;
BA_ "GenSigSendType" SG_ 1152 SmartSystemWarning1_3 0;
BA_ "GenSigSendType" SG_ 1152 SmartSystemWarning3_1 0;
BA_ "GenSigSendType" SG_ 1152 SmartSystemWarning3_2 0;
BA_ "GenSigSendType" SG_ 1152 SmartSystemWarning4_2 0;
BA_ "GenSigSendType" SG_ 1219 PAS_1_DriverDoorSIllSts 0;
BA_ "GenSigSendType" SG_ 1025 ESCLNotLocked 0;
BA_ "GenSigSendType" SG_ 1025 ESCLUnlockJamming 0;
BA_ "GenSigSendType" SG_ 1025 ESCLFunctionFailure 0;
BA_ "GenSigSendType" SG_ 1025 ESCLCriticalFailure 0;
BA_ "GenSigSendType" SG_ 1407 ICM_VINcode_17 0;
BA_ "GenSigSendType" SG_ 1407 ICM_VINcode_16 0;
BA_ "GenSigSendType" SG_ 1407 ICM_VINcode_15 0;
BA_ "GenSigSendType" SG_ 1407 ICM_VINcode_14 0;
BA_ "GenSigSendType" SG_ 1407 ICM_VINcode_13 0;
BA_ "GenSigSendType" SG_ 1407 ICM_VINcode_12 0;
BA_ "GenSigSendType" SG_ 1407 ICM_VINcode_11 0;
BA_ "GenSigSendType" SG_ 1407 ICM_VINcode_10 0;
BA_ "GenSigSendType" SG_ 1322 Sigcycfucns 0;
BA_ "GenSigStartValue" SG_ 1322 Sigcycfucns 2550;
BA_ "GenSigSendType" SG_ 1322 ResidualOdometer_PHEV 0;
BA_ "GenSigStartValue" SG_ 1322 ResidualOdometer_PHEV 4095;
BA_ "GenSigSendType" SG_ 1247 ICM_9_EVTotOdo 0;
BA_ "GenSigSendType" SG_ 1247 ICM_9_HEVTotOdo 0;
BA_ "GenSigSendType" SG_ 533 ICM_8_FrntRadarSwt 2;
BA_ "GenSigSendType" SG_ 533 ICM_ESPSwitchCmd 2;
BA_ "GenSigSendType" SG_ 533 ICM_ISS_Switch 2;
BA_ "GenSigSendType" SG_ 533 SetICMAlarm 2;
BA_ "GenSigSendType" SG_ 1329 SIA_IntervalDistance 0;
BA_ "GenSigSendType" SG_ 1329 ICM_7_Reserved2 0;
BA_ "GenSigSendType" SG_ 1329 SIA_LastDay 0;
BA_ "GenSigStartValue" SG_ 1329 SIA_LastDay 1;
BA_ "GenSigSendType" SG_ 1329 SIA_LastYear 0;
BA_ "GenSigStartValue" SG_ 1329 SIA_LastYear 19;
BA_ "GenSigSendType" SG_ 1329 SIA_LastMonth 0;
BA_ "GenSigStartValue" SG_ 1329 SIA_LastMonth 1;
BA_ "GenSigSendType" SG_ 1329 SIA_IntervalTime 0;
BA_ "GenSigSendType" SG_ 1329 ICM_7_Reserved1 0;
BA_ "GenSigSendType" SG_ 1329 SIA_LastODO 0;
BA_ "GenSigSendType" SG_ 1066 Set_HundECAverHisClearSts 0;
BA_ "GenSigSendType" SG_ 1066 ICM_6_SumTrip 0;
BA_ "GenSigSendType" SG_ 1066 TotalOdometer_km_OBDValidData 0;
BA_ "GenSigSendType" SG_ 1066 TotalOdometer_km_OBD 0;
BA_ "GenSigSendType" SG_ 1066 TotODOMtrBkpEna 0;
BA_ "GenSigSendType" SG_ 1066 DrivermodeReq 0;
BA_ "GenSigSendType" SG_ 647 ICM_5_Checksum 0;
BA_ "GenSigSendType" SG_ 647 ICM_5_MessageCounter 0;
BA_ "GenSigSendType" SG_ 647 ICM_DVDAudibleAlarmStyle 0;
BA_ "GenSigSendType" SG_ 647 ICM_DVDAudibleAlarm 0;
BA_ "GenSigSendType" SG_ 647 BrakeFluidWarning 0;
BA_ "GenSigSendType" SG_ 647 ICM_5_Reserved_2 0;
BA_ "GenSigSendType" SG_ 647 ACC_Kilometre_Mile 0;
BA_ "GenSigSendType" SG_ 647 DriverSeatBeltSwitchQbit 0;
BA_ "GenSigSendType" SG_ 647 ICM_5_DriverSeatBeltSwitch 0;
BA_ "GenSigSendType" SG_ 647 CTP_DriveModeSet 0;
BA_ "GenSigSendType" SG_ 647 ICM_5_AlrmVolCtrl 4;
BA_ "GenSigSendType" SG_ 647 ICM_5_BackLiBriAdjmt 4;
BA_ "GenSigSendType" SG_ 647 AverageFuelConsumption50 0;
BA_ "GenSigSendType" SG_ 647 ICM_5_FuelLevel 0;
BA_ "GenSigSendType" SG_ 647 FuelValidData 0;
BA_ "GenSigSendType" SG_ 647 FuelOutOfRange 0;
BA_ "GenSigSendType" SG_ 647 FuelShortPower 0;
BA_ "GenSigSendType" SG_ 647 FuelShortGround 0;
BA_ "GenSigSendType" SG_ 647 HandBrakeSystemStsValidData 0;
BA_ "GenSigSendType" SG_ 647 HandBrakeSystemSts 0;
BA_ "GenSigSendType" SG_ 1107 Reserved_ThemeTypeFeedback 0;
BA_ "GenSigSendType" SG_ 1107 TimeFormat 0;
BA_ "GenSigSendType" SG_ 1107 FatigureDrivingWarning 0;
BA_ "GenSigSendType" SG_ 1107 CurrentTimeYear 0;
BA_ "GenSigSendType" SG_ 1107 CurrentTimeMonth 0;
BA_ "GenSigStartValue" SG_ 1107 CurrentTimeMonth 1;
BA_ "GenSigSendType" SG_ 1107 CurrentTimeDay 0;
BA_ "GenSigStartValue" SG_ 1107 CurrentTimeDay 1;
BA_ "GenSigSendType" SG_ 1107 ResidualOdometer 0;
BA_ "GenSigStartValue" SG_ 1107 ResidualOdometer 1023;
BA_ "GenSigSendType" SG_ 1107 CurrentTimeSecond 0;
BA_ "GenSigSendType" SG_ 1107 ICM_BrightnessLevel 0;
BA_ "GenSigSendType" SG_ 1107 MaintainWarning 0;
BA_ "GenSigSendType" SG_ 1107 LowFuleWarning 0;
BA_ "GenSigSendType" SG_ 1107 FatigureDrivingTime 0;
BA_ "GenSigStartValue" SG_ 1107 FatigureDrivingTime 1;
BA_ "GenSigSendType" SG_ 1107 CurrentTimeMinute 0;
BA_ "GenSigSendType" SG_ 1107 CurrentTimeHour 0;
BA_ "GenSigSendType" SG_ 1106 ICM_2_Ajuststate 0;
BA_ "GenSigSendType" SG_ 1106 FrontSeatBeltAlarmLight 0;
BA_ "GenSigSendType" SG_ 1106 ICM_2_OverSpeedValue 0;
BA_ "GenSigSendType" SG_ 1106 QDashACCFail 0;
BA_ "GenSigSendType" SG_ 1106 DISFail 0;
BA_ "GenSigSendType" SG_ 1106 ICM_2_LoWshLqdWarn 0;
BA_ "GenSigSendType" SG_ 1106 BackLightLevel 0;
BA_ "GenSigSendType" SG_ 1106 TemperatureUnit_ICM 0;
BA_ "GenSigSendType" SG_ 1106 ICM_2_Reserved1 0;
BA_ "GenSigSendType" SG_ 1106 ICM_2_ShdSts 0;
BA_ "GenSigSendType" SG_ 1106 AirBagLampFailSts 0;
BA_ "GenSigSendType" SG_ 1106 AverageFuelConsumption 0;
BA_ "GenSigSendType" SG_ 1072 TotalOdometer_km 0;
BA_ "GenSigSendType" SG_ 1072 EngineCoolantTempertureHighWarn 0;
BA_ "GenSigSendType" SG_ 1072 DrvrSeatBltSwtForPPMI 0;
BA_ "GenSigStartValue" SG_ 1072 DrvrSeatBltSwtForPPMI 1;
BA_ "GenSigSendType" SG_ 1072 FuelLevel 0;
BA_ "GenSigSendType" SG_ 1072 ICM_1MessageCounter 0;
BA_ "GenSigSendType" SG_ 1072 FuelLevelFailSts 0;
BA_ "GenSigSendType" SG_ 1072 EngineOilPressureLowWarn 0;
BA_ "GenSigSendType" SG_ 1072 DriverSeatBeltSwitch 0;
BA_ "GenSigSendType" SG_ 1072 ECOModeSWSts 0;
BA_ "GenSigSendType" SG_ 1072 BatteryVoltage 0;
BA_ "GenSigSendType" SG_ 1072 DisplayVehicleSpeed 0;
BA_ "GenSigSendType" SG_ 1072 ICM_1_HandBrakeSystemSts 0;
BA_ "GenSigSendType" SG_ 1275 DCM_1_PwrDoorErr 0;
BA_ "GenSigSendType" SG_ 1275 DCM_1_RHRStallSts 0;
BA_ "GenSigSendType" SG_ 1275 DCM_1_LHRStallSts 0;
BA_ "GenSigSendType" SG_ 1275 DCM_1_PassStallSts 0;
BA_ "GenSigSendType" SG_ 1275 DCM_1_DrvrStallSts 0;
BA_ "GenSigStartValue" SG_ 1275 DCM_1_DrvrStallSts 1;
BA_ "GenSigSendType" SG_ 1306 SetTemperature_R_F 1;
BA_ "GenSigStartValue" SG_ 1306 SetTemperature_R_F 17;
BA_ "GenSigSendType" SG_ 1306 SetTemperature_L_F 1;
BA_ "GenSigStartValue" SG_ 1306 SetTemperature_L_F 17;
BA_ "GenSigSendType" SG_ 1306 SelfTestResult 1;
BA_ "GenSigSendType" SG_ 1306 ZoneSelectionDisplaySts 1;
BA_ "GenSigSendType" SG_ 1306 CirculationModeDisplaySts 1;
BA_ "GenSigStartValue" SG_ 1306 CirculationModeDisplaySts 1;
BA_ "GenSigSendType" SG_ 1306 SetTemperature_R_C 1;
BA_ "GenSigStartValue" SG_ 1306 SetTemperature_R_C 17;
BA_ "GenSigSendType" SG_ 1306 SetTemperature_L_C 1;
BA_ "GenSigStartValue" SG_ 1306 SetTemperature_L_C 17;
BA_ "GenSigSendType" SG_ 1306 BlowDelayOffSts 0;
BA_ "GenSigSendType" SG_ 1306 BlowAdvanceOnSts 0;
BA_ "GenSigSendType" SG_ 1306 DisplayActive 1;
BA_ "GenSigSendType" SG_ 1306 SelfTestActive 1;
BA_ "GenSigSendType" SG_ 1306 PM2_5Sts 0;
BA_ "GenSigSendType" SG_ 1306 WorkingSts 1;
BA_ "GenSigSendType" SG_ 1306 ModeAdjustDisplaySts 1;
BA_ "GenSigStartValue" SG_ 1306 ModeAdjustDisplaySts 5;
BA_ "GenSigSendType" SG_ 1306 FrontDeforest_MaxDisplaySts 0;
BA_ "GenSigSendType" SG_ 1306 ACRequestDisplaySts 1;
BA_ "GenSigSendType" SG_ 1306 AutoDisplaySts 1;
BA_ "GenSigSendType" SG_ 1306 AC_MaxSts 1;
BA_ "GenSigSendType" SG_ 1306 TemperatureUnit 1;
BA_ "GenSigSendType" SG_ 1306 ExternalTemperatureFailSts 0;
BA_ "GenSigSendType" SG_ 1306 ExternalTemperature_C 0;
BA_ "GenSigStartValue" SG_ 1306 ExternalTemperature_C 254;
BA_ "GenSigSendType" SG_ 1306 ExternalTemperature_F 0;
BA_ "GenSigStartValue" SG_ 1306 ExternalTemperature_F 254;
BA_ "GenSigSendType" SG_ 1226 CIR_1_ClsdWarn 0;
BA_ "GenSigSendType" SG_ 1226 CIR_1_FltySts 0;
BA_ "GenSigSendType" SG_ 1226 CIR_1_EnaSts 0;
BA_ "GenSigSendType" SG_ 1419 BDM_VINcode_17 0;
BA_ "GenSigSendType" SG_ 1419 BDM_VINcode_16 0;
BA_ "GenSigSendType" SG_ 1419 BDM_VINcode_15 0;
BA_ "GenSigSendType" SG_ 1419 BDM_VINcode_14 0;
BA_ "GenSigSendType" SG_ 1419 BDM_VINcode_13 0;
BA_ "GenSigSendType" SG_ 1419 BDM_VINcode_12 0;
BA_ "GenSigSendType" SG_ 1419 BDM_VINcode_11 0;
BA_ "GenSigSendType" SG_ 1419 BDM_VINcode_10 0;
BA_ "GenSigSendType" SG_ 1481 BDM_28_EVTotOdoBkp 0;
BA_ "GenSigSendType" SG_ 1224 BDM_21_CRC 0;
BA_ "GenSigSendType" SG_ 1224 BDM_21_MessageCounter 0;
BA_ "GenSigSendType" SG_ 1224 BDM_21_TotLampFailSts 0;
BA_ "GenSigSendType" SG_ 1224 BCM_RRPLMfailsts 0;
BA_ "GenSigSendType" SG_ 1224 BCM_RRFLMfailsts 0;
BA_ "GenSigSendType" SG_ 1224 BCM_RLPLMfailsts 0;
BA_ "GenSigSendType" SG_ 1224 BCM_RLFLMfailsts 0;
BA_ "GenSigSendType" SG_ 1224 BCM_RHMfailsts 0;
BA_ "GenSigSendType" SG_ 1224 BCM_LHMfailsts 0;
BA_ "GenSigSendType" SG_ 1224 ReFogLiFaildSts 0;
BA_ "GenSigSendType" SG_ 1224 ReversinglampFaultSts 0;
BA_ "GenSigSendType" SG_ 1224 BrakelampFaultSts 0;
BA_ "GenSigSendType" SG_ 1224 FrntFogFaildSts 0;
BA_ "GenSigSendType" SG_ 1224 DRLFaildSts 0;
BA_ "GenSigSendType" SG_ 1224 BDM_21_RHTurnlightSts 0;
BA_ "GenSigSendType" SG_ 1224 BDM_21_LHTurnlightSts 0;
BA_ "GenSigSendType" SG_ 1224 ParkLiFaildSts 0;
BA_ "GenSigSendType" SG_ 1224 LoBeamFaildSts 0;
BA_ "GenSigSendType" SG_ 1224 HiBeamFaildSts 0;
BA_ "GenSigSendType" SG_ 746 TotODOMtrBkp 0;
BA_ "GenSigSendType" SG_ 746 BDM_OTAPwrOnReqFb 0;
BA_ "GenSigSendType" SG_ 746 BDM_OTAPwrDwnReqFb 0;
BA_ "GenSigSendType" SG_ 746 BDM_OTAModStsFb 0;
BA_ "GenSigSendType" SG_ 746 LbaLimits 0;
BA_ "GenSigSendType" SG_ 746 SlaveVehMod 0;
BA_ "GenSigSendType" SG_ 746 VehPwrMod 0;
BA_ "GenSigSendType" SG_ 1008 BCM_17_CRC 0;
BA_ "GenSigSendType" SG_ 1008 BCM_17_MessageCounter 0;
BA_ "GenSigSendType" SG_ 901 CTP_SetACRequest 0;
BA_ "GenSigSendType" SG_ 901 BCM_15_ChrgFillerAjar 0;
BA_ "GenSigSendType" SG_ 901 CTP_VolStepValForDVD 0;
BA_ "GenSigSendType" SG_ 901 CTP_VolPlusMinusForDVDSts 0;
BA_ "GenSigSendType" SG_ 901 CTP_HomeKeyForIHUSts 0;
BA_ "GenSigSendType" SG_ 901 CTP_PowerKeyForIHUSts 0;
BA_ "GenSigSendType" SG_ 901 CTP_TrackMod 0;
BA_ "GenSigSendType" SG_ 901 CTP_DriveModeSet 0;
BA_ "GenSigSendType" SG_ 901 CTP_NavKeyForIHUSts 0;
BA_ "GenSigSendType" SG_ 901 CTPKeyVoiceRemindReq 0;
BA_ "GenSigSendType" SG_ 901 IHUSetSwitch 0;
BA_ "GenSigSendType" SG_ 901 AVMSwitch 0;
BA_ "GenSigSendType" SG_ 1315 BCM_16_RHRTirePressure 0;
BA_ "GenSigSendType" SG_ 1315 BCM_16_LHRTirePressure 0;
BA_ "GenSigSendType" SG_ 1315 BCM_16_RHFTirePressure 0;
BA_ "GenSigSendType" SG_ 1315 BCM_16_LHFTirePressure 0;
BA_ "GenSigSendType" SG_ 1315 TirePositionWarning_RHRTire 0;
BA_ "GenSigSendType" SG_ 1315 TirePositionWarning_LHRTire 0;
BA_ "GenSigSendType" SG_ 1315 TirePositionWarning_RHFTire 0;
BA_ "GenSigSendType" SG_ 1315 TirePositionWarning_LHFTire 0;
BA_ "GenSigSendType" SG_ 1315 TirePressureWarningLampSts 0;
BA_ "GenSigSendType" SG_ 1315 TirePressureSystemFailSts 0;
BA_ "GenSigSendType" SG_ 1315 BCM_16_CRC 0;
BA_ "GenSigSendType" SG_ 1315 BCM_16_MessageCounter 0;
BA_ "GenSigSendType" SG_ 1063 ChrgPortCover_Sts 0;
BA_ "GenSigSendType" SG_ 1063 TheaterDimmingColorFeedback_64 0;
BA_ "GenSigStartValue" SG_ 1063 TheaterDimmingColorFeedback_64 2;
BA_ "GenSigSendType" SG_ 1063 Rainfall 0;
BA_ "GenSigSendType" SG_ 1063 HUDBriUnit 0;
BA_ "GenSigSendType" SG_ 1063 HUDBriRawVal 0;
BA_ "GenSigStartValue" SG_ 1063 HUDBriRawVal 127;
BA_ "GenSigSendType" SG_ 1063 Wpr_FailSts 0;
BA_ "GenSigSendType" SG_ 1063 Lbatip 0;
BA_ "GenSigStartValue" SG_ 1520 BCM_10_Signal1 1;
BA_ "GenSigSendType" SG_ 1077 RvsExtMirrFbSts 0;
BA_ "GenSigSendType" SG_ 1077 SRF_Hall2SensorError 0;
BA_ "GenSigSendType" SG_ 1077 SRF_Hall1SensorError 0;
BA_ "GenSigSendType" SG_ 1077 SRF_SunroofOverVolt 0;
BA_ "GenSigSendType" SG_ 1077 SRF_SunroofUnderVolt 0;
BA_ "GenSigSendType" SG_ 1077 SRF_LINCommunicationERROR 0;
BA_ "GenSigSendType" SG_ 1077 SRF_SwitchError 0;
BA_ "GenSigSendType" SG_ 1077 SRF_OverHeatProtect 0;
BA_ "GenSigSendType" SG_ 1077 SRF_MotorRelayError 0;
BA_ "GenSigSendType" SG_ 1077 AssociatedWithDriverModeFeedback 0;
BA_ "GenSigSendType" SG_ 1077 TheaterDimmingBrightnessFeedback 0;
BA_ "GenSigStartValue" SG_ 1077 TheaterDimmingBrightnessFeedback 2;
BA_ "GenSigSendType" SG_ 1077 TheaterDimmingColorFeedback 0;
BA_ "GenSigStartValue" SG_ 1077 TheaterDimmingColorFeedback 5;
BA_ "GenSigSendType" SG_ 1077 SRF_Sunshade_OperateSts 0;
BA_ "GenSigSendType" SG_ 1077 RRWindowSts 0;
BA_ "GenSigSendType" SG_ 1077 RLWindowSts 0;
BA_ "GenSigSendType" SG_ 1077 WindowInhibitSts 0;
BA_ "GenSigSendType" SG_ 1077 FRWindow_Sts 0;
BA_ "GenSigSendType" SG_ 1077 FLWindow_Sts 0;
BA_ "GenSigSendType" SG_ 1077 Window_OperateSts 0;
BA_ "GenSigSendType" SG_ 1077 Reserved_SRF_Error 0;
BA_ "GenSigSendType" SG_ 1077 SRF_InitStatus 0;
BA_ "GenSigSendType" SG_ 1077 AssociatedWithMusicModeFeedback 0;
BA_ "GenSigSendType" SG_ 1077 TheaterDimmingStatusFeedback 0;
BA_ "GenSigStartValue" SG_ 1077 TheaterDimmingStatusFeedback 1;
BA_ "GenSigSendType" SG_ 1077 SRF_PositionSts 0;
BA_ "GenSigSendType" SG_ 1077 SRF_OperateSts 0;
BA_ "GenSigSendType" SG_ 1077 TrailerConnectSts 0;
BA_ "GenSigSendType" SG_ 1307 RHRTirePressure 0;
BA_ "GenSigSendType" SG_ 1307 LHRTirePressure 0;
BA_ "GenSigSendType" SG_ 1307 RHFTirePressure 0;
BA_ "GenSigSendType" SG_ 1307 LHFTirePressure 0;
BA_ "GenSigSendType" SG_ 1307 TireTemperature 0;
BA_ "GenSigSendType" SG_ 1307 BCM_5_EnaSts 0;
BA_ "GenSigSendType" SG_ 1307 BCM_5_clsdwarn 0;
BA_ "GenSigSendType" SG_ 1307 TirePosition 0;
BA_ "GenSigSendType" SG_ 1307 TirePositionWarning_RHRTire 0;
BA_ "GenSigSendType" SG_ 1307 TirePositionWarning_LHRTire 0;
BA_ "GenSigSendType" SG_ 1307 TirePositionWarning_RHFTire 0;
BA_ "GenSigSendType" SG_ 1307 TirePositionWarning_LHFTire 0;
BA_ "GenSigSendType" SG_ 1307 TirePressureWarningLampSts 0;
BA_ "GenSigSendType" SG_ 1307 TirePressureSystemFailSts 0;
BA_ "GenSigSendType" SG_ 914 DRLModeSts 0;
BA_ "GenSigStartValue" SG_ 914 DRLModeSts 1;
BA_ "GenSigSendType" SG_ 914 HeadlampDelayLightSts 0;
BA_ "GenSigStartValue" SG_ 914 HeadlampDelayLightSts 1;
BA_ "GenSigSendType" SG_ 914 AutolockSts 0;
BA_ "GenSigSendType" SG_ 914 AutoFoldSts 0;
BA_ "GenSigSendType" SG_ 914 HeadlampHeightFeedbackSts 0;
BA_ "GenSigSendType" SG_ 914 RemoteLockFeedbackSts 0;
BA_ "GenSigSendType" SG_ 914 BCM_4_DriverDoorLockSts 0;
BA_ "GenSigStartValue" SG_ 914 BCM_4_DriverDoorLockSts 1;
BA_ "GenSigSendType" SG_ 914 DrvrDoorUnlckOnlySts 0;
BA_ "GenSigSendType" SG_ 914 FGHeat_Req_CmdFeedback 0;
BA_ "GenSigSendType" SG_ 914 RearFoglightFaultSts 0;
BA_ "GenSigSendType" SG_ 914 BCM_4_ChildSafetySts 0;
BA_ "GenSigSendType" SG_ 914 WiperSensitivitySWSts 0;
BA_ "GenSigSendType" SG_ 914 RainSensorFailSts 0;
BA_ "GenSigSendType" SG_ 914 ReversinglampFaultSts 0;
BA_ "GenSigSendType" SG_ 914 BCM_4_FrontFogLightSts 0;
BA_ "GenSigSendType" SG_ 914 BrakelampFaultSts 0;
BA_ "GenSigSendType" SG_ 914 BCM_4_ReverseGearSts 0;
BA_ "GenSigSendType" SG_ 914 BCM_4_RearFogLightSts 0;
BA_ "GenSigSendType" SG_ 914 BCM_4_TrunkSts 0;
BA_ "GenSigSendType" SG_ 914 BCM_4_LHRdoorSts 0;
BA_ "GenSigSendType" SG_ 914 BCM_4_RHRDoorSts 0;
BA_ "GenSigSendType" SG_ 914 BCM_4_HoodSts 0;
BA_ "GenSigSendType" SG_ 914 BCM_4_PsngrDoorSts 0;
BA_ "GenSigSendType" SG_ 914 BCM_4_DriverDoorSts 0;
BA_ "GenSigSendType" SG_ 914 FollowMeTimeSts 0;
BA_ "GenSigSendType" SG_ 914 RVSMode 0;
BA_ "GenSigSendType" SG_ 914 BCM_4_DirectionIndLeft 0;
BA_ "GenSigSendType" SG_ 914 BCM_4_DirectionIndRight 0;
BA_ "GenSigSendType" SG_ 914 BCM_4_DRLSts 0;
BA_ "GenSigSendType" SG_ 914 BCM_4_HighBeamSts 0;
BA_ "GenSigSendType" SG_ 914 BCM_4_ParkLightSts 0;
BA_ "GenSigSendType" SG_ 914 BCM_4_LHTurnlightSts 0;
BA_ "GenSigSendType" SG_ 914 BCM_4_RHTurnlightSts 0;
BA_ "GenSigSendType" SG_ 914 BCM_4_KeySts 0;
BA_ "GenSigSendType" SG_ 914 LightDetected 0;
BA_ "GenSigSendType" SG_ 914 KeyRemindWarning 0;
BA_ "GenSigSendType" SG_ 914 ParkLightOnWarning 0;
BA_ "GenSigSendType" SG_ 914 BCM_4_ArmingSts 0;
BA_ "GenSigSendType" SG_ 1059 LDWWorkingSts 0;
BA_ "GenSigSendType" SG_ 1059 LDWWarningSts 0;
BA_ "GenSigSendType" SG_ 1059 LDWLaneDetectionSts 0;
BA_ "GenSigSendType" SG_ 1059 LDWSensitivitySettingFeedback 0;
BA_ "GenSigStartValue" SG_ 1059 LDWSensitivitySettingFeedback 2;
BA_ "GenSigSendType" SG_ 1059 LDWSwitchStsFeedback 0;
BA_ "GenSigStartValue" SG_ 1059 LDWSwitchStsFeedback 1;
BA_ "GenSigSendType" SG_ 1088 RadarWorkSts 0;
BA_ "GenSigSendType" SG_ 1088 RadarDetectSts 0;
BA_ "GenSigSendType" SG_ 1088 AudibleBeepRate 0;
BA_ "GenSigSendType" SG_ 1088 LHMFRadarSensorDistance 0;
BA_ "GenSigStartValue" SG_ 1088 LHMFRadarSensorDistance 30;
BA_ "GenSigSendType" SG_ 1088 RHMFRadarSensorDistance 0;
BA_ "GenSigStartValue" SG_ 1088 RHMFRadarSensorDistance 30;
BA_ "GenSigSendType" SG_ 1088 RHFRadarSensorDistance 0;
BA_ "GenSigStartValue" SG_ 1088 RHFRadarSensorDistance 30;
BA_ "GenSigSendType" SG_ 1088 LHFRadarSensorDistance 0;
BA_ "GenSigStartValue" SG_ 1088 LHFRadarSensorDistance 30;
BA_ "GenSigSendType" SG_ 1088 RHRRadarSensorDistance 0;
BA_ "GenSigStartValue" SG_ 1088 RHRRadarSensorDistance 62;
BA_ "GenSigSendType" SG_ 1088 LHMRRadarSensorDistance 0;
BA_ "GenSigStartValue" SG_ 1088 LHMRRadarSensorDistance 62;
BA_ "GenSigSendType" SG_ 1088 RHMRRadarSensorDistance 0;
BA_ "GenSigStartValue" SG_ 1088 RHMRRadarSensorDistance 62;
BA_ "GenSigSendType" SG_ 1088 PDC_GongRR_1 0;
BA_ "GenSigSendType" SG_ 1088 PDC_GongRL_1 0;
BA_ "GenSigSendType" SG_ 1088 PDC_GongFR_1 0;
BA_ "GenSigSendType" SG_ 1088 PDC_GongFL_1 0;
BA_ "GenSigSendType" SG_ 1088 LHRRadarSensorDistance 0;
BA_ "GenSigStartValue" SG_ 1088 LHRRadarSensorDistance 62;
VAL_ 1443 BitBlinking_TCU 0 " No action" 3 " Invalid signal" 2 " 3Hz" 1 " 1Hz" ;
VAL_ 1443 BitStatus_TCU 3 " Invalid" 2 " Reserved" 1 " Reset" 0 " Set" ;
VAL_ 798 TMR_TMRSysFault 1 "Fault" 0 "No fault                                                                  " ;
VAL_ 1230 TMF_MILSts 3 " Not used(Reserved)" 2 " Active" 1 " Not used(Reserved)" 0 " Off" ;
VAL_ 789 TMF_TMFSysFault 1 "Fault" 0 "No Fault                  " ;
VAL_ 1187 RHM_1_DRLFaildSts 1 " Failure" 0 " Normal" ;
VAL_ 1187 RHM_1_RHTurnLiFaildSts 1 " Failure" 0 " Normal" ;
VAL_ 1187 RHM_1_ParkLiFaildSts 1 " Failure" 0 " Normal" ;
VAL_ 1187 RHM_1_LoBeamFaildSts 1 " Failure" 0 " Normal" ;
VAL_ 1187 RHM_1_HiBeamFaildSts 1 " Failure" 0 " Normal" ;
VAL_ 1141 LHSFRadarSensorDistance 125 " Not used" 124 " Not used" 123 " Not used" 122 " Not used" 121 " Not used" 120 " Not used" 119 " Not used" 118 " Not used" 117 " Not used" 116 " Not used" 115 " Not used" 114 " Not used" 113 " Not used" 112 " Not used" 111 " Not used" 110 " Not used" 109 " Not used" 108 " Not used" 107 " Not used" 106 " Not used" 105 " Not used" 104 " Not used" 103 " Not used" 102 " Not used" 101 " Not used" 100 " Not used" 99 " Not used" 98 " Not used" 97 " Not used" 96 " Not used" 95 " Not used" ;
VAL_ 1141 RHSFRadarSensorDistance 125 " Not used" 124 " Not used" 123 " Not used" 122 " Not used" 121 " Not used" 120 " Not used" 119 " Not used" 118 " Not used" 117 " Not used" 116 " Not used" 115 " Not used" 114 " Not used" 113 " Not used" 112 " Not used" 111 " Not used" 110 " Not used" 109 " Not used" 108 " Not used" 107 " Not used" 106 " Not used" 105 " Not used" 104 " Not used" 103 " Not used" 102 " Not used" 101 " Not used" 100 " Not used" 99 " Not used" 98 " Not used" 97 " Not used" 96 " Not used" 95 " Not used" ;
VAL_ 1141 LHSRRadarSensorDistance 125 " Not used" 124 " Not used" 123 " Not used" 122 " Not used" 121 " Not used" 120 " Not used" 119 " Not used" 118 " Not used" 117 " Not used" 116 " Not used" 115 " Not used" 114 " Not used" 113 " Not used" 112 " Not used" 111 " Not used" 110 " Not used" 109 " Not used" 108 " Not used" 107 " Not used" 106 " Not used" 105 " Not used" 104 " Not used" 103 " Not used" 102 " Not used" 101 " Not used" 100 " Not used" 99 " Not used" 98 " Not used" 97 " Not used" 96 " Not used" 95 " Not used" ;
VAL_ 1141 RHSRRadarSensorDistance 125 " Not used" 124 " Not used" 123 " Not used" 122 " Not used" 121 " Not used" 120 " Not used" 119 " Not used" 118 " Not used" 117 " Not used" 116 " Not used" 115 " Not used" 114 " Not used" 113 " Not used" 112 " Not used" 111 " Not used" 110 " Not used" 109 " Not used" 108 " Not used" 107 " Not used" 106 " Not used" 105 " Not used" 104 " Not used" 103 " Not used" 102 " Not used" 101 " Not used" 100 " Not used" 99 " Not used" 98 " Not used" 97 " Not used" 96 " Not used" 95 " Not used" ;
VAL_ 864 MFS_ICM_Right 3 " invalid" 2 " Stuck" 1 " Pressed" 0 " Not action" ;
VAL_ 864 MFS_ICM_Left 3 " invalid" 2 " Stuck" 1 " Pressed" 0 " Not action" ;
VAL_ 864 MFS_ICM_Down 3 " invalid" 2 " Stuck" 1 " Pressed" 0 " Not action" ;
VAL_ 864 MFS_ICM_UP 3 " invalid" 2 " Stuck" 1 " Pressed" 0 " Not action" ;
VAL_ 864 MFS_Menu 3 " invalid" 2 " Stuck" 1 " Pressed" 0 " Not action" ;
VAL_ 945 MFS_ICMFctChg 3 " invalid" 2 "Stuck" 1 "Pressed" 0 " Not action" ;
VAL_ 945 MFS_Start_Pause 3 " invalid" 2 "Stuck" 1 "Pressed" 0 " Not action" ;
VAL_ 945 MFS_Customize 3 " invalid" 2 "Stuck" 1 "Pressed" 0 " Not action" ;
VAL_ 945 MFS_WeChat 3 " invalid" 2 "Stuck" 1 "Pressed" 0 " Not action" ;
VAL_ 945 TJA_ICA_ON_OFF 3 " invalid" 2 "Stuck" 1 "Pressed" 0 " Not action" ;
VAL_ 945 MFS_Mute 3 " invalid" 2 " Stuck" 1 " Pressed" 0 " Not action" ;
VAL_ 945 MFS_VoiceRecognition 3 " invalid" 2 "Stuck" 1 "Pressed" 0 " Not action" ;
VAL_ 945 MFS_PhoneHangUP 3 " invalid" 2 " Stuck" 1 " Pressed" 0 " Not action" ;
VAL_ 945 MFS_PhonePickUP 3 " invalid" 2 " Stuck" 1 " Pressed" 0 " Not action" ;
VAL_ 945 MFS_SeekDown 3 " invalid" 2 "Stuck" 1 "Pressed" 0 " Not action" ;
VAL_ 945 MFS_SeekUp 3 " invalid" 2 "Stuck" 1 "Pressed" 0 " Not action" ;
VAL_ 945 MFS_VolumeDown 3 " invalid" 2 "Stuck" 1 "Pressed" 0 " Not action" ;
VAL_ 945 MFS_VolumeUp 3 " invalid" 2 "Stuck" 1 "Pressed" 0 " Not action" ;
VAL_ 945 MFS_Mode 3 " invalid" 2 " Stuck" 1 " Pressed" 0 " Not action" ;
VAL_ 777 ISGF_ISGFSysFault 1 "Fault" 0 "No Fault                      " ;
VAL_ 933 AWBRequest 1 " Demand" 0 " No demand" ;
VAL_ 933 AEBReq 5 " FCTB" 4 " EBA" 3 " AEB~cyclist" 2 " AEB~VRU" 1 " AEB" 0 " No demand" ;
VAL_ 933 AEBDecCtrlRequest 1 " Demand" 0 " No demand" ;
VAL_ 1018 FCM_FRM_9_RiObjTyp 15 " Reserved" 14 " Reserved" 13 " Reserved" 12 " Reserved" 11 " Reserved" 10 " Reserved" 9 " Reserved" 8 " Reserved" 7 " Reserved" 6 " Bus" 5 " Cyclist" 4 " Pedestrian" 3 " Motorcycle" 2 " Truck" 1 " Car" 0 " No type" ;
VAL_ 1018 FCM_FRM_9_RiObjID 1 " Valid" 0 " Invalid" ;
VAL_ 1018 FCM_FRM_9_LeObjTyp 15 " Reserved" 14 " Reserved" 13 " Reserved" 12 " Reserved" 11 " Reserved" 10 " Reserved" 9 " Reserved" 8 " Reserved" 7 " Reserved" 6 " Bus" 5 " Cyclist" 4 " Pedestrian" 3 " Motorcycle" 2 " Truck" 1 " Car" 0 " No type" ;
VAL_ 1018 FCM_FRM_9_LeObjID 1 " Valid" 0 " Invalid" ;
VAL_ 1005 FCM_FRM_8_FrntFarObjTyp 15 " Reserved" 14 " Reserved" 13 " Reserved" 12 " Reserved" 11 " Reserved" 10 " Reserved" 9 " Reserved" 8 " Reserved" 7 " Reserved" 6 " Bus" 5 " Cyclist" 4 " Pedestrian" 3 " Motorcycle" 2 " Truck" 1 " Car" 0 " No type" ;
VAL_ 1005 FCM_FRM_8_FrntFarObjID 1 " Valid" 0 " Invalid" ;
VAL_ 1005 FCM_FRM_8_ACCObjTyp 15 " Reserved" 14 " Reserved" 13 " Reserved" 12 " Reserved" 11 " Reserved" 10 " Reserved" 9 " Reserved" 8 " Reserved" 7 " Reserved" 6 " Bus" 5 " Cyclist" 4 " Pedestrian" 3 " Motorcycle" 2 " Truck" 1 " Car" 0 " No type" ;
VAL_ 1005 FCM_FRM_8_ACCObjID 1 " Valid" 0 " Invalid" ;
VAL_ 990 FCM_7_NeborRiLineTyp 3 " Type_Dashed_Line" 2 " Type_Solid_Line" 1 " Type_Unknown" 0 " No display" ;
VAL_ 990 FCM_7_NeborRiLineColor 3 " Color_Yellow" 2 " Color_White" 1 " Color_Unknown" 0 " No display" ;
VAL_ 990 FCM_7_NeborRiLineID 1 " Valid" 0 " Invalid" ;
VAL_ 990 FCM_7_NeborLeLineTyp 3 " Type_Dashed_Line" 2 " Type_Solid_Line" 1 " Type_Unknown" 0 " No display" ;
VAL_ 990 FCM_7_NeborLeLineColor 3 " Color_Yellow" 2 " Color_White" 1 " Color_Unknown" 0 " No display" ;
VAL_ 990 FCM_7_NeborLeLineID 1 " Valid" 0 " Invalid" ;
VAL_ 988 FCM_6_EgoRiLineTyp 3 " Type_Dashed_Line" 2 " Type_Solid_Line" 1 " Type_Unknown" 0 " No display" ;
VAL_ 988 FCM_6_EgoRiLineColor 3 " Color_Yellow" 2 " Color_White" 1 " Color_Unknown" 0 " No display" ;
VAL_ 988 FCM_6_EgoRiLineID 1 " Valid" 0 " Invalid" ;
VAL_ 988 FCM_6_EgoLeLineTyp 3 " Type_Dashed_Line" 2 " Type_Solid_Line" 1 " Type_Unknown" 0 " No display" ;
VAL_ 988 FCM_6_EgoLeLineColor 3 " Color_Yellow" 2 " Color_White" 1 " Color_Unknown" 0 " No display" ;
VAL_ 988 FCM_6_EgoLeLineID 1 " Valid" 0 " Invalid" ;
VAL_ 1241 FuelTankLidSystemFailureSts 1 " Failure" 0 " No failure" ;
VAL_ 1241 FuelTankPressureConditionReached 3 "Reserved" 2 "Ready to refuel" 1 "Wait to refuel" 0 "Not Active" ;
VAL_ 1232 Energy_Flow_Sts 3 " EnFlow Discharge" 2 " EnFlow EngCharge" 1 " EnFlow RegCharge" 0 " EnFlow OFF" ;
VAL_ 1232 Battery_Sts 2 " Batt_Charge" 1 " Batt_Boost" 0 " Batt_Idle" ;
VAL_ 1232 Battery_Temp_Sts 2 " Batt_Relay Open" 1 " Batt_Over Hot" 0 " Batt_Normal" ;
VAL_ 1146 AllWarningInfo 7 " Reserved" 6 " Reserved" 5 " Reserved" 4 " Please check the position of the gear shift" 3 " Third grade failure of gear shift mechanism(Reserved)" 2 " Second grade failure of gear shift mechanism" 1 " First grade failure of gear shift mechanism" 0 " No error" ;
VAL_ 1054 DCDC_DCDCSysFault 1 "Fault" 0 "No fault                                                                  " ;
VAL_ 1048 DCDC_EnableSts 1 "Enable" 0 "Disable                                                                      " ;
VAL_ 1258 BMSH_BattFaultLampSts 1 "Lamp ON" 0 "Lamp OFF" ;
VAL_ 1258 BMSH_PackThermalRunawayLight 1 "Lamp ON" 0 "Lamp OFF" ;
VAL_ 1450 BMSH_BatteryTempLightSts 3 "Not used" 2 "Low" 1 "High" 0 "OFF" ;
VAL_ 1450 BMSH_LowSOC 3 " Alarm" 2 " Reserved" 1 " Warning" 0 " No Warning" ;
VAL_ 1158 AWDoutserviceDispRq 3 " Reserved" 2 " Permanent out service" 1 " Temporary out service" 0 " Not Active" ;
VAL_ 1095 AFS_FaultSts 1 " Fault" 0 " Not Fault" ;
VAL_ 745 AEBdecAvailable 1 " Available" 0 " Not available" ;
VAL_ 745 AEBdecActive 1 " Active" 0 " Not active" ;
VAL_ 1556 ECUSPEC_AWAKE_ICM 1 " Active" 0 " Inactive" ;
VAL_ 1556 DIAGNOSTIC_AWAKE_ICM 1 " Active" 0 " Inactive" ;
VAL_ 1556 IGNITION_AWAKE_ICM 1 " Active" 0 " Inactive" ;
VAL_ 1556 NETWORK_AWAKE_ICM 1 " Active" 0 " Inactive" ;
VAL_ 1556 ECUSPEC_WAKEUP_ICM 1 " Active" 0 " Inactive" ;
VAL_ 1556 NETWORK_WAKEUP_ICM 1 " Active" 0 " Inactive" ;
VAL_ 1556 RESET_WAKEUP_ICM 1 " Active" 0 " Inactive" ;
VAL_ 1556 IGNITION_WAKEUP_ICM 1 " Active" 0 " Inactive" ;
VAL_ 1556 usrData0_ICM 254 " Not Used" 253 " Not Used" 252 " Not Used" 251 " Not Used" 250 " Not Used" 249 " Not Used" 248 " Not Used" 247 " Not Used" 246 " Not Used" 245 " Not Used" 244 " Not Used" 243 " Not Used" 242 " Not Used" 241 " Not Used" 240 " Not Used" 239 " Not Used" 238 " Not Used" 237 " Not Used" 236 " Not Used" 235 " Not Used" 234 " Not Used" 233 " Not Used" 232 " Not Used" 231 " Not Used" 230 " Not Used" 229 " Not Used" 228 " Not Used" 227 " Not Used" 226 " Not Used" 225 " Not Used" 224 " Not Used" 223 " Not Used" 222 " Not Used" 221 " Not Used" 220 " Not Used" 219 " Not Used" 218 " Not Used" 217 " Not Used" 216 " Not Used" 215 " Not Used" 214 " Not Used" 213 " Not Used" 212 " Not Used" 211 " Not Used" 210 " Not Used" 209 " Not Used" 208 " Not Used" 207 " Not Used" 206 " Not Used" 205 " Not Used" 204 " Not Used" 203 " Not Used" 202 " Not Used" 201 " Not Used" 200 " Not Used" 199 " Not Used" 198 " Not Used" 197 " Not Used" 196 " Not Used" 195 " Not Used" 194 " Not Used" 193 " Not Used" 192 " Not Used" 191 " Not Used" 190 " Not Used" 189 " Not Used" 188 " Not Used" 187 " Not Used" 186 " Not Used" 185 " Not Used" 184 " Not Used" 183 " Not Used" 182 " Not Used" 181 " Not Used" 180 " Not Used" 179 " Not Used" 178 " Not Used" 177 " Not Used" 176 " Not Used" 175 " Not Used" 174 " Not Used" 173 " Not Used" 172 " Not Used" 171 " Not Used" 170 " Not Used" 169 " Not Used" 168 " Not Used" 167 " Not Used" 166 " Not Used" 165 " Not Used" 164 " Not Used" 163 " Not Used" 162 " Not Used" 161 " Not Used" 160 " Not Used" 159 " Not Used" 158 " Not Used" 157 " Not Used" 156 " Not Used" 155 " Not Used" 154 " Not Used" 153 " Not Used" 152 " Not Used" 151 " Not Used" 150 " Not Used" 149 " Not Used" 148 " Not Used" 147 " Not Used" 146 " Not Used" 145 " Not Used" 144 " Not Used" 143 " Not Used" 142 " Not Used" 141 " Not Used" 140 " Not Used" 139 " Not Used" 138 " Not Used" 137 " Not Used" 136 " Not Used" 135 " Not Used" 134 " Not Used" 133 " Not Used" 132 " Not Used" 131 " Not Used" 130 " Not Used" 129 " Not Used" 128 " Not Used" 127 " Not Used" 126 " Not Used" 125 " Not Used" 124 " Not Used" 123 " Not Used" 122 " Not Used" 121 " Not Used" 120 " Not Used" 119 " Not Used" 118 " Not Used" 117 " Not Used" 116 " Not Used" 115 " Not Used" 114 " Not Used" 113 " Not Used" 112 " Not Used" 111 " Not Used" 110 " Not Used" 109 " Not Used" 108 " Not Used" 107 " Not Used" 106 " Not Used" 105 " Not Used" 104 " Not Used" 103 " Not Used" 102 " Not Used" 101 " Not Used" 100 " Not Used" 99 " Not Used" 98 " Not Used" 97 " Not Used" 96 " Not Used" 95 " Not Used" 94 " Not Used" 93 " Not Used" 92 " Not Used" 91 " Not Used" 90 " Not Used" 89 " Not Used" 88 " Not Used" 87 " Not Used" 86 " Not Used" 85 " Not Used" 84 " Not Used" 83 " Not Used" 82 " Not Used" 81 " Not Used" 80 " Not Used" 79 " Not Used" 78 " Not Used" 77 " Not Used" 76 " Not Used" 75 " Not Used" 74 " Not Used" 73 " Not Used" 72 " Not Used" 71 " Not Used" 70 " Not Used" 69 " Not Used" 68 " Not Used" 67 " Not Used" 66 " Not Used" 65 " Not Used" 64 " Not Used" 63 " Not Used" 62 " Not Used" 61 " Not Used" 60 " Not Used" 59 " Not Used" 58 " Not Used" 57 " Not Used" 56 " Not Used" 55 " Not Used" 54 " Not Used" 53 " Not Used" 52 " Not Used" 51 " Not Used" 50 " Not Used" 49 " Not Used" 48 " Not Used" 47 " Not Used" 46 " Not Used" 45 " Not Used" 44 " Not Used" 43 " Not Used" 42 " Not Used" 41 " Not Used" 40 " Not Used" 39 " Not Used" 38 " Not Used" 37 " Not Used" 36 " Not Used" 35 " Not Used" 34 " Not Used" 33 " Not Used" 32 " Not Used" 31 " Not Used" 30 " Not Used" 29 " Not Used" 28 " Not Used" 27 " Not Used" 26 " Not Used" 25 " Not Used" 24 " Not Used" 23 " Not Used" 22 " Not Used" 21 " Not Used" 20 " Not Used" 19 " Not Used" 18 " Not Used" 17 " Not Used" 16 " Not Used" 15 " Not Used" 14 " Not Used" 13 " Not Used" 12 " Not Used" 11 " Not Used" 10 " Not Used" 9 " Not Used" 8 " Not Used" 7 " Not Used" 6 " Not Used" 5 " Not Used" 4 " Not Used" 3 " Not Used" 2 " Not Used" 1 " Not Used" 255 " User data not used" 0 " User data for current vehicle" ;
VAL_ 1556 RMR_ICM_CBV 1 " Active" 0 " Inactive" ;
VAL_ 1090 SCU_1_LuggageModFlagSts 3 " Opening" 2 " Open" 1 " Closing" 0 " Close" ;
VAL_ 1090 SCU_1_JourneyModFlagSts 3 " Opening" 2 " Open" 1 " Closing" 0 " Close" ;
VAL_ 1090 SCU_1_SmartSpaceWarn 1 " Request" 0 " Not active" ;
VAL_ 1090 SCU_1_ModCheckFb 3 " Reserved" 2 " Permit" 1 " Inhibit" 0 " Not active" ;
VAL_ 1090 SCU_1_BedModFlagSts 3 " Opening" 2 " Open" 1 " Closing" 0 " Close" ;
VAL_ 1090 SCU_1_FRSeatVentilationFbSts 3 " Seat Ventilation Level3" 2 " Seat Ventilation Level2" 1 " Seat Ventilation Level1" 0 " OFF" ;
VAL_ 1090 SCU_1_FLSeatVentilationFbSts 3 " Seat Ventilation Level3" 2 " Seat Ventilation Level2" 1 " Seat Ventilation Level1" 0 " OFF" ;
VAL_ 1090 Seat_ExtMirror_PositionInfo 31 " Not used" 30 " Not used" 29 " Not used" 28 " Not used" 27 " Not used" 26 " Not used" 25 " Not used" 24 " Not used" 23 " Not used" 22 " Not used" 21 " Not used" 20 " Not used" 19 " Not used" 18 " Not used" 17 " Not used" 16 " error" 15 " seat_ExtMirror_Pos2_Recall_ID5" 14 " seat_ExtMirror_Pos1_Recall_ID5" 13 " seat_ExtMirror_Pos0_Recall_ID5" 12 " seat_ExtMirror_Pos2_Recall_ID4" 11 " seat_ExtMirror_Pos1_Recall_ID4" 10 " seat_ExtMirror_Pos0_Recall_ID4" 9 " seat_ExtMirror_Pos2_Recall_ID3" 8 " seat_ExtMirror_Pos1_Recall_ID3" 7 " seat_ExtMirror_Pos0_Recall_ID3" 6 " seat_ExtMirror_Pos2_Recall_ID2" 5 " seat_ExtMirror_Pos1_Recall_ID2" 4 " seat_ExtMirror_Pos0_Recall_ID2" 3 " seat_ExtMirror_Pos2_Recall_ID1" 2 " seat_ExtMirror_Pos1_Recall_ID1" 1 " seat_ExtMirror_Pos0_Recall_ID1" 0 " Not active" ;
VAL_ 1090 SCURelateKeyOrFaceIDFeedbackSts 1 " Relate" 0 " Not Relate" ;
VAL_ 1090 Seat_ExtMirror_MemorySts 3 " Not Used" 2 " Failure" 1 " Success" 0 " Not Active" ;
VAL_ 1090 SCU_1_FRSeatHeatFbSts 3 " Seat heating Level3" 2 " Seat heating Level2" 1 " Seat heating Level1" 0 " OFF" ;
VAL_ 1090 SCU_1_FLSeatHeatFbSts 3 " Seat heating Level3" 2 " Seat heating Level2" 1 " Seat heating Level1" 0 " OFF" ;
VAL_ 1090 ReverseExtMirrorFeedbackSts 3 " Both sides" 2 " Only left side" 1 " Only right side" 0 " OFF" ;
VAL_ 1090 EasyEntryFeedbackSts 1 " ON" 0 " OFF" ;
VAL_ 1090 Seat_ExtMirror_MemoryReq 1 " Request" 0 " No Request" ;
VAL_ 1090 Seat_ExtMirror_MemoryEnable 1 " Enable" 0 " Disable" ;
VAL_ 1090 MemoryKeySts 1 " Active" 0 " Not active" ;
VAL_ 1078 PLG_OperateSts 7 " Not used" 6 " Not used" 5 " Not used" 4 " Closing" 3 " Opening" 2 " Close" 1 " Open" 0 " Stop" ;
VAL_ 1152 RemoteStartSts 2 " Remote start mode" 1 " Normal start mode" 0 " No start" ;
VAL_ 1152 SmartSystemWarning4_3 1 " ACC switching OFF while Gear box not in P position" 0 " Normal" ;
VAL_ 1152 SmartSystemWarning2_0 1 " Engine start operation attempted when identifier has not been detected in the vehicle" 0 " Normal" ;
VAL_ 1152 SmartSystemWarning2_2 1 " Identifier is out of vehicle range when vehicle starts running" 0 " Normal" ;
VAL_ 1152 SmartSystemWarning1_0 1 " Driver Door opening while ACC is ON and IG is OFF" 0 " Normal" ;
VAL_ 1152 SmartSystemWarning1_1 1 " Identifier is out of vehicle (detection performed on driver door closing), in P range when IG = ON or ACC = ON" 0 " Normal" ;
VAL_ 1152 SmartSystemWarning1_3 1 " Lock (RKE or smart) performed while Identifier in the vehicle" 0 " Normal" ;
VAL_ 1152 SmartSystemWarning3_1 1 " Identifier low battery detected" 0 " Normal" ;
VAL_ 1152 SmartSystemWarning3_2 1 " Engine start not possible if gear box not in P or N position" 0 " Normal" ;
VAL_ 1152 SmartSystemWarning4_2 1 " Engine start attempted without pressing clutch/brake pedal" 0 " Normal " ;
VAL_ 1219 PAS_1_DriverDoorSIllSts 1 "  Active" 0 " Not Active" ;
VAL_ 1025 ESCLNotLocked 3 "Invalid" 2 "Reserved" 1 "Active" 0 "Not active" ;
VAL_ 1025 ESCLUnlockJamming 3 "Invalid" 2 "Reserved" 1 "Active" 0 "Not active" ;
VAL_ 1025 ESCLFunctionFailure 3 "Invalid" 2 "Reserved" 1 "Active" 0 "Not active" ;
VAL_ 1025 ESCLCriticalFailure 3 "Invalid" 2 "Reserved" 1 "Active" 0 "Not active" ;
VAL_ 533 ICM_8_FrntRadarSwt 1 " Active" 0 " Not Active" ;
VAL_ 533 ICM_ESPSwitchCmd 1 " Active" 0 " Not Active" ;
VAL_ 533 ICM_ISS_Switch 1 " Active" 0 " Not Active" ;
VAL_ 533 SetICMAlarm 63 " Reserved" 62 " Reserved" 61 " Reserved" 60 " Reserved" 59 " Reserved" 58 " Reserved" 57 " Reserved" 56 " Reserved" 55 " Reserved" 54 " Reserved" 53 " Reserved" 52 " Reserved" 51 " Reserved" 50 " Reserved" 49 " Reserved" 48 " Reserved" 41 " Reserved" 40 " Reserved" 39 " Reserved" 38 " Reserved" 37 " Reserved" 36 " Reserved" 35 " Reserved" 34 " Reserved" 33 " Reserved" 32 " Reserved" 31 " Reserved" 30 " Reserved" 29 " Reserved" 28 " Reserved" 27 " Reserved" 26 " Reserved" 25 " Reserved" 24 " Reserved" 23 " Reserved" 22 " Reserved" 21 " Reserved" 20 "CHIME OFF" 19 "BSD_L+R" 18 "BSD_R only" 17 "BSD_L only" 16 "PDC_all" 15 "PDC_FR+RL+RR" 14 "PDC_FL+RL+RR" 13 "PDC_FL+FR+RR" 12 "PDC_FL+FR+RL" 11 "PDC_RL+RR" 10 "PDC_FR+RR" 9 "PDC_FR+RL" 8 " PDC_FL+RR" 7 " PDC_FL+RL" 6 " PDC_FL+FR" 5 " PDC_RR only " 4 " PDC_RL only " 3 " PDC_FR only" 2 " PDC_FL only" 1 " other CHIME" 0 " Not Active" ;
VAL_ 1066 Set_HundECAverHisClearSts 1 " Clear" 0 " Not Clear" ;
VAL_ 1066 TotalOdometer_km_OBDValidData 1 " Not valid" 0 " Valid" ;
VAL_ 1066 TotODOMtrBkpEna 1 "Enable" 0 "Disable" ;
VAL_ 1066 DrivermodeReq 3 " Reserved" 2 " Sport" 1 " Normal" 0 " Eco" ;
VAL_ 647 ICM_DVDAudibleAlarmStyle 3 "Not Used" 2 "Cycle" 1 "Once" 0 "Not active" ;
VAL_ 647 ICM_DVDAudibleAlarm 15 "Reserved" 14 "Reserved" 13 "Reserved" 12 "Reserved" 11 "Key Tone" 10 "Door Open" 9 "ODO" 8 "Turn Tock    " 7 "Turn Tick                                                                  " 6 "Seatbelt" 5 "Safty" 4 "Warning" 3 "Info" 2 "FWC" 1 "PDC" 0 "Not active" ;
VAL_ 647 BrakeFluidWarning 1 " Warning" 0 " Not Warning" ;
VAL_ 647 ACC_Kilometre_Mile 1 " mile" 0 " kilometer" ;
VAL_ 647 DriverSeatBeltSwitchQbit 1 " invalid" 0 " valid" ;
VAL_ 647 ICM_5_DriverSeatBeltSwitch 1 " Unfasten" 0 " Fasten" ;
VAL_ 647 CTP_DriveModeSet 1 " Active" 0 " Not Active                                   " ;
VAL_ 647 ICM_5_AlrmVolCtrl 3 " Not Used" 2 " Down" 1 " UP" 0 " Not active" ;
VAL_ 647 ICM_5_BackLiBriAdjmt 3 " Not Used" 2 " Down" 1 " UP" 0 " Not active" ;
VAL_ 647 AverageFuelConsumption50 510 " Not Used" 509 " Not Used" 508 " Not Used" 507 " Not Used" 506 " Not Used" 505 " Not Used" 504 " Not Used" 503 " Not Used" 502 " Not Used" 501 " Not Used" ;
VAL_ 647 FuelValidData 1 "Not valid" 0 "Valid" ;
VAL_ 647 FuelOutOfRange 1 " Out Of Range" 0 " Fail Not Present " ;
VAL_ 647 FuelShortPower 1 " Short Power" 0 " Fail Not Present " ;
VAL_ 647 FuelShortGround 1 " Short Ground" 0 " Fail Not Present " ;
VAL_ 647 HandBrakeSystemStsValidData 1 "Not valid" 0 "Valid" ;
VAL_ 647 HandBrakeSystemSts 7 "Not Used" 6 "Not Used" 5 "ErrorApplied" 4 "Unknown" 3 "Applying" 2 "Releasing" 1 "Applied" 0 "Released" ;
VAL_ 1107 TimeFormat 3 " Reserved" 2 " Reserved" 1 " 12 hour" 0 " 24hour" ;
VAL_ 1107 FatigureDrivingWarning 1 " Warning" 0 " Not Warning" ;
VAL_ 1107 ICM_BrightnessLevel 15 " Not Used" 14 " Not Used" 13 " Not Used" 12 " Not Used" 11 " Not Used" 10 " Level 10" 9 " Level 9" 8 " Level 8" 7 " Level 7" 6 " Level 6" 5 " Level 5" 4 " Level 4" 3 " Level 3" 2 " Level 2" 1 " Level 1 " 0 " Not Active" ;
VAL_ 1107 MaintainWarning 1 " Warning" 0 " Not Warning" ;
VAL_ 1107 LowFuleWarning 1 " Warning" 0 " Not Warning" ;
VAL_ 1107 FatigureDrivingTime 15 " Reserved" 14 " Reserved" 13 " Reserved" 12 " Reserved" 11 " Reserved" 10 " Reserved" 9 " Reserved" 8 " Reserved" 7 " 4 hours " 6 " 3.5 hours" 5 " 3 hours" 4 " 2.5 hours" 3 " 2 hours" 2 " 1.5 hours" 1 " 1 hour" 0 " Not Active" ;
VAL_ 1106 ICM_2_Ajuststate 1 "DMC(ICM) Ajust" 0 "Adas Ajust     " ;
VAL_ 1106 FrontSeatBeltAlarmLight 1 " Light ON" 0 " Light OFF" ;
VAL_ 1106 ICM_2_OverSpeedValue 42 " 170km/h" 41 " 165km/h" 40 " 160km/h" 39 " 155km/h" 38 " 150km/h" 37 " 145km/h" 36 " 140km/h" 35 " 135km/h" 34 " 80 mph" 33 " 75 mph" 32 " 70 mph" 31 " 65 mph" 30 " 60 mph" 29 " 55 mph" 28 " 50 mph" 27 " 45 mph" 26 " 40 mph" 25 " 35 mph" 24 " 30mph" 23 " 25mph" 22 " 20mph" 21 " 130km/h" 20 " 125km/h" 19 " 120km/h" 18 " 115km/h" 17 " 110km/h" 16 " 105km/h" 15 " 100km/h" 14 " 95km/h" 13 " 90km/h" 12 " 85km/h" 11 " 80km/h" 10 " 75km/h" 9 " 70km/h" 8 " 65km/h" 7 " 60km/h" 6 " 55km/h" 5 " 50km/h" 4 " 45km/h" 3 " 40km/h" 2 " 35km/h" 1 " 30km/h" 0 " Not Active" ;
VAL_ 1106 QDashACCFail 3 " not defined" 2 " irreversible error" 1 " reversible error" 0 " no error" ;
VAL_ 1106 DISFail 1 " error" 0 " no error" ;
VAL_ 1106 ICM_2_LoWshLqdWarn 1 " Warning" 0 " Not Warning" ;
VAL_ 1106 BackLightLevel 15 " Reserved" 14 " Reserved" 13 " Reserved" 12 " Reserved" 11 " Reserved" 10 " Reserved" 9 " Level 10 " 8 " Level 9" 7 " Level 8" 6 " Level 7" 5 " Level 6 " 4 " Level 5" 3 " Level 4" 2 " Level 3" 1 " Level 2" 0 " Level 1" ;
VAL_ 1106 TemperatureUnit_ICM 1 " Fahrenheit(℉)" 0 " Centigrade(℃)" ;
VAL_ 1106 ICM_2_ShdSts 1 " Success" 0 " Fail" ;
VAL_ 1106 AirBagLampFailSts 3 " BLINKING-not used / fault present when lamp blinking function is ON" 2 " ON-Fail present when lamp is switched ON" 1 " OFF-Fail present when lamp is switched OFF" 0 " ON/OFF-No Fail of any kind" ;
VAL_ 1072 EngineCoolantTempertureHighWarn 1 " Active" 0 " Not active" ;
VAL_ 1072 DrvrSeatBltSwtForPPMI 1 " Unfasten" 0 " Fasten" ;
VAL_ 1072 FuelLevelFailSts 1 " Fail Present" 0 " Fail Not Present" ;
VAL_ 1072 EngineOilPressureLowWarn 1 " Active" 0 " Not active" ;
VAL_ 1072 DriverSeatBeltSwitch 1 " Unfasten" 0 " Fasten" ;
VAL_ 1072 ECOModeSWSts 1 " Active" 0 " Not active" ;
VAL_ 1072 ICM_1_HandBrakeSystemSts 7 " Not Used" 6 " Not Used" 5 " ErrorApplied" 4 " Unknown" 3 " Applying" 2 " Releasing" 1 " Applied" 0 " Released" ;
VAL_ 1275 DCM_1_PwrDoorErr 1 " Error" 0 " Normal" ;
VAL_ 1275 DCM_1_RHRStallSts 1 " Stall" 0 " No stall" ;
VAL_ 1275 DCM_1_LHRStallSts 1 " Stall" 0 " No stall" ;
VAL_ 1275 DCM_1_PassStallSts 1 " Stall" 0 " No stall" ;
VAL_ 1275 DCM_1_DrvrStallSts 1 " Stall" 0 " No stall" ;
VAL_ 1306 SelfTestResult 30 "Lost Communication With PEPS" 29 "Frag fan error" 28 "Right anion  error  " 27 "Left anion  error " 26 "PTC  fault(Reserved)" 25 "EAC fault(Reserved)" 24 "External PM2.5  error" 23 "Incar PM2.5  error " 22 "Lost Communication With IPM " 21 "Lost Communication With BCM " 20 "Lost Communication With RRM " 19 "Lost Communication With BSM " 18 "Lost Communication With EMS " 17 "Lost Communication With ICM " 16 "Right mixture motor error" 15 "Left mixture motor error" 14 "Mode motor 2 error" 13 "Mode motor 1 error" 12 "Circulation motor error" 11 "Blower error" 10 "AQM fault" 9 "Frag motor error" 8 "Evaporator temperature sensor errorevaporator" 7 "AQS sensor error" 6 "Humidity sensor error" 5 "Right solar error" 4 "Left solar error" 3 "Frag Lost Communication With CLM" 2 "Left internal temperature error" 1 "External temperature error" 0 "No error,the system operates well" ;
VAL_ 1306 ZoneSelectionDisplaySts 1 " Dual zone mode" 0 " Single zone mode" ;
VAL_ 1306 CirculationModeDisplaySts 1 " Air circulation mode" 0 " Recirculation mode" ;
VAL_ 1306 BlowDelayOffSts 1 " Not DelayOff" 0 " DelayOff" ;
VAL_ 1306 BlowAdvanceOnSts 1 " Not AdvanceOn" 0 " AdvanceOn" ;
VAL_ 1306 DisplayActive 1 " Active" 0 " Not Active" ;
VAL_ 1306 SelfTestActive 1 " Active" 0 " Not Active" ;
VAL_ 1306 PM2_5Sts 1 " Active" 0 " Not Active" ;
VAL_ 1306 WorkingSts 1 " Active" 0 " Not Active" ;
VAL_ 1306 ModeAdjustDisplaySts 7 "?BlowFace ?&?BlowFoot & Defrost" 6 "?BlowFace & Defrost " 5 "?Not?Active " 4 "?Defrost " 3 "?BlowFoot?&?Defrost " 2 "?BlowFoot " 1 "?BlowFace?&?BlowFoot " 0 "?BlowFace " ;
VAL_ 1306 FrontDeforest_MaxDisplaySts 1 " Active" 0 " Not Active" ;
VAL_ 1306 ACRequestDisplaySts 1 " Active" 0 " Not Active" ;
VAL_ 1306 AutoDisplaySts 1 " Auto Active" 0 " Auto Not Active" ;
VAL_ 1306 AC_MaxSts 1 " Active" 0 " Not Active" ;
VAL_ 1306 TemperatureUnit 1 " Fahrenheit(℉)" 0 " Centigrade(℃)" ;
VAL_ 1306 ExternalTemperatureFailSts 1 " Fail Present" 0 " Fail Not Present" ;
VAL_ 1226 CIR_1_ClsdWarn 1 "active" 0 "not active" ;
VAL_ 1226 CIR_1_FltySts 1 "active" 0 "not active" ;
VAL_ 1226 CIR_1_EnaSts 3 "Ignore" 2 "Reserved" 1 "Disable" 0 "Enable" ;
VAL_ 1224 BDM_21_TotLampFailSts 1 " Failure" 0 " Normal" ;
VAL_ 1224 BCM_RRPLMfailsts 1 " Failure" 0 " Normal" ;
VAL_ 1224 BCM_RRFLMfailsts 1 " Failure" 0 " Normal" ;
VAL_ 1224 BCM_RLPLMfailsts 1 " Failure" 0 " Normal" ;
VAL_ 1224 BCM_RLFLMfailsts 1 " Failure" 0 " Normal" ;
VAL_ 1224 BCM_RHMfailsts 1 " Failure" 0 " Normal" ;
VAL_ 1224 BCM_LHMfailsts 1 " Failure" 0 " Normal" ;
VAL_ 1224 ReFogLiFaildSts 1 " Failure" 0 " Normal" ;
VAL_ 1224 ReversinglampFaultSts 1 " Failure" 0 " Normal" ;
VAL_ 1224 BrakelampFaultSts 1 " Failure" 0 " Normal" ;
VAL_ 1224 FrntFogFaildSts 1 " Failure" 0 " Normal" ;
VAL_ 1224 DRLFaildSts 1 " Failure" 0 " Normal" ;
VAL_ 1224 BDM_21_RHTurnlightSts 1 " Failure" 0 " Normal" ;
VAL_ 1224 BDM_21_LHTurnlightSts 1 " Failure" 0 " Normal" ;
VAL_ 1224 ParkLiFaildSts 1 " Failure" 0 " Normal" ;
VAL_ 1224 LoBeamFaildSts 1 " Failure" 0 " Normal" ;
VAL_ 1224 HiBeamFaildSts 1 " Failure" 0 " Normal" ;
VAL_ 746 BDM_OTAPwrOnReqFb 3 " Resrved" 2 " Fail" 1 " Success" 0 " No Command" ;
VAL_ 746 BDM_OTAPwrDwnReqFb 3 " Resrved" 2 " Fail" 1 " Success" 0 " No Command" ;
VAL_ 746 BDM_OTAModStsFb 1 " Active" 0 " InActive" ;
VAL_ 746 LbaLimits 3 " Level3" 2 " Level2" 1 " Level1" 0 " Level0" ;
VAL_ 746 SlaveVehMod 7 "Reserved" 6 "Transport Paused" 5 "Factory Paused " 4 " Crash" 3 " Dyno " 2 " Normal" 1 " Transport" 0 " Factory " ;
VAL_ 746 VehPwrMod 4 " Running" 3 " Crank" 2 " ON " 1 " ACC" 0 " OFF" ;
VAL_ 901 CTP_SetACRequest 3 " Not Used" 2 " Off" 1 " On " 0 " Not Active" ;
VAL_ 901 BCM_15_ChrgFillerAjar 1 " Open" 0 " Close" ;
VAL_ 901 CTP_VolPlusMinusForDVDSts 3 " Not Used" 2 " Plus" 1 " Minus" 0 " Not Active" ;
VAL_ 901 CTP_HomeKeyForIHUSts 3 " Not Used" 2 " Not Used" 1 " Active" 0 " Not active" ;
VAL_ 901 CTP_PowerKeyForIHUSts 3 " Not Used" 2 " Not Used" 1 " Active" 0 " Not active" ;
VAL_ 901 CTP_TrackMod 1 " Active" 0 " Not Active" ;
VAL_ 901 CTP_DriveModeSet 3 " Not Used" 2 " DOWN                                     " 1 " UP " 0 " Not Active                                   " ;
VAL_ 901 CTP_NavKeyForIHUSts 3 " Not Used" 2 " Not Used" 1 " Active" 0 " Not Active" ;
VAL_ 901 CTPKeyVoiceRemindReq 1 " Active" 0 " Not Active" ;
VAL_ 901 IHUSetSwitch 1 " Active" 0 " Not Active" ;
VAL_ 901 AVMSwitch 1 " Active" 0 " Not Active" ;
VAL_ 1315 TirePositionWarning_RHRTire 7 " Not used(Reserved)" 6 " Error Mode" 5 " High Temperature" 4 " High Pressure(Reserved)" 2 " Low Pressure" 1 " Rapid Air Loss(Reserved) " 0 " Normal" ;
VAL_ 1315 TirePositionWarning_LHRTire 7 " Not used(Reserved)" 6 " Error Mode" 5 " High Temperature" 4 " High Pressure(Reserved)" 2 " Low Pressure" 1 " Rapid Air Loss(Reserved)" 0 " Normal" ;
VAL_ 1315 TirePositionWarning_RHFTire 7 " Not used(Reserved)" 6 " Error Mode" 5 " High Temperature" 4 " High Pressure(Reserved)" 2 " Low Pressure" 1 " Rapid Air Loss(Reserved)" 0 " Normal" ;
VAL_ 1315 TirePositionWarning_LHFTire 7 " Not used(Reserved)" 6 " Error Mode" 5 " High Temperature" 4 " High Pressure(Reserved)" 2 " Low Pressure" 1 " Rapid Air Loss(Reserved)" 0 " Normal" ;
VAL_ 1315 TirePressureWarningLampSts 3 " Not used" 2 " Lamp On" 1 " Lamp Flashing(Reserved)" 0 " Lamp Off" ;
VAL_ 1315 TirePressureSystemFailSts 1 " Fail Present" 0 " Fail Not Present" ;
VAL_ 1063 ChrgPortCover_Sts 1 " Open" 0 " Close" ;
VAL_ 1063 TheaterDimmingColorFeedback_64 64 " Number 64" 63 " Number 63" 62 " Number 62" 61 " Number 61" 60 " Number 60" 59 " Number 59" 58 " Number 58" 57 " Number 57" 56 " Number 56" 55 " Number 55" 54 " Number 54" 53 " Number 53" 52 " Number 52" 51 " Number 51" 50 " Number 50" 49 " Number 49" 48 " Number 48" 47 " Number 47" 46 " Number 46" 45 " Number 45" 44 " Number 44" 43 " Number 43" 42 " Number 42" 41 " Number 41" 40 " Number 40" 39 " Number 39" 38 " Number 38" 37 " Number 37" 36 " Number 36" 35 " Number 35" 34 " Number 34" 33 " Number 33" 32 " Number 32" 31 " Number 31" 30 " Number 30" 29 " Number 29" 28 " Number 28" 27 " Number 27" 26 " Number 26" 25 " Number 25" 24 " Number 24" 23 " Number 23" 22 " Number 22" 21 " Number 21" 20 " Number 20" 19 " Number 19" 18 " Number 18" 17 " Number 17" 16 " Number 16" 15 " Number 15" 14 " Number 14" 13 " Number 13" 12 " Number 12" 11 " Number 11" 10 " Number 10" 9 " Number 9" 8 " Number 8" 7 " Number 7" 6 " Number 6" 5 " Number 5" 4 " Number 4" 3 " Number 3" 2 " Number 2" 1 " Number 1" 0 " Not Active" ;
VAL_ 1063 Rainfall 3 "Heavy Rain" 2 "Moderate Rain" 1 "Light Rain" 0 "No Rain" ;
VAL_ 1063 HUDBriUnit 3 " 1000 lux" 2 " 100 lux" 1 " 10 lux" 0 " 1 lux" ;
VAL_ 1063 Wpr_FailSts 1 "failure detected" 0 "no failure " ;
VAL_ 1063 Lbatip 3 " warning 3" 2 " Reserved" 1 " warning 1" 0 " no warning" ;
VAL_ 1520 ICMVehicleType 15 " Reserved" 14 " Reserved" 13 " Reserved" 12 " Reserved" 11 " Reserved" 10 " Reserved" 9 " Reserved" 8 " Reserved" 7 " Reserved" 6 " Reserved" 5 "Configuration6" 4 "Configuration5" 3 "Configuration4" 2 " Configuration3" 1 " Configuration2" 0 " Configuration1" ;
VAL_ 1520 Third_Row_SBR_Buckle_switch 1 "Present" 0 "Not present" ;
VAL_ 1520 Second_Row_SBR_Buckle_switch 1 "Present" 0 "Not present" ;
VAL_ 1520 LKA 1 " Present" 0 " Not Present" ;
VAL_ 1520 EGS 1 "Present" 0 "Not present" ;
VAL_ 1077 RvsExtMirrFbSts 3 " Both Sides" 2 " Only Left Side" 1 " Only Right Side" 0 " OFF" ;
VAL_ 1077 SRF_Hall2SensorError 1 " Error" 0 " Normal" ;
VAL_ 1077 SRF_Hall1SensorError 1 " Error" 0 " Normal" ;
VAL_ 1077 SRF_SunroofOverVolt 1 " OverVoltage" 0 " Normal" ;
VAL_ 1077 SRF_SunroofUnderVolt 1 " UnderVoltage" 0 " Normal" ;
VAL_ 1077 SRF_LINCommunicationERROR 1 " Error" 0 " Normal" ;
VAL_ 1077 SRF_SwitchError 1 " Error" 0 " Normal" ;
VAL_ 1077 SRF_OverHeatProtect 1 " Active" 0 " Not Active" ;
VAL_ 1077 SRF_MotorRelayError 1 " Error" 0 " Normal" ;
VAL_ 1077 AssociatedWithDriverModeFeedback 1 " ON" 0 " OFF" ;
VAL_ 1077 TheaterDimmingBrightnessFeedback 7 " Reserved" 6 " Reserved" 5 " Reserved" 4 " Level 5" 3 " Level 4" 2 " Level 3" 1 " Level 2" 0 " Level 1                  " ;
VAL_ 1077 TheaterDimmingColorFeedback 7 " Reserved" 6 " Purple" 5 " Blue" 4 " Cyan" 3 " Green" 2 " Yellow" 1 " Orange" 0 " Red                   " ;
VAL_ 1077 SRF_Sunshade_OperateSts 7 " Not Used" 6 " Half Open" 5 " Open" 4 " Closing" 3 " Stop" 2 " Opening" 1 " Close" 0 " Startup" ;
VAL_ 1077 RRWindowSts 7 " Reserved" 6 " Opening" 5 " Closing" 4 " Stop" 3 " Open" 2 " Close" 1 " Comfort" 0 " Startup" ;
VAL_ 1077 RLWindowSts 7 " Reserved" 6 " Opening" 5 " Closing" 4 " Stop" 3 " Open" 2 " Close" 1 " Comfort" 0 " Startup" ;
VAL_ 1077 WindowInhibitSts 1 " Inhibit" 0 " Permit" ;
VAL_ 1077 FRWindow_Sts 7 " Reserved" 6 " Opening" 5 " Closing" 4 " Stop" 3 " Open" 2 " Close" 1 " Comfort" 0 " Startup" ;
VAL_ 1077 FLWindow_Sts 7 " Reserved" 6 " Opening" 5 " Closing" 4 " Stop" 3 " Open" 2 " Close" 1 " Comfort" 0 " Startup" ;
VAL_ 1077 Window_OperateSts 3 " Reserved" 2 " Not active" 1 " Active" 0 " Startup" ;
VAL_ 1077 Reserved_SRF_Error 15 " Reserved" 14 " Reserved" 13 " Reserved" 12 " Reserved" 11 " Reserved" 10 " Reserved" 9 " Reserved" 8 " Hall2 Sensor Error" 7 " Hall1 Sensor Error" 6 " Sunroof Over Volt" 5 " Sunroof under volt" 4 " LIN Communication Error" 3 " Switch Error" 2 " OverHeat Protect" 1 " Motor relay Error" 0 " Start up" ;
VAL_ 1077 SRF_InitStatus 1 " Sunroof Init Complete" 0 " Sunroof Init Incomplete" ;
VAL_ 1077 AssociatedWithMusicModeFeedback 1 " ON" 0 " OFF" ;
VAL_ 1077 TheaterDimmingStatusFeedback 1 " ON" 0 " OFF" ;
VAL_ 1077 SRF_PositionSts 15 " Reserved" 14 " Reserved" 13 " Reserved" 12 " Tilt" 11 " 100%" 10 " 90%" 9 " 80%" 8 " 70%" 7 " 60%" 6 " 50%" 5 " 40%" 4 " 30%" 3 " 20%" 2 " 10%" 1 " 0" 0 " Startup" ;
VAL_ 1077 SRF_OperateSts 7 " Comfort open" 6 " Open" 5 " Closing" 4 " Stop" 3 " Opening" 2 " Close" 1 " Tilt" 0 " Startup" ;
VAL_ 1077 TrailerConnectSts 1 " Active" 0 " Not Active" ;
VAL_ 1514 NavigationInformation 1 "Present" 0 "Not present" ;
VAL_ 1514 SecondIntervalMaintainMileage 3 "10000km" 2 "8000km" 1 "5000km" 0 "Not present" ;
VAL_ 1514 OverSpeedWarningFunction 3 " 120km/h(China,3 beeps)" 2 " 120km/h(GSO)" 1 " 30~130km/h" 0 " No" ;
VAL_ 1514 Language 15 " Reserved" 14 " Reserved" 13 " Reserved" 12 " Reserved" 11 " Reserved" 10 " Reserved" 9 " Reserved" 8 " Reserved" 7 " Reserved" 6 " Spanish" 5 " Persian" 4 " Portuguese" 3 " Arabic" 2 " Russian" 1 " English" 0 " Chinese" ;
VAL_ 1514 LDW 1 " Present" 0 " Not Present" ;
VAL_ 1514 EngineFuelType 3 "Flex" 2 "CNG" 1 "Diesel" 0 "Gasoline" ;
VAL_ 1514 Radar 1 " Not display" 0 " Display" ;
VAL_ 1514 FuelConsumptionCorrect 3 "Configuration4" 2 "Configuration3" 1 "Configuration2" 0 "Configuration1" ;
VAL_ 1514 MaintainMileage 1 "International" 0 "China International" ;
VAL_ 1514 FirstMaintain 1 "International" 0 "China International" ;
VAL_ 1505 CGW 1 " Present" 0 " Not Present" ;
VAL_ 1505 TCU4_7DCT_DHT 1 " Present" 0 " Not Present" ;
VAL_ 1505 EIPM_ONCAN 1 " Present" 0 " Not Present" ;
VAL_ 1505 RADAR 1 " Present" 0 " Not Present" ;
VAL_ 1505 SAS 1 " Present" 0 " Not Present" ;
VAL_ 1505 APM 1 " Present" 0 " Not Present" ;
VAL_ 1505 IMMO 3 "BDM integrated IMMO" 2 "PEPS integrated IMMO" 1 "Independent IMMO" 0 "Not Present" ;
VAL_ 1505 ICM 1 " Present" 0 " Not Present" ;
VAL_ 1505 BCM 1 " Present" 0 " Not Present" ;
VAL_ 1505 EMS 1 " Present" 0 " Not Present" ;
VAL_ 1505 EmissionType 1 "National VI" 0 "National V" ;
VAL_ 1505 TCU3_CVT25_CVT18 1 " Present" 0 " Not Present" ;
VAL_ 1505 MFS_LIN 1 " Present" 0 " Not Present" ;
VAL_ 1505 ESCL_CAN 1 " Present" 0 " Not Present" ;
VAL_ 1505 PLG 1 " Present" 0 " Not Present" ;
VAL_ 1505 FRM 1 " Present" 0 " Not Present" ;
VAL_ 1505 FCM 1 " Present" 0 " Not Present" ;
VAL_ 1505 BSD 1 " Present" 0 " Not Present" ;
VAL_ 1505 EPB 1 " Present" 0 " Not Present" ;
VAL_ 1505 AVM 1 " Present" 0 " Not Present" ;
VAL_ 1505 BMS 1 "Present" 0 "Not present" ;
VAL_ 1505 TPMS 1 " Present" 0 " Not Present" ;
VAL_ 1505 RRM 1 "Present" 0 "Not present" ;
VAL_ 1505 PEPS 1 " Present" 0 " Not Present" ;
VAL_ 1505 EPS 1 " Present" 0 " Not Present" ;
VAL_ 1505 CLM 1 " Present" 0 " Not Present" ;
VAL_ 1505 TCU2_6DCT 1 " Present" 0 " Not Present" ;
VAL_ 1505 TCU1_CVT19 1 " Present" 0 " Not Present" ;
VAL_ 1505 ESP 1 " Present" 0 " Not Present" ;
VAL_ 1505 ABS 1 " Present" 0 " Not Present" ;
VAL_ 1505 ABM 1 " Present" 0 " Not Present" ;
VAL_ 1307 BCM_5_EnaSts 1 "Disable" 0 "Enable" ;
VAL_ 1307 BCM_5_clsdwarn 3 "Not used" 2 "not warning" 1 "warning" 0 "not active" ;
VAL_ 1307 TirePosition 3 " RHR" 2 " LHR" 1 " RHF" 0 " LHF" ;
VAL_ 1307 TirePositionWarning_RHRTire 7 " Not used(Reserved)" 6 " Error Mode" 5 " High Temperature" 4 " High Pressure(Reserved)" 2 " Low Pressure" 1 " Rapid Air Loss(Reserved) " 0 " Normal" ;
VAL_ 1307 TirePositionWarning_LHRTire 7 " Not used(Reserved)" 6 " Error Mode" 5 " High Temperature" 4 " High Pressure(Reserved)" 2 " Low Pressure" 1 " Rapid Air Loss(Reserved)" 0 " Normal" ;
VAL_ 1307 TirePositionWarning_RHFTire 7 " Not used(Reserved)" 6 " Error Mode" 5 " High Temperature" 4 " High Pressure(Reserved)" 2 " Low Pressure" 1 " Rapid Air Loss(Reserved)" 0 " Normal" ;
VAL_ 1307 TirePositionWarning_LHFTire 7 " Not used(Reserved)" 6 " Error Mode" 5 " High Temperature" 4 " High Pressure(Reserved)" 2 " Low Pressure" 1 " Rapid Air Loss(Reserved)" 0 " Normal" ;
VAL_ 1307 TirePressureWarningLampSts 3 " Not used" 2 " Lamp On" 1 " Lamp Flashing(Reserved)" 0 " Lamp Off" ;
VAL_ 1307 TirePressureSystemFailSts 1 " Fail Present" 0 " Fail Not Present" ;
VAL_ 914 DRLModeSts 1 " Open DRL mode" 0 " Close DRL mode" ;
VAL_ 914 HeadlampDelayLightSts 1 " Delay mode" 0 " Not Delay mode" ;
VAL_ 914 AutolockSts 1 " Autolock mode" 0 " Not autolock mode" ;
VAL_ 914 AutoFoldSts 1 " Autofold mode" 0 " Not autofold mode" ;
VAL_ 914 HeadlampHeightFeedbackSts 7 " Not Used" 6 " Not Used" 5 " Not Used" 4 " Not Used" 3 " Level 3" 2 " Level 2" 1 " Level 1" 0 " Level 0" ;
VAL_ 914 RemoteLockFeedbackSts 3 " Not used" 2 " Only speaker(Reserved)" 1 " Only lamp" 0 " Lamp and speaker" ;
VAL_ 914 BCM_4_DriverDoorLockSts 1 " Unlock" 0 " Lock" ;
VAL_ 914 DrvrDoorUnlckOnlySts 1 " Driver Door Unlock Only Mode" 0 " Not Driver Door Unlock Only Mode" ;
VAL_ 914 FGHeat_Req_CmdFeedback 1 " On" 0 " Off" ;
VAL_ 914 RearFoglightFaultSts 1 " Failure" 0 " Normal" ;
VAL_ 914 BCM_4_ChildSafetySts 3 " Failure" 2 " Lock" 1 " Unlock" 0 " Not Used" ;
VAL_ 914 WiperSensitivitySWSts 7 " Not Used" 6 " Not Used" 5 " High Sens" 4 " Med High Sens" 3 " Med Sens" 2 " Med Low Sens" 1 " Low Sens" 0 " Not active" ;
VAL_ 914 RainSensorFailSts 1 " Fail Present" 0 " Fail Not Present" ;
VAL_ 914 ReversinglampFaultSts 1 " Failure" 0 " Normal" ;
VAL_ 914 BCM_4_FrontFogLightSts 1 " Active" 0 " Off" ;
VAL_ 914 BrakelampFaultSts 1 " Failure" 0 " Normal" ;
VAL_ 914 BCM_4_ReverseGearSts 1 " Active" 0 " Off" ;
VAL_ 914 BCM_4_RearFogLightSts 1 " Active" 0 " Off" ;
VAL_ 914 BCM_4_TrunkSts 1 " Open" 0 " Close" ;
VAL_ 914 BCM_4_LHRdoorSts 1 " Open" 0 " Close" ;
VAL_ 914 BCM_4_RHRDoorSts 1 " Open" 0 " Close" ;
VAL_ 914 BCM_4_HoodSts 1 " Open" 0 " Close" ;
VAL_ 914 BCM_4_PsngrDoorSts 1 " Open" 0 " Close" ;
VAL_ 914 BCM_4_DriverDoorSts 1 " Open" 0 " Close" ;
VAL_ 914 FollowMeTimeSts 8 " Eight times" 7 " Seven times" 6 " Six times" 5 " Five times" 4 " Four times" 3 " Three times" 2 " Two times" 1 " One time" 0 " Not active" ;
VAL_ 914 RVSMode 1 " Active" 0 " Not active" ;
VAL_ 914 BCM_4_DirectionIndLeft 1 " Active" 0 " Not active" ;
VAL_ 914 BCM_4_DirectionIndRight 1 " Active" 0 " Not active" ;
VAL_ 914 BCM_4_DRLSts 1 " Active" 0 " Off" ;
VAL_ 914 BCM_4_HighBeamSts 1 " Active" 0 " Off" ;
VAL_ 914 BCM_4_ParkLightSts 1 " Active" 0 " Off" ;
VAL_ 914 BCM_4_LHTurnlightSts 1 " Active" 0 " Off" ;
VAL_ 914 BCM_4_RHTurnlightSts 1 " Active" 0 " Off" ;
VAL_ 914 BCM_4_KeySts 3 " CRANK + ON" 2 " ON" 1 " ACC" 0 " OFF" ;
VAL_ 914 LightDetected 1 " Bright" 0 " Dark" ;
VAL_ 914 KeyRemindWarning 1 " Active" 0 " Off" ;
VAL_ 914 ParkLightOnWarning 1 " Active" 0 " Off" ;
VAL_ 914 BCM_4_ArmingSts 3 " Invalid" 2 " Disarming successful" 1 " Arming successful" 0 " Not active" ;
VAL_ 1059 LDWWorkingSts 3 " Standby" 2 " Failure" 1 " On" 0 " Off" ;
VAL_ 1059 LDWWarningSts 3 " Not Used" 2 " Right Warning" 1 " Left Warning" 0 " Off" ;
VAL_ 1059 LDWLaneDetectionSts 3 " Both sides deteced" 2 " Only left lane deteced" 1 " Only right lane deteced" 0 " No detection of both sides" ;
VAL_ 1059 LDWSensitivitySettingFeedback 3 " High" 2 " Middle" 1 " Low" 0 " Not Used" ;
VAL_ 1059 LDWSwitchStsFeedback 1 " On" 0 " Off" ;
VAL_ 1088 RadarWorkSts 1 " Active" 0 " Not active" ;
VAL_ 1088 RadarDetectSts 3 " Not used" 2 " Rear Radar detecting" 1 " Front Radar detecting" 0 " No detecting" ;
VAL_ 1088 AudibleBeepRate 7 " Not used" 6 " Not used" 5 " Not used" 4 " 1Hz" 3 " 2Hz" 2 " 4Hz" 1 " On" 0 " Off" ;
VAL_ 1088 LHMFRadarSensorDistance 29 " Not used" 28 " Not used" ;
VAL_ 1088 RHMFRadarSensorDistance 29 " Not used" 28 " Not used" ;
VAL_ 1088 RHFRadarSensorDistance 29 " Not used" 28 " Not used" ;
VAL_ 1088 LHFRadarSensorDistance 29 " Not used" 28 " Not used" ;
VAL_ 1088 RHRRadarSensorDistance 61 " Not used" 60 " Not used" 59 " Not used" 58 " Not used" 57 " Not used" 56 " Not used" 55 " Not used" 54 " Not used" 53 " Not used" 52 " Not used" 51 " Not used" 50 " Not used" 49 " Not used" 48 " Not used" 47 " Not used" 46 " Not used" 45 " Not used" 44 " Not used" 43 " Not used" 42 " Not used" 41 " Not used" 40 " Not used" 39 " Not used" 38 " Not used" 37 " Not used" 36 " Not used" 35 " Not used" 34 " Not used" 33 " Not used" 32 " Not used" ;
VAL_ 1088 LHMRRadarSensorDistance 61 " Not used" 60 " Not used" 59 " Not used" 58 " Not used" 57 " Not used" 56 " Not used" 55 " Not used" 54 " Not used" 53 " Not used" 52 " Not used" 51 " Not used" 50 " Not used" 49 " Not used" 48 " Not used" 47 " Not used" 46 " Not used" 45 " Not used" 44 " Not used" 43 " Not used" 42 " Not used" 41 " Not used" 40 " Not used" 39 " Not used" 38 " Not used" 37 " Not used" 36 " Not used" 35 " Not used" 34 " Not used" 33 " Not used" 32 " Not used" ;
VAL_ 1088 RHMRRadarSensorDistance 61 " Not used" 60 " Not used" 59 " Not used" 58 " Not used" 57 " Not used" 56 " Not used" 55 " Not used" 54 " Not used" 53 " Not used" 52 " Not used" 51 " Not used" 50 " Not used" 49 " Not used" 48 " Not used" 47 " Not used" 46 " Not used" 45 " Not used" 44 " Not used" 43 " Not used" 42 " Not used" 41 " Not used" 40 " Not used" 39 " Not used" 38 " Not used" 37 " Not used" 36 " Not used" 35 " Not used" 34 " Not used" 33 " Not used" 32 " Not used" ;
VAL_ 1088 PDC_GongRR_1 1 " detected" 0 "No detecting" ;
VAL_ 1088 PDC_GongRL_1 1 " detected" 0 "No detecting" ;
VAL_ 1088 PDC_GongFR_1 1 " detected" 0 "No detecting" ;
VAL_ 1088 PDC_GongFL_1 1 " detected" 0 "No detecting" ;
VAL_ 1088 LHRRadarSensorDistance 61 " Not used" 60 " Not used" 59 " Not used" 58 " Not used" 57 " Not used" 56 " Not used" 55 " Not used" 54 " Not used" 53 " Not used" 52 " Not used" 51 " Not used" 50 " Not used" 49 " Not used" 48 " Not used" 47 " Not used" 46 " Not used" 45 " Not used" 44 " Not used" 43 " Not used" 42 " Not used" 41 " Not used" 40 " Not used" 39 " Not used" 38 " Not used" 37 " Not used" 36 " Not used" 35 " Not used" 34 " Not used" 33 " Not used" 32 " Not used" ;
